VERSION ""

NS_ :

BS_:

BU_: PowertrainControlModule AtmosphericSensor SafetyRestraintSystem2 Aftertreatment_2_GasOutlet Aftertreatment_2_GasIntake DieselPartFilterControl Turbocharger SafetyRestraintSystem1 CabDisplay2 Aftertreatment_1_GasOutlet Aftertreatment_1_GasIntake OnBoardDataLogger OffBoardDiagnosticTool2 OffBoardDiagnosticTool1 FileServer ParkingBrakeController SeatController2 FanDriveController SteeringColumnUnit CommunicationUnitRadio CommunicationUnitSatellite CommunicationUnitCellular PropulsionBatteryCharger ChassisController2 ChassisController1 EngineValveControl AuxiliaryHeater2 AuxiliaryHeater1 ClutchUnit RampControl InformationSystem1 SuspensionSystemController2 OilSensor VehicleDynamicStability ExhaustEmissionController TransmissionDisplay2 TransmissionDisplay1 ClimateControl2 WaterPumpController RearAxleSteeringController LightingOperatorControl SeatController1 IgnitionController2 IgnitionController1 TirePressureController CabController2 CabController1 PneumaticSystemController SuspensionSystemController1 HydraulicPumpController EnduranceBrakingSystem RetarderExhaustEngine2 OnBoardDiagnosticUnit HeadwayController RetarderExhaustEngine1 CabDisplay1 ManagementComputer VirtualTerminal OffVehicleGateway PowerTakeOffFront HitchControl AuxiliaryValveControl BodyController TractorTrailerBridge1 StarterSystem ElectricalSystem VehicleSecurity VehicleNavigation AerodynamicControl ElectricalChargingSystem ClimateControl1 TripRecorder InstrumentCluster SuspensionDriveAxle2 SuspensionDriveAxle1 SuspensionSteerAxle SteeringController FuelSystem CruiseControl RetarderDriveline RetarderEngine BrakesDriveAxle2 BrakesDriveAxle1 BrakesSystemController BrakesSteerAxle AxleDrive2 AxleDrive1 AxleSteering PowerTakeOff ShiftConsoleSecondary ShiftConsolePrimary Transmission2 Transmission1 Engine2 Engine1

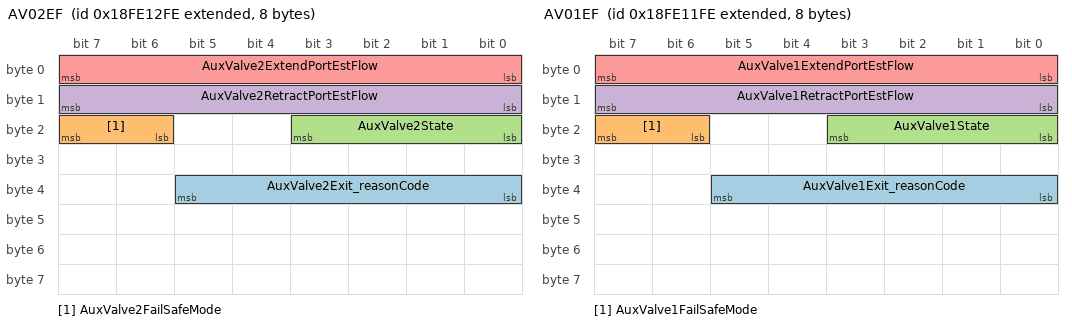
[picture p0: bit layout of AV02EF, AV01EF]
BO_ 2566787838 AV02EF: 8 Vector__XXX
 SG_ AuxValve2Exit_reasonCode : 32|6@1+ (1,0) [0|0] "" Vector__XXX
 SG_ AuxValve2FailSafeMode : 22|2@1+ (1,0) [0|0] "" Vector__XXX
 SG_ AuxValve2State : 16|4@1+ (1,0) [0|0] "" Vector__XXX
 SG_ AuxValve2RetractPortEstFlow : 8|8@1+ (1,0) [0|0] "" Vector__XXX
 SG_ AuxValve2ExtendPortEstFlow : 0|8@1+ (1,0) [0|0] "" Vector__XXX

BO_ 2566787582 AV01EF: 8 Vector__XXX
 SG_ AuxValve1Exit_reasonCode : 32|6@1+ (1,0) [0|0] "" Vector__XXX
 SG_ AuxValve1FailSafeMode : 22|2@1+ (1,0) [0|0] "" Vector__XXX
 SG_ AuxValve1State : 16|4@1+ (1,0) [0|0] "" Vector__XXX
 SG_ AuxValve1RetractPortEstFlow : 8|8@1+ (1,0) [0|0] "" Vector__XXX
 SG_ AuxValve1ExtendPortEstFlow : 0|8@1+ (1,0) [0|0] "" Vector__XXX

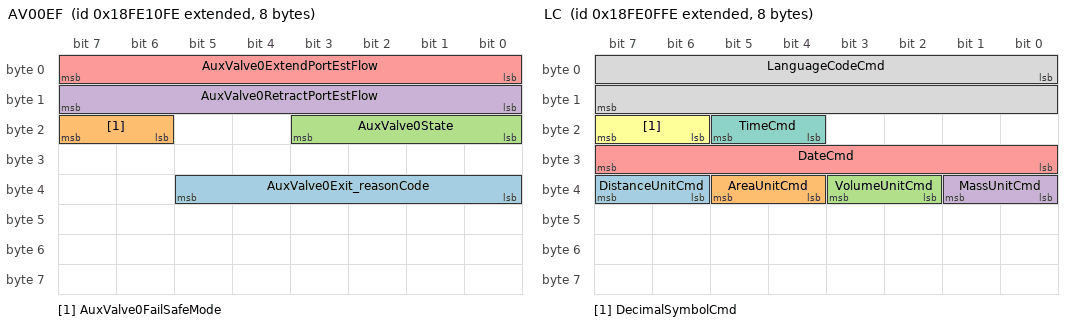
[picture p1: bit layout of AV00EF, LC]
BO_ 2566787326 AV00EF: 8 Vector__XXX
 SG_ AuxValve0Exit_reasonCode : 32|6@1+ (1,0) [0|0] "" Vector__XXX
 SG_ AuxValve0FailSafeMode : 22|2@1+ (1,0) [0|0] "" Vector__XXX
 SG_ AuxValve0State : 16|4@1+ (1,0) [0|0] "" Vector__XXX
 SG_ AuxValve0RetractPortEstFlow : 8|8@1+ (1,0) [0|0] "" Vector__XXX
 SG_ AuxValve0ExtendPortEstFlow : 0|8@1+ (1,0) [0|0] "" Vector__XXX

BO_ 2566787070 LC: 8 Vector__XXX
 SG_ DistanceUnitCmd : 38|2@1+ (1,0) [0|0] "" Vector__XXX
 SG_ AreaUnitCmd : 36|2@1+ (1,0) [0|0] "" Vector__XXX
 SG_ VolumeUnitCmd : 34|2@1+ (1,0) [0|0] "" Vector__XXX
 SG_ MassUnitCmd : 32|2@1+ (1,0) [0|0] "" Vector__XXX
 SG_ DateCmd : 24|8@1+ (1,0) [0|0] "" Vector__XXX
 SG_ DecimalSymbolCmd : 22|2@1+ (1,0) [0|0] "" Vector__XXX
 SG_ TimeCmd : 20|2@1+ (1,0) [0|0] "" Vector__XXX
 SG_ LanguageCodeCmd : 0|16@1+ (1,0) [0|0] "" Vector__XXX

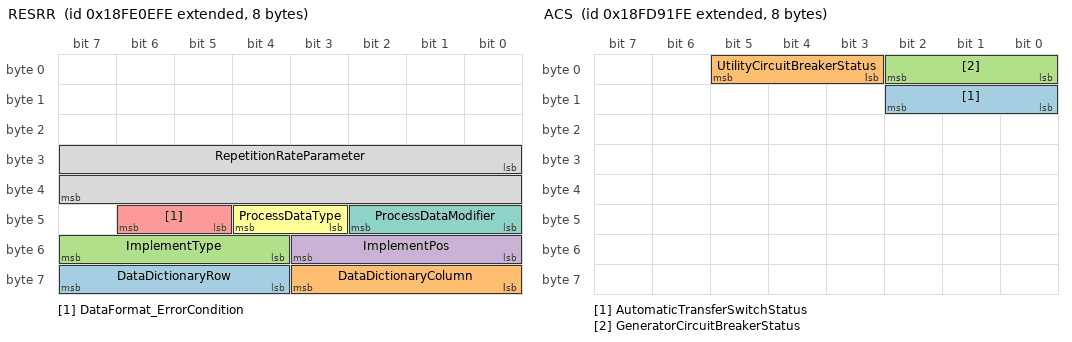
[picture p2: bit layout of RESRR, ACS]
BO_ 2566786814 RESRR: 8 Vector__XXX
 SG_ DataDictionaryRow : 60|4@1+ (1,0) [0|0] "" Vector__XXX
 SG_ DataDictionaryColumn : 56|4@1+ (1,0) [0|0] "" Vector__XXX
 SG_ ImplementType : 52|4@1+ (1,0) [0|0] "" Vector__XXX
 SG_ ImplementPos : 48|4@1+ (1,0) [0|0] "" Vector__XXX
 SG_ DataFormat_ErrorCondition : 45|2@1+ (1,0) [0|0] "" Vector__XXX
 SG_ ProcessDataType : 43|2@1+ (1,0) [0|0] "" Vector__XXX
 SG_ ProcessDataModifier : 40|3@1+ (1,0) [0|0] "" Vector__XXX
 SG_ RepetitionRateParameter : 24|16@1+ (1,0) [0|0] "" Vector__XXX

BO_ 2566786046 IRC: 8 Vector__XXX

BO_ 2566785790 IRCR: 8 Vector__XXX

BO_ 2566785534 TFR: 8 Vector__XXX
 SG_ TrctrFcltyRspLmt_RqstSttsRprting : 27|1@1+ (1,0) [0|0] "" Vector__XXX

BO_ 2566785278 RTF: 8 Vector__XXX
 SG_ TrctrFcltyRqLmt_RqstSttsRporting : 27|1@1+ (1,0) [0|0] "" Vector__XXX

BO_ 2566774526 MAM21: 8 Vector__XXX

BO_ 2566774270 MAM11: 8 Vector__XXX

BO_ 2566770686 WSM: 8 Vector__XXX
 SG_ NumberOfMembers : 0|8@1+ (1,0) [0|0] "" Vector__XXX

BO_ 2566770430 WSMM: 8 Vector__XXX
 SG_ NAMEOfWorkingSetMember : 0|64@1+ (1,0) [0|0] "" Vector__XXX

BO_ 2566761470 RCMS: 8 Vector__XXX
 SG_ PGNOfConfigurableMessageDesired : 8|24@1+ (1,0) [0|16777215] "" Vector__XXX
 SG_ MessageSelectionCtrl : 0|8@1+ (1,0) [0|250] "" Vector__XXX

BO_ 2566754814 ACS: 8 Vector__XXX
 SG_ AutomaticTransferSwitchStatus : 8|3@1+ (1,0) [0|7] "" Vector__XXX
 SG_ UtilityCircuitBreakerStatus : 3|3@1+ (1,0) [0|7] "" Vector__XXX
 SG_ GeneratorCircuitBreakerStatus : 0|3@1+ (1,0) [0|7] "" Vector__XXX

BO_ 2566754302 GTACPP: 8 Vector__XXX
 SG_ GeneratorTotalPercentKVAr : 32|16@1+ (0.0078125,-251) [-251|250.99] "%" Vector__XXX
 SG_ GeneratorTotalPercentKVA : 16|16@1+ (0.0078125,-251) [-251|250.99] "%" Vector__XXX
 SG_ GeneratorTotalPercentKW : 0|16@1+ (0.0078125,-251) [-251|250.99] "%" Vector__XXX

BO_ 2566754046 GTACER: 8 Vector__XXX
 SG_ GeneratorTotalKVArHoursImport : 32|32@1+ (1,0) [0|4211081215] "kVArh" Vector__XXX
 SG_ GeneratorTotalKVArHoursExport : 0|32@1+ (1,0) [0|4211081215] "kVArh" Vector__XXX

BO_ 2566753790 UTACER: 8 Vector__XXX
 SG_ UtilityTotalKVArHoursImport : 32|32@1+ (1,0) [0|4211081215] "kVArh" Vector__XXX
 SG_ UtilityTotalKVArHoursExport : 0|32@1+ (1,0) [0|4211081215] "kVArh" Vector__XXX

BO_ 2566738174 GPM19: 8 Vector__XXX

BO_ 2566737918 GPM26: 8 Vector__XXX

BO_ 2566737662 GPM27: 8 Vector__XXX

BO_ 2566737406 GPM28: 8 Vector__XXX

BO_ 2566737150 GPM29: 8 Vector__XXX

BO_ 2566736894 GPM210: 8 Vector__XXX

BO_ 2566736638 GPM211: 8 Vector__XXX

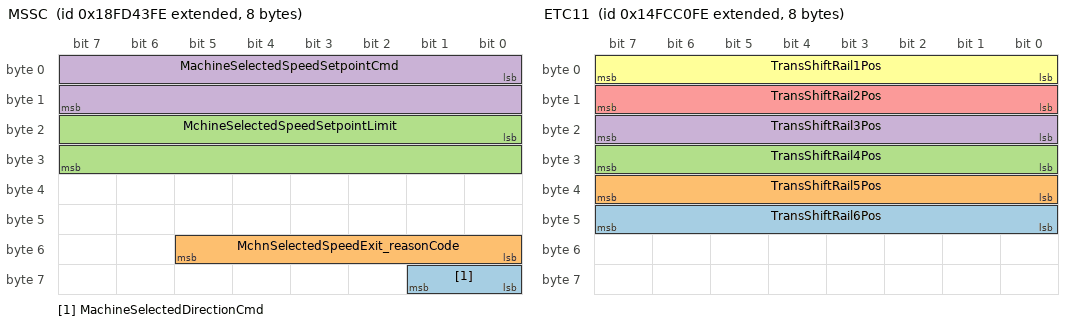
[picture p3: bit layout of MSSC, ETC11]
BO_ 2566734846 MSSC: 8 Vector__XXX
 SG_ MachineSelectedDirectionCmd : 56|2@1+ (1,0) [0|0] "" Vector__XXX
 SG_ MchnSelectedSpeedExit_reasonCode : 48|6@1+ (1,0) [0|0] "" Vector__XXX
 SG_ MchineSelectedSpeedSetpointLimit : 16|16@1+ (1,0) [0|0] "" Vector__XXX
 SG_ MachineSelectedSpeedSetpointCmd : 0|16@1+ (1,0) [0|0] "" Vector__XXX

BO_ 2566734590 ICC: 8 Vector__XXX
 SG_ ISOBUSCmplncCrtfctnMssgeRevision : 47|1@1+ (1,0) [0|0] "" Vector__XXX
 SG_ ISOBUSCmplncCrtfctnRfrenceNumber : 48|16@1+ (1,0) [0|0] "" Vector__XXX
 SG_ ISOBUSCmplncCrtfctonTypeTaskCtrl : 39|1@1+ (1,0) [0|0] "" Vector__XXX
 SG_ ISOBUSCmplncCrtfctnTypTCWrkn4326 : 38|1@1+ (1,0) [0|0] "" Vector__XXX
 SG_ ISOBUSCmplncCrtfctnTypTCWrkngStM : 37|1@1+ (1,0) [0|0] "" Vector__XXX
 SG_ ISOBUSCmplncCrtfctnTypFileServer : 36|1@1+ (1,0) [0|0] "" Vector__XXX
 SG_ ISOBUSCmplncCrtfctnTypGPSRceiver : 35|1@1+ (1,0) [0|0] "" Vector__XXX
 SG_ ISOBUSCmplncCrtfcationTypeMinECU : 31|1@1+ (1,0) [0|0] "" Vector__XXX
 SG_ ISOBUSCmplncCrtfctnTypTECUClass1 : 30|1@1+ (1,0) [0|0] "" Vector__XXX
 SG_ ISOBUSCmplncCrtfctnTypTECUClass2 : 29|1@1+ (1,0) [0|0] "" Vector__XXX
 SG_ ISOBUSCmplncCrtfctnTypTECUClass3 : 28|1@1+ (1,0) [0|0] "" Vector__XXX
 SG_ ISOBUSCmplncCrtfctnTypeClass3ECU : 27|1@1+ (1,0) [0|0] "" Vector__XXX
 SG_ ISOBUSCmplncCrtfctnTypVrtlTrmnal : 26|1@1+ (1,0) [0|0] "" Vector__XXX
 SG_ ISOBUSCmplncCrtfctnTypVTWrkn4323 : 25|1@1+ (1,0) [0|0] "" Vector__XXX
 SG_ ISOBUSCmplncCrtfctnTypVTWrkngStM : 24|1@1+ (1,0) [0|0] "" Vector__XXX
 SG_ ISOBUSCmplncCrtfctonLaboratoryID : 13|11@1+ (1,0) [0|0] "" Vector__XXX
 SG_ ISOBUSCmplncCrtfctLaboratoryType : 9|3@1+ (1,0) [0|0] "" Vector__XXX
 SG_ ISOBUSCmplnceCertificateRevision : 6|3@1+ (1,0) [0|0] "" Vector__XXX
 SG_ ISOBUSCmplianceCertificationYear : 0|6@1+ (1,0) [0|0] "" Vector__XXX

BO_ 2566730494 TBD: 8 Vector__XXX

BO_ 2566718462 IOS: 8 Vector__XXX
 SG_ ImplementOperatingStateCmd : 56|2@1+ (1,0) [0|0] "" Vector__XXX

BO_ 2566718206 AISO: 8 Vector__XXX
 SG_ StpAllImplmntOprtnsTrnstonNumber : 48|8@1+ (1,0) [0|0] "" Vector__XXX
 SG_ AllImplmntStpOprtngOprtnsSwtchSt : 56|2@1+ (1,0) [0|0] "" Vector__XXX

BO_ 2566706430 XCP_ID: 8 Vector__XXX

BO_ 2566704894 DSC: 8 Vector__XXX

BO_ 2566704638 DSS: 8 Vector__XXX

BO_ 2566701566 TRF3: 8 Vector__XXX
 SG_ TransOilTransCoolerOutletTemp : 8|8@1+ (1,-40) [-40|210] "°C" Vector__XXX
 SG_ TransClutch2Press : 0|8@1+ (16,0) [0|4000] "kPa" Vector__XXX

BO_ 2499592446 ETC11: 8 Vector__XXX
 SG_ TransShiftRail6Pos : 40|8@1+ (0.4,0) [0|100] "%" Vector__XXX
 SG_ TransShiftRail5Pos : 32|8@1+ (0.4,0) [0|100] "%" Vector__XXX
 SG_ TransShiftRail4Pos : 24|8@1+ (0.4,0) [0|100] "%" Vector__XXX
 SG_ TransShiftRail3Pos : 16|8@1+ (0.4,0) [0|100] "%" Vector__XXX
 SG_ TransShiftRail2Pos : 8|8@1+ (0.4,0) [0|100] "%" Vector__XXX
 SG_ TransShiftRail1Pos : 0|8@1+ (0.4,0) [0|100] "%" Vector__XXX

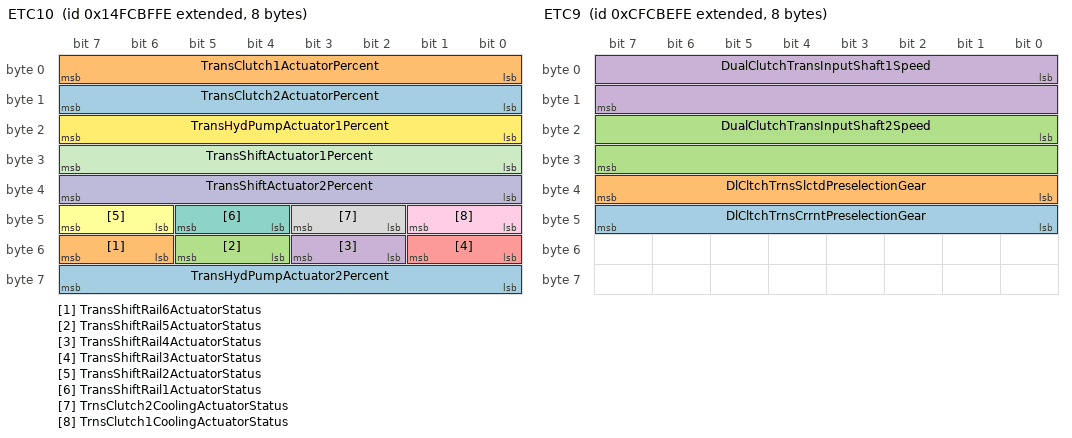
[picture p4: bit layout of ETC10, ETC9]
BO_ 2499592190 ETC10: 8 Vector__XXX
 SG_ TransHydPumpActuator2Percent : 56|8@1+ (0.4,0) [0|100] "%" Vector__XXX
 SG_ TransShiftRail6ActuatorStatus : 54|2@1+ (1,0) [0|3] "" Vector__XXX
 SG_ TransShiftRail5ActuatorStatus : 52|2@1+ (1,0) [0|3] "" Vector__XXX
 SG_ TransShiftRail4ActuatorStatus : 50|2@1+ (1,0) [0|3] "" Vector__XXX
 SG_ TransShiftRail3ActuatorStatus : 48|2@1+ (1,0) [0|3] "" Vector__XXX
 SG_ TransShiftRail2ActuatorStatus : 46|2@1+ (1,0) [0|3] "" Vector__XXX
 SG_ TransShiftRail1ActuatorStatus : 44|2@1+ (1,0) [0|3] "" Vector__XXX
 SG_ TrnsClutch2CoolingActuatorStatus : 42|2@1+ (1,0) [0|3] "" Vector__XXX
 SG_ TrnsClutch1CoolingActuatorStatus : 40|2@1+ (1,0) [0|3] "" Vector__XXX
 SG_ TransShiftActuator2Percent : 32|8@1+ (0.4,0) [0|100] "%" Vector__XXX
 SG_ TransShiftActuator1Percent : 24|8@1+ (0.4,0) [0|100] "%" Vector__XXX
 SG_ TransHydPumpActuator1Percent : 16|8@1+ (0.4,0) [0|100] "%" Vector__XXX
 SG_ TransClutch2ActuatorPercent : 8|8@1+ (0.4,0) [0|100] "%" Vector__XXX
 SG_ TransClutch1ActuatorPercent : 0|8@1+ (0.4,0) [0|100] "%" Vector__XXX

BO_ 2365374206 ETC9: 8 Vector__XXX
 SG_ DlCltchTrnsCrrntPreselectionGear : 40|8@1+ (1,-125) [-125|125] "" Vector__XXX
 SG_ DlCltchTrnsSlctdPreselectionGear : 32|8@1+ (1,-125) [-125|125] "" Vector__XXX
 SG_ DualClutchTransInputShaft2Speed : 16|16@1+ (0.125,0) [0|8031.875] "rpm" Vector__XXX
 SG_ DualClutchTransInputShaft1Speed : 0|16@1+ (0.125,0) [0|8031.875] "rpm" Vector__XXX

BO_ 2566700542 A1SCRSI2: 8 Vector__XXX
 SG_ TripDEF : 32|32@1+ (0.05,0) [0|210554060.75] "L" Vector__XXX
 SG_ TotalDEFUsed : 0|32@1+ (0.5,0) [0|2105540607.5] "L" Vector__XXX

BO_ 2566700286 A2SCRSI2: 8 Vector__XXX
 SG_ TotalDEFUsed : 0|32@1+ (0.5,0) [0|2105540607.5] "L" Vector__XXX

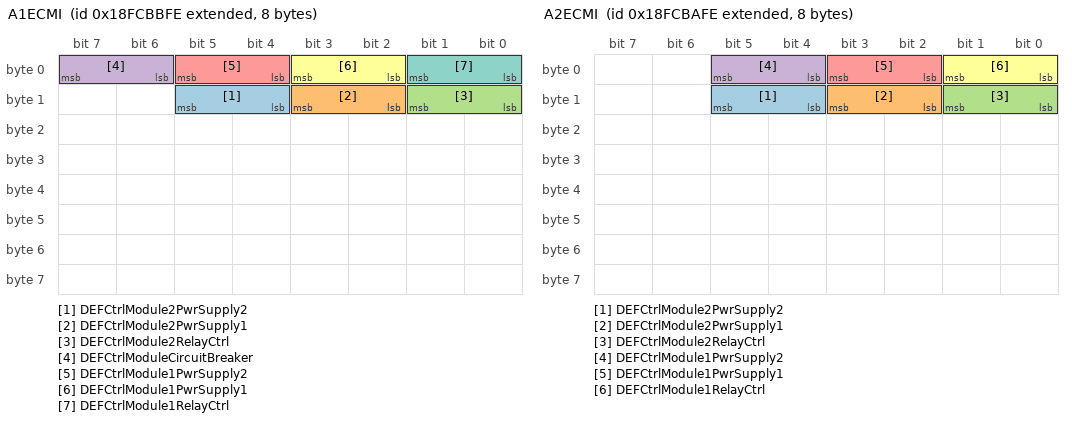
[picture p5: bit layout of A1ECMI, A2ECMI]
BO_ 2566700030 A1ECMI: 8 Vector__XXX
 SG_ DEFCtrlModule2PwrSupply2 : 12|2@1+ (1,0) [0|3] "" Vector__XXX
 SG_ DEFCtrlModule2PwrSupply1 : 10|2@1+ (1,0) [0|3] "" Vector__XXX
 SG_ DEFCtrlModule2RelayCtrl : 8|2@1+ (1,0) [0|3] "" Vector__XXX
 SG_ DEFCtrlModuleCircuitBreaker : 6|2@1+ (1,0) [0|3] "" Vector__XXX
 SG_ DEFCtrlModule1PwrSupply2 : 4|2@1+ (1,0) [0|3] "" Vector__XXX
 SG_ DEFCtrlModule1PwrSupply1 : 2|2@1+ (1,0) [0|3] "" Vector__XXX
 SG_ DEFCtrlModule1RelayCtrl : 0|2@1+ (1,0) [0|3] "" Vector__XXX

BO_ 2566699774 A2ECMI: 8 Vector__XXX
 SG_ DEFCtrlModule2PwrSupply2 : 12|2@1+ (1,0) [0|3] "" Vector__XXX
 SG_ DEFCtrlModule2PwrSupply1 : 10|2@1+ (1,0) [0|3] "" Vector__XXX
 SG_ DEFCtrlModule2RelayCtrl : 8|2@1+ (1,0) [0|3] "" Vector__XXX
 SG_ DEFCtrlModule1PwrSupply2 : 4|2@1+ (1,0) [0|3] "" Vector__XXX
 SG_ DEFCtrlModule1PwrSupply1 : 2|2@1+ (1,0) [0|3] "" Vector__XXX
 SG_ DEFCtrlModule1RelayCtrl : 0|2@1+ (1,0) [0|3] "" Vector__XXX

BO_ 2566699518 AT1S2: 8 Vector__XXX
 SG_ SCRSysTimeSinceLastSysCleanEvent : 32|32@1+ (1,0) [0|4211081215] "s" Vector__XXX
 SG_ DPFTimeToNextActiveRegen : 0|32@1+ (1,0) [0|4211081215] "s" Vector__XXX

BO_ 2566699262 AT2S2: 8 Vector__XXX
 SG_ SCRSysTimeSinceLastSysCleanEvent : 32|32@1+ (1,0) [0|4211081215] "s" Vector__XXX
 SG_ DPFTimeToNextActiveRegen : 0|32@1+ (1,0) [0|4211081215] "s" Vector__XXX

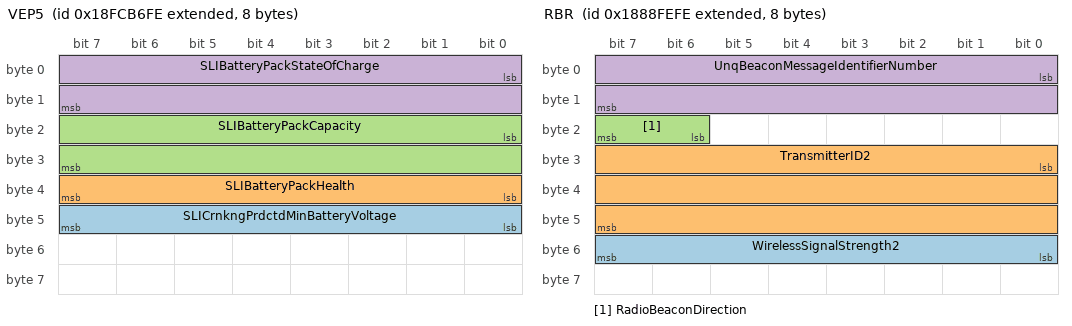
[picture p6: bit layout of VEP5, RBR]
BO_ 2566698750 VEP5: 8 Vector__XXX
 SG_ SLICrnkngPrdctdMinBatteryVoltage : 40|8@1+ (0.2,0) [0|50] "V" Vector__XXX
 SG_ SLIBatteryPackHealth : 32|8@1+ (0.5,0) [0|100] "%" Vector__XXX
 SG_ SLIBatteryPackCapacity : 16|16@1+ (1,0) [0|64255] "Ah" Vector__XXX
 SG_ SLIBatteryPackStateOfCharge : 0|16@1+ (0.0025,0) [0|160.6375] "%" Vector__XXX

BO_ 2566698494 FPOS: 8 Vector__XXX
 SG_ FusedOutput29 : 62|2@1+ (1,0) [0|3] "" Vector__XXX
 SG_ FusedOutput30 : 60|2@1+ (1,0) [0|3] "" Vector__XXX
 SG_ FusedOutput31 : 58|2@1+ (1,0) [0|3] "" Vector__XXX
 SG_ FusedOutput32 : 56|2@1+ (1,0) [0|3] "" Vector__XXX
 SG_ FusedOutput25 : 54|2@1+ (1,0) [0|3] "" Vector__XXX
 SG_ FusedOutput26 : 52|2@1+ (1,0) [0|3] "" Vector__XXX
 SG_ FusedOutput27 : 50|2@1+ (1,0) [0|3] "" Vector__XXX
 SG_ FusedOutput28 : 48|2@1+ (1,0) [0|3] "" Vector__XXX
 SG_ FusedOutput21 : 46|2@1+ (1,0) [0|3] "" Vector__XXX
 SG_ FusedOutput22 : 44|2@1+ (1,0) [0|3] "" Vector__XXX
 SG_ FusedOutput23 : 42|2@1+ (1,0) [0|3] "" Vector__XXX
 SG_ FusedOutput24 : 40|2@1+ (1,0) [0|3] "" Vector__XXX
 SG_ FusedOutput17 : 38|2@1+ (1,0) [0|3] "" Vector__XXX
 SG_ FusedOutput18 : 36|2@1+ (1,0) [0|3] "" Vector__XXX
 SG_ FusedOutput19 : 34|2@1+ (1,0) [0|3] "" Vector__XXX
 SG_ FusedOutput20 : 32|2@1+ (1,0) [0|3] "" Vector__XXX
 SG_ FusedOutput13 : 30|2@1+ (1,0) [0|3] "" Vector__XXX
 SG_ FusedOutput14 : 27|2@1+ (1,0) [0|3] "" Vector__XXX
 SG_ FusedOutput15 : 26|2@1+ (1,0) [0|3] "" Vector__XXX
 SG_ FusedOutput16 : 24|2@1+ (1,0) [0|3] "" Vector__XXX
 SG_ FusedOutput9 : 22|2@1+ (1,0) [0|3] "" Vector__XXX
 SG_ FusedOutput10 : 20|2@1+ (1,0) [0|3] "" Vector__XXX
 SG_ FusedOutput11 : 18|2@1+ (1,0) [0|3] "" Vector__XXX
 SG_ FusedOutput12 : 16|2@1+ (1,0) [0|3] "" Vector__XXX
 SG_ FusedOutput5 : 14|2@1+ (1,0) [0|3] "" Vector__XXX
 SG_ FusedOutput6 : 12|2@1+ (1,0) [0|3] "" Vector__XXX
 SG_ FusedOutput7 : 10|2@1+ (1,0) [0|3] "" Vector__XXX
 SG_ FusedOutput8 : 8|2@1+ (1,0) [0|3] "" Vector__XXX
 SG_ FusedOutput1 : 6|2@1+ (1,0) [0|3] "" Vector__XXX
 SG_ FusedOutput2 : 4|2@1+ (1,0) [0|3] "" Vector__XXX
 SG_ FusedOutput3 : 2|2@1+ (1,0) [0|3] "" Vector__XXX
 SG_ FusedOutput4 : 0|2@1+ (1,0) [0|3] "" Vector__XXX

BO_ 2559115006 RBR: 8 Vector__XXX
 SG_ WirelessSignalStrength2 : 48|8@1+ (0.5,-125) [-125|0] "dBm" Vector__XXX
 SG_ TransmitterID2 : 24|24@1+ (1,0) [0|16449635] "" Vector__XXX
 SG_ RadioBeaconDirection : 22|2@1+ (1,0) [0|3] "" Vector__XXX
 SG_ UnqBeaconMessageIdentifierNumber : 0|16@1+ (1,0) [0|64255] "" Vector__XXX

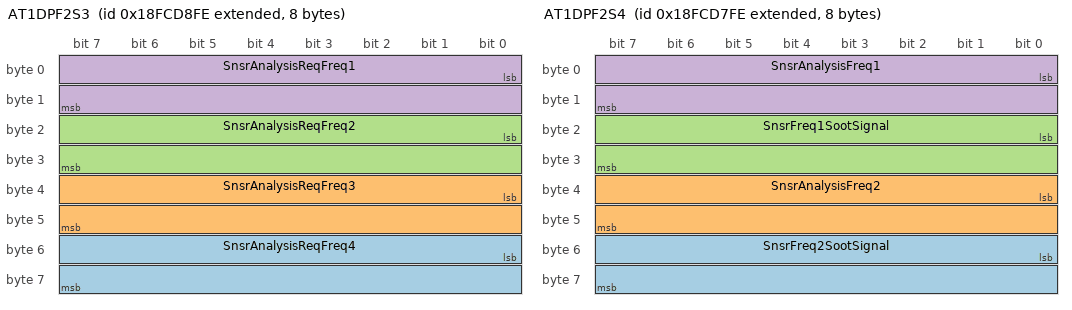
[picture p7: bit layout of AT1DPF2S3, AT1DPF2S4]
BO_ 2566707454 AT1DPF2S3: 8 Vector__XXX
 SG_ SnsrAnalysisReqFreq4 : 48|16@1+ (0.1,0) [0|6425.5] "MHz" Vector__XXX
 SG_ SnsrAnalysisReqFreq3 : 32|16@1+ (0.1,0) [0|6425.5] "MHz" Vector__XXX
 SG_ SnsrAnalysisReqFreq2 : 16|16@1+ (0.1,0) [0|6425.5] "MHz" Vector__XXX
 SG_ SnsrAnalysisReqFreq1 : 0|16@1+ (0.1,0) [0|6425.5] "MHz" Vector__XXX

BO_ 2566707198 AT1DPF2S4: 8 Vector__XXX
 SG_ SnsrFreq2SootSignal : 48|16@1+ (0.0025,0) [0|160.6375] "%" Vector__XXX
 SG_ SnsrAnalysisFreq2 : 32|16@1+ (0.1,0) [0|6425.5] "MHz" Vector__XXX
 SG_ SnsrFreq1SootSignal : 16|16@1+ (0.0025,0) [0|160.6375] "%" Vector__XXX
 SG_ SnsrAnalysisFreq1 : 0|16@1+ (0.1,0) [0|6425.5] "MHz" Vector__XXX

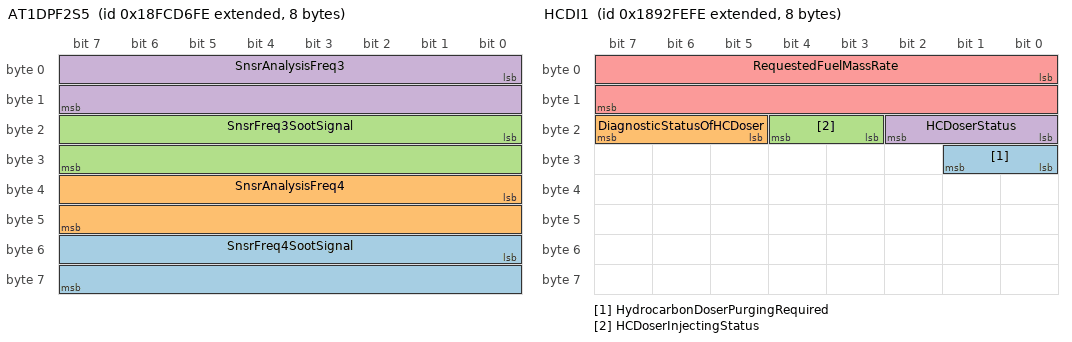
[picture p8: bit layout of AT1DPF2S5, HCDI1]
BO_ 2566706942 AT1DPF2S5: 8 Vector__XXX
 SG_ SnsrFreq4SootSignal : 48|16@1+ (0.0025,0) [0|160.6375] "%" Vector__XXX
 SG_ SnsrAnalysisFreq4 : 32|16@1+ (0.1,0) [0|6425.5] "MHz" Vector__XXX
 SG_ SnsrFreq3SootSignal : 16|16@1+ (0.0025,0) [0|160.6375] "%" Vector__XXX
 SG_ SnsrAnalysisFreq3 : 0|16@1+ (0.1,0) [0|6425.5] "MHz" Vector__XXX

BO_ 2559770366 HCDI1: 8 Vector__XXX
 SG_ HydrocarbonDoserPurgingRequired : 24|2@1+ (1,0) [0|3] "" Vector__XXX
 SG_ DiagnosticStatusOfHCDoser : 21|3@1+ (1,0) [0|7] "" Vector__XXX
 SG_ HCDoserInjectingStatus : 19|2@1+ (1,0) [0|3] "" Vector__XXX
 SG_ HCDoserStatus : 16|3@1+ (1,0) [0|7] "" Vector__XXX
 SG_ RequestedFuelMassRate : 0|16@1+ (0.05,0) [0|3212.75] "g/min" Vector__XXX

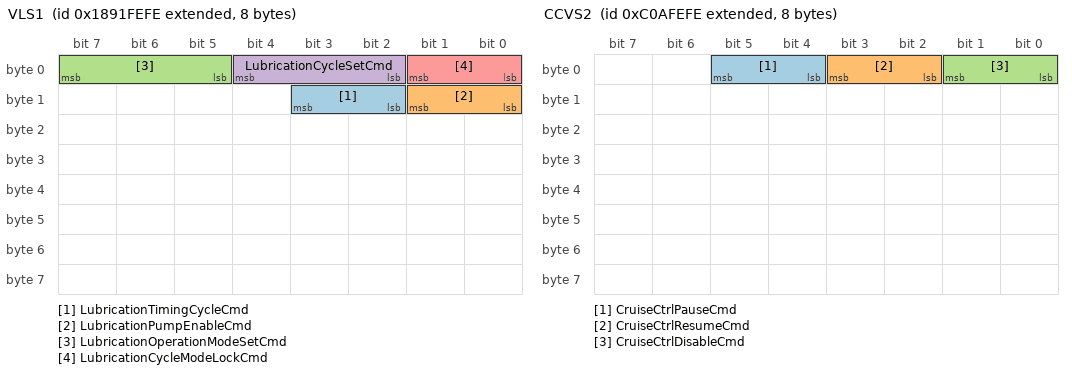
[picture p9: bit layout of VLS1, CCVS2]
BO_ 2559704830 VLS1: 8 Vector__XXX
 SG_ LubricationTimingCycleCmd : 10|2@1+ (1,0) [0|3] "" Vector__XXX
 SG_ LubricationPumpEnableCmd : 8|2@1+ (1,0) [0|3] "" Vector__XXX
 SG_ LubricationOperationModeSetCmd : 5|3@1+ (1,0) [0|7] "" Vector__XXX
 SG_ LubricationCycleSetCmd : 2|3@1+ (1,0) [0|7] "" Vector__XXX
 SG_ LubricationCycleModeLockCmd : 0|2@1+ (1,0) [0|3] "" Vector__XXX

BO_ 2559639294 SFC: 8 Vector__XXX
 SG_ SupplementalFanPowerHold : 24|2@1+ (1,0) [0|3] "" Vector__XXX
 SG_ SupplementalFanSpeedCmd : 8|16@1+ (0.5,0) [0|32127.5] "rpm" Vector__XXX
 SG_ SupplementalFanDirectionCmd : 2|2@1+ (1,0) [0|3] "" Vector__XXX
 SG_ SupplementalFanEnableCmd : 0|2@1+ (1,0) [0|3] "" Vector__XXX

BO_ 2559573758 ECC: 8 Vector__XXX
 SG_ ClntLvlEngPrtctnShtdwnOvrrideCmd : 0|2@1+ (1,0) [0|3] "" Vector__XXX

BO_ 2349530878 CCVS2: 8 Vector__XXX
 SG_ CruiseCtrlPauseCmd : 4|2@1+ (1,0) [0|3] "" Vector__XXX
 SG_ CruiseCtrlResumeCmd : 2|2@1+ (1,0) [0|3] "" Vector__XXX
 SG_ CruiseCtrlDisableCmd : 0|2@1+ (1,0) [0|3] "" Vector__XXX

BO_ 2566698238 SPOS: 8 Vector__XXX
 SG_ SwitchedOutput29 : 62|2@1+ (1,0) [0|3] "" Vector__XXX
 SG_ SwitchedOutput30 : 60|2@1+ (1,0) [0|3] "" Vector__XXX
 SG_ SwitchedOutput31 : 58|2@1+ (1,0) [0|3] "" Vector__XXX
 SG_ SwitchedOutput32 : 56|2@1+ (1,0) [0|3] "" Vector__XXX
 SG_ SwitchedOutput25 : 54|2@1+ (1,0) [0|3] "" Vector__XXX
 SG_ SwitchedOutput26 : 52|2@1+ (1,0) [0|3] "" Vector__XXX
 SG_ SwitchedOutput27 : 50|2@1+ (1,0) [0|3] "" Vector__XXX
 SG_ SwitchedOutput28 : 48|2@1+ (1,0) [0|3] "" Vector__XXX
 SG_ SwitchedOutput21 : 46|2@1+ (1,0) [0|3] "" Vector__XXX
 SG_ SwitchedOutput22 : 44|2@1+ (1,0) [0|3] "" Vector__XXX
 SG_ SwitchedOutput23 : 42|2@1+ (1,0) [0|3] "" Vector__XXX
 SG_ SwitchedOutput24 : 40|2@1+ (1,0) [0|3] "" Vector__XXX
 SG_ SwitchedOutput17 : 38|2@1+ (1,0) [0|3] "" Vector__XXX
 SG_ SwitchedOutput18 : 36|2@1+ (1,0) [0|3] "" Vector__XXX
 SG_ SwitchedOutput19 : 34|2@1+ (1,0) [0|3] "" Vector__XXX
 SG_ SwitchedOutput20 : 32|2@1+ (1,0) [0|3] "" Vector__XXX
 SG_ SwitchedOutput13 : 30|2@1+ (1,0) [0|3] "" Vector__XXX
 SG_ SwitchedOutput14 : 27|2@1+ (1,0) [0|3] "" Vector__XXX
 SG_ SwitchedOutput15 : 26|2@1+ (1,0) [0|3] "" Vector__XXX
 SG_ SwitchedOutput16 : 24|2@1+ (1,0) [0|3] "" Vector__XXX
 SG_ SwitchedOutput9 : 22|2@1+ (1,0) [0|3] "" Vector__XXX
 SG_ SwitchedOutput10 : 20|2@1+ (1,0) [0|3] "" Vector__XXX
 SG_ SwitchedOutput11 : 18|2@1+ (1,0) [0|3] "" Vector__XXX
 SG_ SwitchedOutput12 : 16|2@1+ (1,0) [0|3] "" Vector__XXX
 SG_ SwitchedOutput5 : 14|2@1+ (1,0) [0|3] "" Vector__XXX
 SG_ SwitchedOutput6 : 12|2@1+ (1,0) [0|3] "" Vector__XXX
 SG_ SwitchedOutput7 : 10|2@1+ (1,0) [0|3] "" Vector__XXX
 SG_ SwitchedOutput8 : 8|2@1+ (1,0) [0|3] "" Vector__XXX
 SG_ SwitchedOutput1 : 6|2@1+ (1,0) [0|3] "" Vector__XXX
 SG_ SwitchedOutput2 : 4|2@1+ (1,0) [0|3] "" Vector__XXX
 SG_ SwitchedOutput3 : 2|2@1+ (1,0) [0|3] "" Vector__XXX
 SG_ SwitchedOutput4 : 0|2@1+ (1,0) [0|3] "" Vector__XXX

BO_ 2566697982 FPOC: 64 Vector__XXX
 SG_ FusedOutput32Current : 496|16@1+ (0.005,0) [0|321.275] "A" Vector__XXX
 SG_ FusedOutput31Current : 480|16@1+ (0.005,0) [0|321.275] "A" Vector__XXX
 SG_ FusedOutput30Current : 464|16@1+ (0.005,0) [0|321.275] "A" Vector__XXX
 SG_ FusedOutput29Current : 448|16@1+ (0.005,0) [0|321.275] "A" Vector__XXX
 SG_ FusedOutput28Current : 432|16@1+ (0.005,0) [0|321.275] "A" Vector__XXX
 SG_ FusedOutput27Current : 416|16@1+ (0.005,0) [0|321.275] "A" Vector__XXX
 SG_ FusedOutput26Current : 400|16@1+ (0.005,0) [0|321.275] "A" Vector__XXX
 SG_ FusedOutput25Current : 384|16@1+ (0.005,0) [0|321.275] "A" Vector__XXX
 SG_ FusedOutput24Current : 368|16@1+ (0.005,0) [0|321.275] "A" Vector__XXX
 SG_ FusedOutput23Current : 352|16@1+ (0.005,0) [0|321.275] "A" Vector__XXX
 SG_ FusedOutput22Current : 336|16@1+ (0.005,0) [0|321.275] "A" Vector__XXX
 SG_ FusedOutput21Current : 320|16@1+ (0.005,0) [0|321.275] "A" Vector__XXX
 SG_ FusedOutput20Current : 304|16@1+ (0.005,0) [0|321.275] "A" Vector__XXX
 SG_ FusedOutput19Current : 288|16@1+ (0.005,0) [0|321.275] "A" Vector__XXX
 SG_ FusedOutput18Current : 272|16@1+ (0.005,0) [0|321.275] "A" Vector__XXX
 SG_ FusedOutput17Current : 256|16@1+ (0.005,0) [0|321.275] "A" Vector__XXX
 SG_ FusedOutput16Current : 240|16@1+ (0.005,0) [0|321.275] "A" Vector__XXX
 SG_ FusedOutput15Current : 224|16@1+ (0.005,0) [0|321.275] "A" Vector__XXX
 SG_ FusedOutput14Current : 208|16@1+ (0.005,0) [0|321.275] "A" Vector__XXX
 SG_ FusedOutput13Current : 192|16@1+ (0.005,0) [0|321.275] "A" Vector__XXX
 SG_ FusedOutput12Current : 176|16@1+ (0.005,0) [0|321.275] "A" Vector__XXX
 SG_ FusedOutput11Current : 160|16@1+ (0.005,0) [0|321.275] "A" Vector__XXX
 SG_ FusedOutput10Current : 144|16@1+ (0.005,0) [0|321.275] "A" Vector__XXX
 SG_ FusedOutput9Current : 128|16@1+ (0.005,0) [0|321.275] "A" Vector__XXX
 SG_ FusedOutput8Current : 112|16@1+ (0.005,0) [0|321.275] "A" Vector__XXX
 SG_ FusedOutput7Current : 96|16@1+ (0.005,0) [0|321.275] "A" Vector__XXX
 SG_ FusedOutput6Current : 80|16@1+ (0.005,0) [0|321.275] "A" Vector__XXX
 SG_ FusedOutput5Current : 64|16@1+ (0.005,0) [0|321.275] "A" Vector__XXX
 SG_ FusedOutput4Current : 48|16@1+ (0.005,0) [0|321.275] "A" Vector__XXX
 SG_ FusedOutput3Current : 32|16@1+ (0.005,0) [0|321.275] "A" Vector__XXX
 SG_ FusedOutput2Current : 16|16@1+ (0.005,0) [0|321.275] "A" Vector__XXX
 SG_ FusedOutput1Current : 0|16@1+ (0.005,0) [0|321.275] "A" Vector__XXX

BO_ 2566697726 SPOC1: 64 Vector__XXX
 SG_ SwitchedOutput32Current : 496|16@1+ (0.005,0) [0|321.275] "A" Vector__XXX
 SG_ SwitchedOutput31Current : 480|16@1+ (0.005,0) [0|321.275] "A" Vector__XXX
 SG_ SwitchedOutput30Current : 464|16@1+ (0.005,0) [0|321.275] "A" Vector__XXX
 SG_ SwitchedOutput29Current : 448|16@1+ (0.005,0) [0|321.275] "A" Vector__XXX
 SG_ SwitchedOutput28Current : 432|16@1+ (0.005,0) [0|321.275] "A" Vector__XXX
 SG_ SwitchedOutput27Current : 416|16@1+ (0.005,0) [0|321.275] "A" Vector__XXX
 SG_ SwitchedOutput26Current : 400|16@1+ (0.005,0) [0|321.275] "A" Vector__XXX
 SG_ SwitchedOutput25Current : 384|16@1+ (0.005,0) [0|321.275] "A" Vector__XXX
 SG_ SwitchedOutput24Current : 368|16@1+ (0.005,0) [0|321.275] "A" Vector__XXX
 SG_ SwitchedOutput23Current : 352|16@1+ (0.005,0) [0|321.275] "A" Vector__XXX
 SG_ SwitchedOutput22Current : 336|16@1+ (0.005,0) [0|321.275] "A" Vector__XXX
 SG_ SwitchedOutput21Current : 320|16@1+ (0.005,0) [0|321.275] "A" Vector__XXX
 SG_ SwitchedOutput20Current : 304|16@1+ (0.005,0) [0|321.275] "A" Vector__XXX
 SG_ SwitchedOutput19Current : 288|16@1+ (0.005,0) [0|321.275] "A" Vector__XXX
 SG_ SwitchedOutput18Current : 272|16@1+ (0.005,0) [0|321.275] "A" Vector__XXX
 SG_ SwitchedOutput17Current : 256|16@1+ (0.005,0) [0|321.275] "A" Vector__XXX
 SG_ SwitchedOutput16Current : 240|16@1+ (0.005,0) [0|321.275] "A" Vector__XXX
 SG_ SwitchedOutput15Current : 224|16@1+ (0.005,0) [0|321.275] "A" Vector__XXX
 SG_ SwitchedOutput14Current : 208|16@1+ (0.005,0) [0|321.275] "A" Vector__XXX
 SG_ SwitchedOutput13Current : 192|16@1+ (0.005,0) [0|321.275] "A" Vector__XXX
 SG_ SwitchedOutput12Current : 176|16@1+ (0.005,0) [0|321.275] "A" Vector__XXX
 SG_ SwitchedOutput11Current : 160|16@1+ (0.005,0) [0|321.275] "A" Vector__XXX
 SG_ SwitchedOutput10Current : 144|16@1+ (0.005,0) [0|321.275] "A" Vector__XXX
 SG_ SwitchedOutput9Current : 128|16@1+ (0.005,0) [0|321.275] "A" Vector__XXX
 SG_ SwitchedOutput8Current : 112|16@1+ (0.005,0) [0|321.275] "A" Vector__XXX
 SG_ SwitchedOutput7Current : 96|16@1+ (0.005,0) [0|321.275] "A" Vector__XXX
 SG_ SwitchedOutput6Current : 80|16@1+ (0.005,0) [0|321.275] "A" Vector__XXX
 SG_ SwitchedOutput5Current : 64|16@1+ (0.005,0) [0|321.275] "A" Vector__XXX
 SG_ SwitchedOutput4Current : 48|16@1+ (0.005,0) [0|321.275] "A" Vector__XXX
 SG_ SwitchedOutput3Current : 32|16@1+ (0.005,0) [0|321.275] "A" Vector__XXX
 SG_ SwitchedOutput2Current : 16|16@1+ (0.005,0) [0|321.275] "A" Vector__XXX
 SG_ SwitchedOutput1Current : 0|16@1+ (0.005,0) [0|321.275] "A" Vector__XXX

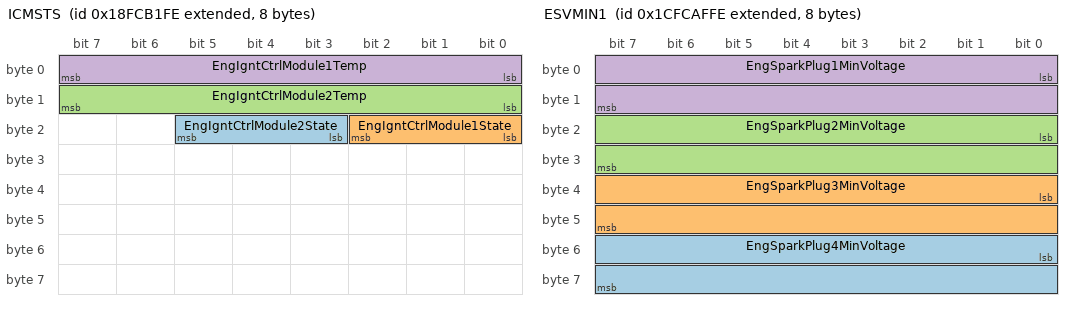
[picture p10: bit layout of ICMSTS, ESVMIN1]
BO_ 2566697470 ICMSTS: 8 Vector__XXX
 SG_ EngIgntCtrlModule2State : 19|3@1+ (1,0) [0|7] "" Vector__XXX
 SG_ EngIgntCtrlModule1State : 16|3@1+ (1,0) [0|7] "" Vector__XXX
 SG_ EngIgntCtrlModule2Temp : 8|8@1+ (1,-40) [-40|210] "°C" Vector__XXX
 SG_ EngIgntCtrlModule1Temp : 0|8@1+ (1,-40) [-40|210] "°C" Vector__XXX

BO_ 2633806078 EICMH: 8 Vector__XXX
 SG_ EngIgntCtrlModule2TimeRemaining : 32|32@1+ (0.05,0) [0|210554060.75] "h" Vector__XXX
 SG_ EngIgntCtrlModule1TimeRemaining : 0|32@1+ (0.05,0) [0|210554060.75] "h" Vector__XXX

BO_ 2633805822 ESVMIN1: 8 Vector__XXX
 SG_ EngSparkPlug4MinVoltage : 48|16@1+ (1,0) [0|64255] "V" Vector__XXX
 SG_ EngSparkPlug3MinVoltage : 32|16@1+ (1,0) [0|64255] "V" Vector__XXX
 SG_ EngSparkPlug2MinVoltage : 16|16@1+ (1,0) [0|64255] "V" Vector__XXX
 SG_ EngSparkPlug1MinVoltage : 0|16@1+ (1,0) [0|64255] "V" Vector__XXX

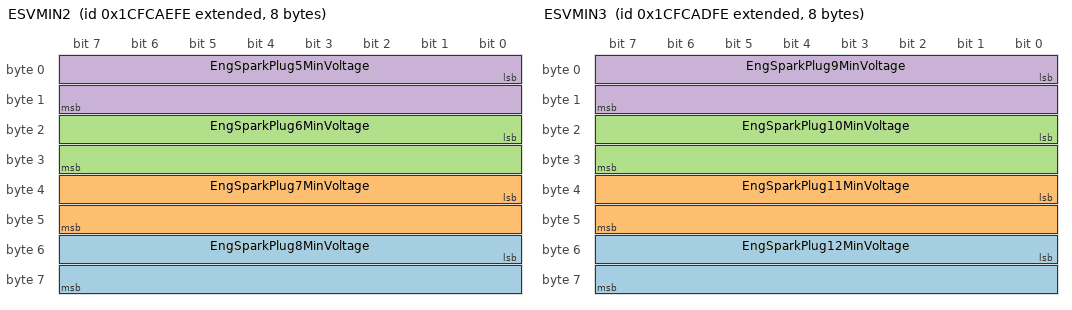
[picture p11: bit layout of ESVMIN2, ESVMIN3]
BO_ 2633805566 ESVMIN2: 8 Vector__XXX
 SG_ EngSparkPlug8MinVoltage : 48|16@1+ (1,0) [0|64255] "V" Vector__XXX
 SG_ EngSparkPlug7MinVoltage : 32|16@1+ (1,0) [0|64255] "V" Vector__XXX
 SG_ EngSparkPlug6MinVoltage : 16|16@1+ (1,0) [0|64255] "V" Vector__XXX
 SG_ EngSparkPlug5MinVoltage : 0|16@1+ (1,0) [0|64255] "V" Vector__XXX

BO_ 2633805310 ESVMIN3: 8 Vector__XXX
 SG_ EngSparkPlug12MinVoltage : 48|16@1+ (1,0) [0|64255] "V" Vector__XXX
 SG_ EngSparkPlug11MinVoltage : 32|16@1+ (1,0) [0|64255] "V" Vector__XXX
 SG_ EngSparkPlug10MinVoltage : 16|16@1+ (1,0) [0|64255] "V" Vector__XXX
 SG_ EngSparkPlug9MinVoltage : 0|16@1+ (1,0) [0|64255] "V" Vector__XXX

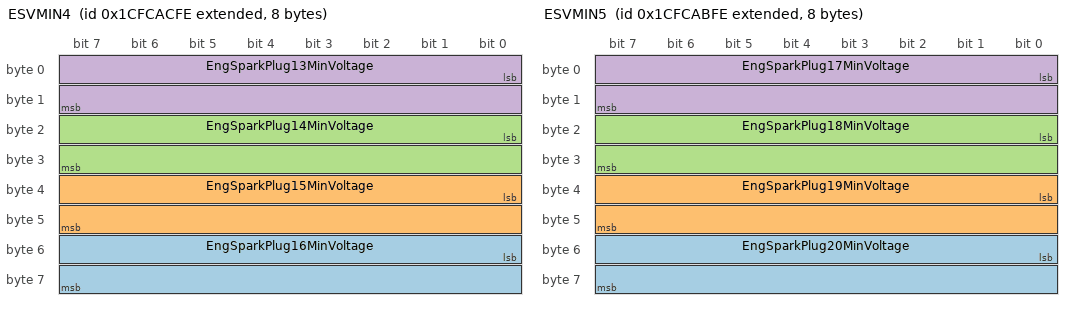
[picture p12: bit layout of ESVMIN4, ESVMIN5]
BO_ 2633805054 ESVMIN4: 8 Vector__XXX
 SG_ EngSparkPlug16MinVoltage : 48|16@1+ (1,0) [0|64255] "V" Vector__XXX
 SG_ EngSparkPlug15MinVoltage : 32|16@1+ (1,0) [0|64255] "V" Vector__XXX
 SG_ EngSparkPlug14MinVoltage : 16|16@1+ (1,0) [0|64255] "V" Vector__XXX
 SG_ EngSparkPlug13MinVoltage : 0|16@1+ (1,0) [0|64255] "V" Vector__XXX

BO_ 2633804798 ESVMIN5: 8 Vector__XXX
 SG_ EngSparkPlug20MinVoltage : 48|16@1+ (1,0) [0|64255] "V" Vector__XXX
 SG_ EngSparkPlug19MinVoltage : 32|16@1+ (1,0) [0|64255] "V" Vector__XXX
 SG_ EngSparkPlug18MinVoltage : 16|16@1+ (1,0) [0|64255] "V" Vector__XXX
 SG_ EngSparkPlug17MinVoltage : 0|16@1+ (1,0) [0|64255] "V" Vector__XXX

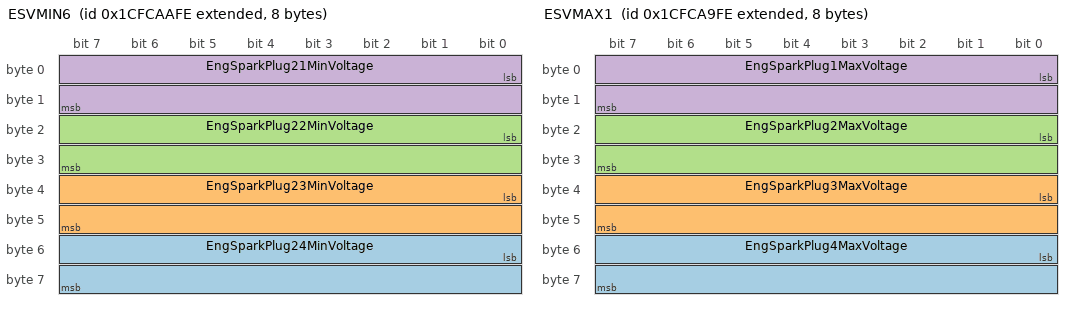
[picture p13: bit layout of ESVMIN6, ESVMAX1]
BO_ 2633804542 ESVMIN6: 8 Vector__XXX
 SG_ EngSparkPlug24MinVoltage : 48|16@1+ (1,0) [0|64255] "V" Vector__XXX
 SG_ EngSparkPlug23MinVoltage : 32|16@1+ (1,0) [0|64255] "V" Vector__XXX
 SG_ EngSparkPlug22MinVoltage : 16|16@1+ (1,0) [0|64255] "V" Vector__XXX
 SG_ EngSparkPlug21MinVoltage : 0|16@1+ (1,0) [0|64255] "V" Vector__XXX

BO_ 2633804286 ESVMAX1: 8 Vector__XXX
 SG_ EngSparkPlug4MaxVoltage : 48|16@1+ (1,0) [0|64255] "V" Vector__XXX
 SG_ EngSparkPlug3MaxVoltage : 32|16@1+ (1,0) [0|64255] "V" Vector__XXX
 SG_ EngSparkPlug2MaxVoltage : 16|16@1+ (1,0) [0|64255] "V" Vector__XXX
 SG_ EngSparkPlug1MaxVoltage : 0|16@1+ (1,0) [0|64255] "V" Vector__XXX

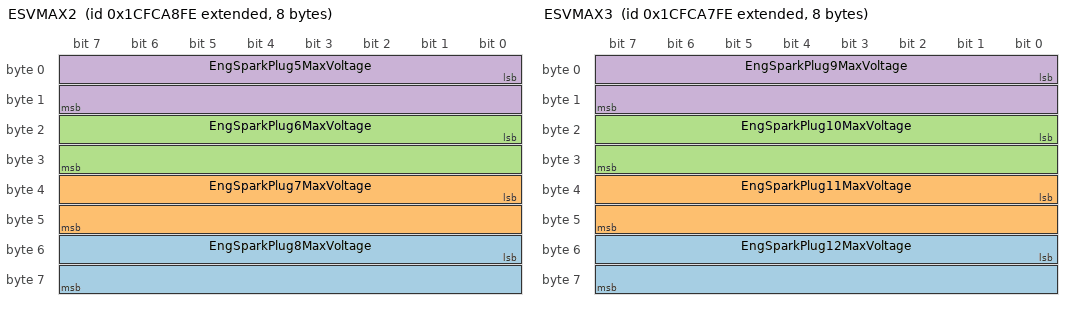
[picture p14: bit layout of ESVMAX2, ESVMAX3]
BO_ 2633804030 ESVMAX2: 8 Vector__XXX
 SG_ EngSparkPlug8MaxVoltage : 48|16@1+ (1,0) [0|64255] "V" Vector__XXX
 SG_ EngSparkPlug7MaxVoltage : 32|16@1+ (1,0) [0|64255] "V" Vector__XXX
 SG_ EngSparkPlug6MaxVoltage : 16|16@1+ (1,0) [0|64255] "V" Vector__XXX
 SG_ EngSparkPlug5MaxVoltage : 0|16@1+ (1,0) [0|64255] "V" Vector__XXX

BO_ 2633803774 ESVMAX3: 8 Vector__XXX
 SG_ EngSparkPlug12MaxVoltage : 48|16@1+ (1,0) [0|64255] "V" Vector__XXX
 SG_ EngSparkPlug11MaxVoltage : 32|16@1+ (1,0) [0|64255] "V" Vector__XXX
 SG_ EngSparkPlug10MaxVoltage : 16|16@1+ (1,0) [0|64255] "V" Vector__XXX
 SG_ EngSparkPlug9MaxVoltage : 0|16@1+ (1,0) [0|64255] "V" Vector__XXX

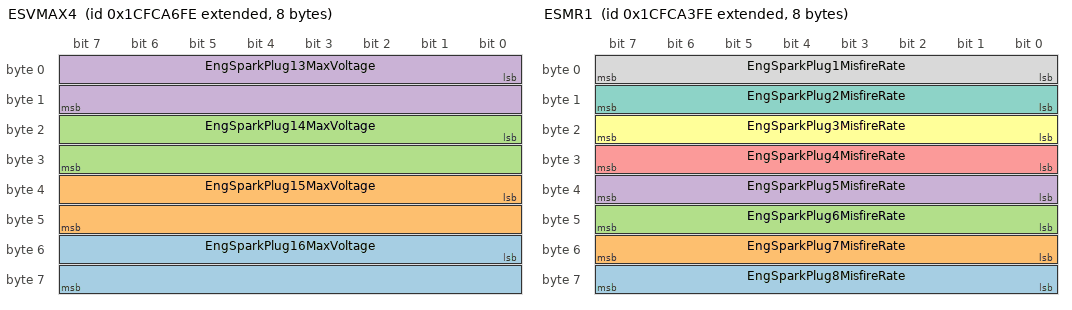
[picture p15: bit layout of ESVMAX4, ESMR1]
BO_ 2633803518 ESVMAX4: 8 Vector__XXX
 SG_ EngSparkPlug16MaxVoltage : 48|16@1+ (1,0) [0|64255] "V" Vector__XXX
 SG_ EngSparkPlug15MaxVoltage : 32|16@1+ (1,0) [0|64255] "V" Vector__XXX
 SG_ EngSparkPlug14MaxVoltage : 16|16@1+ (1,0) [0|64255] "V" Vector__XXX
 SG_ EngSparkPlug13MaxVoltage : 0|16@1+ (1,0) [0|64255] "V" Vector__XXX

BO_ 2633803262 ESVMAX5: 8 Vector__XXX
 SG_ EngSparkPlug20MaxVoltage : 48|16@1+ (1,0) [0|64255] "V" Vector__XXX
 SG_ EngSparkPlug19MaxVoltage : 32|16@1+ (1,0) [0|64255] "V" Vector__XXX
 SG_ EngSparkPlug18MaxVoltage : 16|16@1+ (1,0) [0|64255] "V" Vector__XXX
 SG_ EngSparkPlug17MaxVoltage : 0|16@1+ (1,0) [0|64255] "V" Vector__XXX

BO_ 2633803006 ESVMAX6: 8 Vector__XXX
 SG_ EngSparkPlug24MaxVoltage : 48|16@1+ (1,0) [0|64255] "V" Vector__XXX
 SG_ EngSparkPlug23MaxVoltage : 32|16@1+ (1,0) [0|64255] "V" Vector__XXX
 SG_ EngSparkPlug22MaxVoltage : 16|16@1+ (1,0) [0|64255] "V" Vector__XXX
 SG_ EngSparkPlug21MaxVoltage : 0|16@1+ (1,0) [0|64255] "V" Vector__XXX

BO_ 2633802750 ESMR1: 8 Vector__XXX
 SG_ EngSparkPlug8MisfireRate : 56|8@1+ (0.4,0) [0|100] "%" Vector__XXX
 SG_ EngSparkPlug7MisfireRate : 48|8@1+ (0.4,0) [0|100] "%" Vector__XXX
 SG_ EngSparkPlug6MisfireRate : 40|8@1+ (0.4,0) [0|100] "%" Vector__XXX
 SG_ EngSparkPlug5MisfireRate : 32|8@1+ (0.4,0) [0|100] "%" Vector__XXX
 SG_ EngSparkPlug4MisfireRate : 24|8@1+ (0.4,0) [0|100] "%" Vector__XXX
 SG_ EngSparkPlug3MisfireRate : 16|8@1+ (0.4,0) [0|100] "%" Vector__XXX
 SG_ EngSparkPlug2MisfireRate : 8|8@1+ (0.4,0) [0|100] "%" Vector__XXX
 SG_ EngSparkPlug1MisfireRate : 0|8@1+ (0.4,0) [0|100] "%" Vector__XXX

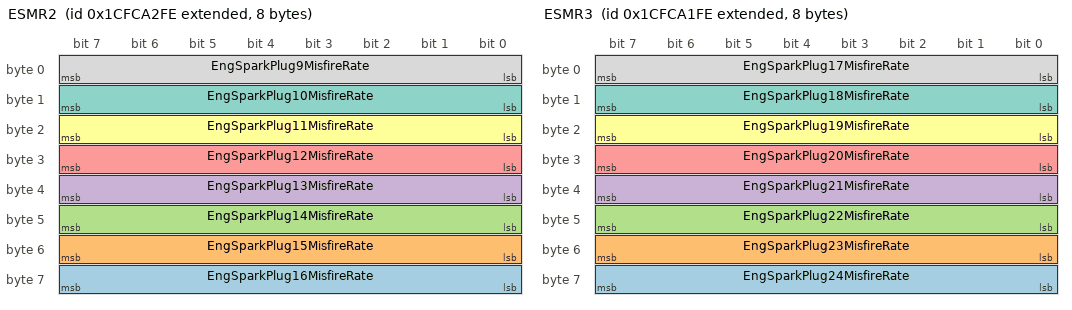
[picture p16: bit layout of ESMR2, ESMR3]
BO_ 2633802494 ESMR2: 8 Vector__XXX
 SG_ EngSparkPlug16MisfireRate : 56|8@1+ (0.4,0) [0|100] "%" Vector__XXX
 SG_ EngSparkPlug15MisfireRate : 48|8@1+ (0.4,0) [0|100] "%" Vector__XXX
 SG_ EngSparkPlug14MisfireRate : 40|8@1+ (0.4,0) [0|100] "%" Vector__XXX
 SG_ EngSparkPlug13MisfireRate : 32|8@1+ (0.4,0) [0|100] "%" Vector__XXX
 SG_ EngSparkPlug12MisfireRate : 24|8@1+ (0.4,0) [0|100] "%" Vector__XXX
 SG_ EngSparkPlug11MisfireRate : 16|8@1+ (0.4,0) [0|100] "%" Vector__XXX
 SG_ EngSparkPlug10MisfireRate : 8|8@1+ (0.4,0) [0|100] "%" Vector__XXX
 SG_ EngSparkPlug9MisfireRate : 0|8@1+ (0.4,0) [0|100] "%" Vector__XXX

BO_ 2633802238 ESMR3: 8 Vector__XXX
 SG_ EngSparkPlug24MisfireRate : 56|8@1+ (0.4,0) [0|100] "%" Vector__XXX
 SG_ EngSparkPlug23MisfireRate : 48|8@1+ (0.4,0) [0|100] "%" Vector__XXX
 SG_ EngSparkPlug22MisfireRate : 40|8@1+ (0.4,0) [0|100] "%" Vector__XXX
 SG_ EngSparkPlug21MisfireRate : 32|8@1+ (0.4,0) [0|100] "%" Vector__XXX
 SG_ EngSparkPlug20MisfireRate : 24|8@1+ (0.4,0) [0|100] "%" Vector__XXX
 SG_ EngSparkPlug19MisfireRate : 16|8@1+ (0.4,0) [0|100] "%" Vector__XXX
 SG_ EngSparkPlug18MisfireRate : 8|8@1+ (0.4,0) [0|100] "%" Vector__XXX
 SG_ EngSparkPlug17MisfireRate : 0|8@1+ (0.4,0) [0|100] "%" Vector__XXX

BO_ 2633801982 MFEH: 8 Vector__XXX
 SG_ EngTtlHoursOfDieselFuelOperation : 32|32@1+ (0.05,0) [0|210554060.75] "h" Vector__XXX
 SG_ EngTotalHoursOfGasFuelOperation : 0|32@1+ (0.05,0) [0|210554060.75] "h" Vector__XXX

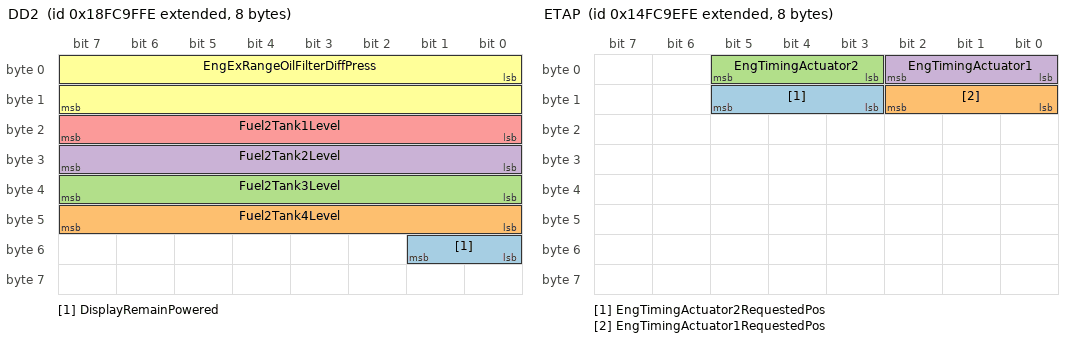
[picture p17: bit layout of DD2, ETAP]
BO_ 2566692862 DD2: 8 Vector__XXX
 SG_ DisplayRemainPowered : 48|2@1+ (1,0) [0|3] "" Vector__XXX
 SG_ Fuel2Tank4Level : 40|8@1+ (0.4,0) [0|100] "%" Vector__XXX
 SG_ Fuel2Tank3Level : 32|8@1+ (0.4,0) [0|100] "%" Vector__XXX
 SG_ Fuel2Tank2Level : 24|8@1+ (0.4,0) [0|100] "%" Vector__XXX
 SG_ Fuel2Tank1Level : 16|8@1+ (0.4,0) [0|100] "%" Vector__XXX
 SG_ EngExRangeOilFilterDiffPress : 0|16@1+ (0.0078125,-250) [-250|251.99] "kPa" Vector__XXX

BO_ 2499583742 ETAP: 8 Vector__XXX
 SG_ EngTimingActuator2RequestedPos : 11|3@1+ (1,0) [0|7] "" Vector__XXX
 SG_ EngTimingActuator1RequestedPos : 8|3@1+ (1,0) [0|7] "" Vector__XXX
 SG_ EngTimingActuator2 : 3|3@1+ (1,0) [0|7] "" Vector__XXX
 SG_ EngTimingActuator1 : 0|3@1+ (1,0) [0|7] "" Vector__XXX

BO_ 2499583486 ETAPC: 8 Vector__XXX
 SG_ EngTimingActuator2PosCmd : 3|3@1+ (1,0) [0|7] "" Vector__XXX
 SG_ EngTimingActuator1PosCmd : 0|3@1+ (1,0) [0|7] "" Vector__XXX

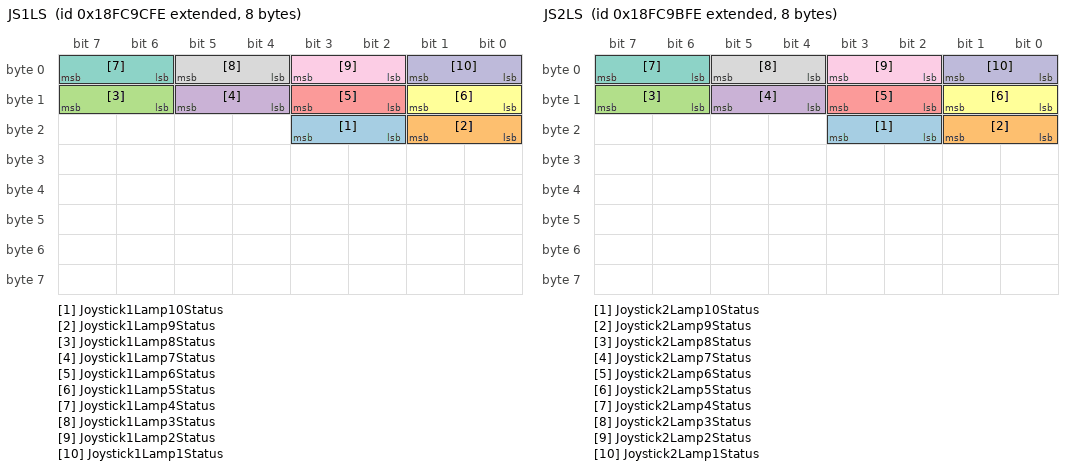
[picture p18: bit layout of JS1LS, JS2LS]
BO_ 2566692094 JS1LS: 8 Vector__XXX
 SG_ Joystick1Lamp10Status : 18|2@1+ (1,0) [0|3] "" Vector__XXX
 SG_ Joystick1Lamp9Status : 16|2@1+ (1,0) [0|3] "" Vector__XXX
 SG_ Joystick1Lamp8Status : 14|2@1+ (1,0) [0|3] "" Vector__XXX
 SG_ Joystick1Lamp7Status : 12|2@1+ (1,0) [0|3] "" Vector__XXX
 SG_ Joystick1Lamp6Status : 10|2@1+ (1,0) [0|3] "" Vector__XXX
 SG_ Joystick1Lamp5Status : 8|2@1+ (1,0) [0|3] "" Vector__XXX
 SG_ Joystick1Lamp4Status : 6|2@1+ (1,0) [0|3] "" Vector__XXX
 SG_ Joystick1Lamp3Status : 4|2@1+ (1,0) [0|3] "" Vector__XXX
 SG_ Joystick1Lamp2Status : 2|2@1+ (1,0) [0|3] "" Vector__XXX
 SG_ Joystick1Lamp1Status : 0|2@1+ (1,0) [0|3] "" Vector__XXX

BO_ 2566691838 JS2LS: 8 Vector__XXX
 SG_ Joystick2Lamp10Status : 18|2@1+ (1,0) [0|3] "" Vector__XXX
 SG_ Joystick2Lamp9Status : 16|2@1+ (1,0) [0|3] "" Vector__XXX
 SG_ Joystick2Lamp8Status : 14|2@1+ (1,0) [0|3] "" Vector__XXX
 SG_ Joystick2Lamp7Status : 12|2@1+ (1,0) [0|3] "" Vector__XXX
 SG_ Joystick2Lamp6Status : 10|2@1+ (1,0) [0|3] "" Vector__XXX
 SG_ Joystick2Lamp5Status : 8|2@1+ (1,0) [0|3] "" Vector__XXX
 SG_ Joystick2Lamp4Status : 6|2@1+ (1,0) [0|3] "" Vector__XXX
 SG_ Joystick2Lamp3Status : 4|2@1+ (1,0) [0|3] "" Vector__XXX
 SG_ Joystick2Lamp2Status : 2|2@1+ (1,0) [0|3] "" Vector__XXX
 SG_ Joystick2Lamp1Status : 0|2@1+ (1,0) [0|3] "" Vector__XXX

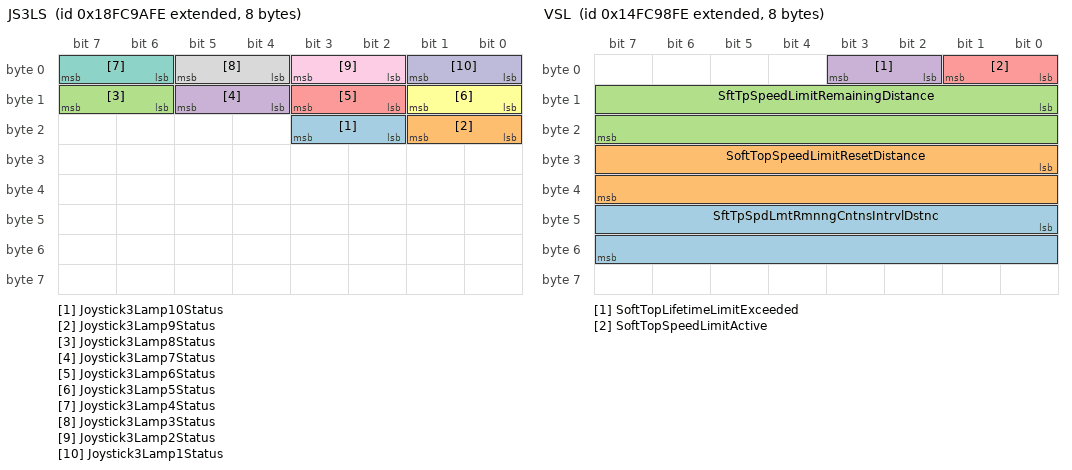
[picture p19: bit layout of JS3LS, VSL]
BO_ 2566691582 JS3LS: 8 Vector__XXX
 SG_ Joystick3Lamp10Status : 18|2@1+ (1,0) [0|3] "" Vector__XXX
 SG_ Joystick3Lamp9Status : 16|2@1+ (1,0) [0|3] "" Vector__XXX
 SG_ Joystick3Lamp8Status : 14|2@1+ (1,0) [0|3] "" Vector__XXX
 SG_ Joystick3Lamp7Status : 12|2@1+ (1,0) [0|3] "" Vector__XXX
 SG_ Joystick3Lamp6Status : 10|2@1+ (1,0) [0|3] "" Vector__XXX
 SG_ Joystick3Lamp5Status : 8|2@1+ (1,0) [0|3] "" Vector__XXX
 SG_ Joystick3Lamp4Status : 6|2@1+ (1,0) [0|3] "" Vector__XXX
 SG_ Joystick3Lamp3Status : 4|2@1+ (1,0) [0|3] "" Vector__XXX
 SG_ Joystick3Lamp2Status : 2|2@1+ (1,0) [0|3] "" Vector__XXX
 SG_ Joystick3Lamp1Status : 0|2@1+ (1,0) [0|3] "" Vector__XXX

BO_ 2566691326 AUI: 8 Vector__XXX
 SG_ AssemblyUnitIdentification : 8|8@1+ (1,0) [0|255] "" Vector__XXX
 SG_ NmbrOfAssmblyUntIdntfctionFields : 0|8@1+ (1,0) [0|250] "" Vector__XXX

BO_ 2499582206 VSL: 8 Vector__XXX
 SG_ SftTpSpdLmtRmnngCntnsIntrvlDstnc : 40|16@1+ (1,0) [0|64255] "km" Vector__XXX
 SG_ SoftTopSpeedLimitResetDistance : 24|16@1+ (1,0) [0|64255] "km" Vector__XXX
 SG_ SftTpSpeedLimitRemainingDistance : 8|16@1+ (1,0) [0|64255] "km" Vector__XXX
 SG_ SoftTopLifetimeLimitExceeded : 2|2@1+ (1,0) [0|3] "" Vector__XXX
 SG_ SoftTopSpeedLimitActive : 0|2@1+ (1,0) [0|3] "" Vector__XXX

CM_ BO_ 2566787838 "Auxiliary Valve Number 2 Estimated Flow
This message provides the estimated flow of specified auxiliary valve.";
CM_ SG_ 2566787838 AuxValve2Exit_reasonCode "This parameter indicates why the Auxiliary Valve 2 cannot accept remote commands or has most recently stopped accepting remote commands.
0-No reason/all clear
1-Operator presence not detected
2-Implement released control of function
3-Operator ...";
CM_ SG_ 2566787838 AuxValve2FailSafeMode "The measured state the fail safe mode of an auxiliary valve.

00 Block
01 Float
10 Error indication
11 Not available";
CM_ SG_ 2566787838 AuxValve2State "The measured state of the auxiliary valve.   With float enabled, hydraulic fluid may flow to or from the tractor as driven by the implement.

0000 Blocked
0001 Extend
0010 Retract
0011 Floating
0100-1110 Reserved
1111 Don't Care";
CM_ SG_ 2566787838 AuxValve2RetractPortEstFlow "The value reported by the controller of flow through the retract port of an auxiliary valve of a tractor which could be based on the commanded position of the valve.  Zero percent indicates no flow, 100%, maximum flow, -100% maximum flow returning ...";
CM_ SG_ 2566787838 AuxValve2ExtendPortEstFlow "The value reported by the controller of flow through the extend port of an auxiliary valve of a tractor which could be based on the commanded position of the valve.  Zero percent indicates no flow, 100%, maximum flow, -100% maximum flow returning to ...";
CM_ BO_ 2566787582 "Auxiliary Valve Number 1 Estimated Flow
This message provides the estimated flow of specified auxiliary valve.";
CM_ SG_ 2566787582 AuxValve1Exit_reasonCode "This parameter indicates why the Auxiliary Valve 1 cannot accept remote commands or has most recently stopped accepting remote commands.
0-No reason/all clear
1-Operator presence not detected
2-Implement released control of function
3-Operator ...";
CM_ SG_ 2566787582 AuxValve1FailSafeMode "The measured state the fail safe mode of an auxiliary valve.

00 Block
01 Float
10 Error indication
11 Not available";
CM_ SG_ 2566787582 AuxValve1State "The measured state of the auxiliary valve.   With float enabled, hydraulic fluid may flow to or from the tractor as driven by the implement.

0000 Blocked
0001 Extend
0010 Retract
0011 Floating
0100-1110 Reserved
1111 Don't Care";
CM_ SG_ 2566787582 AuxValve1RetractPortEstFlow "The value reported by the controller of flow through the retract port of an auxiliary valve of a tractor which could be based on the commanded position of the valve.  Zero percent indicates no flow, 100%, maximum flow, -100% maximum flow returning ...";
CM_ SG_ 2566787582 AuxValve1ExtendPortEstFlow "The value reported by the controller of flow through the extend port of an auxiliary valve of a tractor which could be based on the commanded position of the valve.  Zero percent indicates no flow, 100%, maximum flow, -100% maximum flow returning to ...";
CM_ BO_ 2566787326 "Auxiliary Valve Number 0 Estimated Flow
This message provides the estimated flow of specified auxiliary valve.";
CM_ SG_ 2566787326 AuxValve0Exit_reasonCode "This parameter indicates why the Auxiliary Valve 0 cannot accept remote commands or has most recently stopped accepting remote commands.
0-No reason/all clear
1-Operator presence not detected
2-Implement released control of function
3-Operator ...";
CM_ SG_ 2566787326 AuxValve0FailSafeMode "The measured state the fail safe mode of an auxiliary valve.

00 Block
01 Float
10 Error indication
11 Not available";
CM_ SG_ 2566787326 AuxValve0State "The measured state of the auxiliary valve.   With float enabled, hydraulic fluid may flow to or from the tractor as driven by the implement.

0000 Blocked
0001 Extend
0010 Retract
0011 Floating
0100-1110 Reserved
1111 Don't Care";
CM_ SG_ 2566787326 AuxValve0RetractPortEstFlow "The value reported by the controller of flow through the retract port of an auxiliary valve of a tractor which could be based on the commanded position of the valve.  Zero percent indicates no flow, 100%, maximum flow, -100% maximum flow returning ...";
CM_ SG_ 2566787326 AuxValve0ExtendPortEstFlow "The value reported by the controller of flow through the extend port of an auxiliary valve of a tractor which could be based on the commanded position of the valve.  Zero percent indicates no flow, 100%, maximum flow, -100% maximum flow returning to ...";
CM_ BO_ 2566787070 "Language Command
The language message has been defined as a global message to inform all ECUs on the 11783 bus the language that the operator wants to use, the date and time format and the units of measure with which the connected system should ...";
CM_ SG_ 2566787070 DistanceUnitCmd "Command to specify the distance units

00 Metric (km, m, …)
01 Imperial (miles, feet, ..)
10 Reserved
11 No action";
CM_ SG_ 2566787070 AreaUnitCmd "Command to specify the area units

00 Metric (ha or m2)
01 Imperial (acres or feet2)
10 Reserved
11 No action";
CM_ SG_ 2566787070 VolumeUnitCmd "Command to specify the volume units

00 Metric (litre)
01 Imperial (gallon)
10 US (gallon)
11 No action";
CM_ SG_ 2566787070 MassUnitCmd "Command to specify the mass units

00 Metric (tonne, kg, …)
01 Imperial (long tons-UK, pounds, ….)
10 Tons/pounds (short tons-US, pounds, …)
11 No action";
CM_ SG_ 2566787070 DateCmd "Command sent to all ECUs which specifies the displayed order of the date.

0 ddmmyyyy
1 ddyyyymm
2 mmyyyydd
3 mmddyyyy
4 yyyymmdd
5 yyyyddmm
6-255 Reserved";
CM_ SG_ 2566787070 DecimalSymbolCmd "Command sent to all ECUs which specifies that a decimal point or Comma should be displayed.

00 Comma is used
01 Point is used
10 Reserved
11 No action";
CM_ SG_ 2566787070 TimeCmd "Command sent to all ECUs which specifies the displayed format of the time

00 24 hour
01 12 hour (am/ pm)
10 Reserved
11 No action";
CM_ SG_ 2566787070 LanguageCodeCmd "Command sent to all ECUs which specifies the operator's desired language of information.  ISO 11783 shall use the 2-character string country codes in ISO 639.  Typical examples from ISO 639 are: 

Dutch: nl
French: fr
English: en
German: de";
CM_ BO_ 2566786814 "Response for Repetition Rate
This global message is the response of the request of a specific user to change the repetition rate.";
CM_ SG_ 2566786814 DataDictionaryRow "This 4 bit parameter indicates the Row that is to be used within the specific Data Dictionary Table identified by the Implement Type. This is the Group (GRUP) in LBS documents.";
CM_ SG_ 2566786814 DataDictionaryColumn "This 4 bit parameter indicates the Column that is to be used within the specific Data Dictionary Table identified by the Implement Type. This is the Instance (INST) in LBS documents.";
CM_ SG_ 2566786814 ImplementType "This 4 bit parameter indicates which data dictionary page is to be used to locate the identity of the following data.";
CM_ SG_ 2566786814 ImplementPos "This 4 bit parameter of this message will indicate which Implement is referenced within a set of identical Implements.  The numbering is to start with 1 at the leftmost, foremost, bottom most implement.  The numbering will then increment from left ...";
CM_ SG_ 2566786814 DataFormat_ErrorCondition "This 2 bit parameter that indicates the format or availability of the data in the following Process Data Parameter.
00 Data format is Long Integer
01 Data format is Floating
10 Data format is unsigned Long Integer
11 Not Available or error
Data ...";
CM_ SG_ 2566786814 ProcessDataType "This 2 bit parameter indicates what the data in the following Process Data Parameters is to be used for. See Table A.2.
00 Data is Set Point
01 Data is Actual values
10 Message is Set Point request
11 Message is Actual value request
Data is Set ...";
CM_ SG_ 2566786814 ProcessDataModifier "This 3 bit parameter that indicates how the data in the following Process Data Parameters is to be used when combined with the Process Data Type parameter. See Table A.2.

NOTE: Process Data Type is included since MOD is a function of PD";
CM_ SG_ 2566786814 RepetitionRateParameter "This parameter defines the repetition rate of the specified PGN.";
CM_ BO_ 2566786046 "Implement Remote Control Command
This command is a task controller or an implement ECU to tractor ECU message.";
CM_ BO_ 2566785790 "Implement Remote Control Command Tractor Response
This command is a task controller or an implement ECU to tractor ECU message.";
CM_ BO_ 2566785534 "Tractor Facilities response message
Tractor response to an implement ECU or task controller tractor classification and facilities request";
CM_ SG_ 2566785534 TrctrFcltyRspLmt_RqstSttsRprting "Indicates whether the vehicle supports reporting of the limit status and request status parameters in the tractor's supported status messages.

0   Limit/request status reporting not available
1   Limit/request status reporting available";
CM_ BO_ 2566785278 "Required Tractor Facilities message
Implement response to task controller or Tractor ECU desired tractor classification and facilities";
CM_ SG_ 2566785278 TrctrFcltyRqLmt_RqstSttsRporting "Indicates whether the requester requires reporting of the limit status and request status parameters in the tractor's supported status messages.

0  Limit/request status reporting not required
1  Limit/request status reporting required";
CM_ BO_ 2566774526 "Military Application Message #2/1
Message to transmit data of the towed vehicle to the towing vehicle. See ISO 11992-3.";
CM_ BO_ 2566774270 "Military Application Message #1/1
Message to transmit data of the towing vehicle to the towed vehicle. See ISO 11992-3.";
CM_ BO_ 2566770686 "Working Set Master Message
Message sent by the Master of a Working Set to identify how many members  there are  in said set.";
CM_ BO_ 2566770430 "Working Set Member Message
Message sent by the Master of a Working Set to identify an individual member of a specific Working Set.";
CM_ SG_ 2566770430 NAMEOfWorkingSetMember "NAME of Working Set Member

The identifier of the particular CA that is a member of the Working Set identified by the source address of this message.  This parameter is a NAME with the format described in 4.1.1.";
CM_ BO_ 2566761470 "Request For Complete Configurable Message Set (no longer used)
This message is designed to cause all CAs to respond with the complete sequence of configuration identification messages for a particular one or all of the configurable messages that ...";
CM_ SG_ 2566761470 PGNOfConfigurableMessageDesired "To identify the configurable message whose configuration is being requested. If the request is for all configurable PGNs then this SPN is set to all ones.";
CM_ SG_ 2566761470 MessageSelectionCtrl "Used to identify all configurable messages.";
CM_ BO_ 2566754814 "AC Switching Device Status
This contains parameters indicating the status of various breakers throughout a power generation system.  These include: Generator Circuit Breaker Status, Utility Circuit Breaker Status, and Automatic Transfer Switch ...";
CM_ SG_ 2566754814 AutomaticTransferSwitchStatus "This parameter indicates the measured state of the automatic transfer switch.
Bit state 000 = Normal position
Bit state 001 = Emergency position
Bit states 010-101 = available for SAE assignment
Bit state 110 = error
Bit state 111 = not ...";
CM_ SG_ 2566754814 UtilityCircuitBreakerStatus "This parameter indicates the measured state of the utility circuit breaker.
Bit state 000 = Open
Bit state 001 = Closed
Bit state 010 = Locked Out
Bit states 011-101 = available for SAE assignment
Bit state 110 = error
Bit state 111 = not ...";
CM_ SG_ 2566754814 GeneratorCircuitBreakerStatus "This parameter indicates the measured state of the generator circuit breaker.
Bit state 000 = Open
Bit state 001 = Closed
Bit state 010 = Locked Out
Bit states 011-101 = available for SAE assignment
Bit state 110 = error
Bit state 111 = not ...";
CM_ BO_ 2566754302 "Generator Total AC Percent Power
This PGN contains quantities for the instantaneous AC power from the generator, as percentages of rated power";
CM_ SG_ 2566754302 GeneratorTotalPercentKVAr "This parameter reports the generator total AC reactive power, as a percentage of rated power.";
CM_ SG_ 2566754302 GeneratorTotalPercentKVA "This parameter reports the generator total AC apparent power, as a percentage of rated power.";
CM_ SG_ 2566754302 GeneratorTotalPercentKW "This parameter reports the generator total AC power, as a percentage of rated power.";
CM_ BO_ 2566754046 "Generator Total AC Reactive Energy
This PGN contains quantities for the cumulative AC reactive energy from the generator.";
CM_ SG_ 2566754046 GeneratorTotalKVArHoursImport "This parameter reports the cumulative total AC reactive energy imported to the generator.";
CM_ SG_ 2566754046 GeneratorTotalKVArHoursExport "This parameter reports the cumulative total AC reactive energy exported from the generator.";
CM_ BO_ 2566753790 "Utility Total AC Reactive Energy
This PGN contains quantities for the cumulative AC reactive energy from the utility.";
CM_ SG_ 2566753790 UtilityTotalKVArHoursImport "This parameter reports the cumulative total AC reactive energy imported to the utility.";
CM_ SG_ 2566753790 UtilityTotalKVArHoursExport "This parameter reports the cumulative total AC reactive energy exported from the utility.";
CM_ BO_ 2566738174 "General Purpose Message #1/9
Message to transmit data of the towing vehicle to the towed vehicle. See ISO 11992-3.";
CM_ BO_ 2566737918 "General Purpose Message #2/6
Message to transmit data of the towed vehicle to the towing vehicle. See ISO 11992-3.";
CM_ BO_ 2566737662 "General Purpose Message #2/7
Message to transmit data of the towed vehicle to the towing vehicle. See ISO 11992-3.";
CM_ BO_ 2566737406 "General Purpose Message #2/8
Message to transmit data of the towed vehicle to the towing vehicle. See ISO 11992-3.";
CM_ BO_ 2566737150 "General Purpose Message #2/9
Message to transmit data of the towed vehicle to the towing vehicle. See ISO 11992-3.";
CM_ BO_ 2566736894 "General Purpose Message #2/10
Message to transmit data of the towed vehicle to the towing vehicle. See ISO 11992-3.";
CM_ BO_ 2566736638 "General Purpose Message #2/11
Message to transmit data of the towed vehicle to the towing vehicle. See ISO 11992-3.";
CM_ BO_ 2566734846 "Machine Selected Speed Command
Message that provides the control of the machine speed and direction.";
CM_ SG_ 2566734846 MachineSelectedDirectionCmd "Commanded direction of travel of the machine.

00 - Reverse
01 - Forward
10 - Reserved
11 - Don't care, take no action";
CM_ SG_ 2566734846 MchnSelectedSpeedExit_reasonCode "This parameter indicates why the Vehicle Speed control unit cannot currently accept remote commands or has most recently stopped accepting remote commands.
0-No reason/all clear
1-Operator presence not detected
2-Implement released control of ...";
CM_ SG_ 2566734846 MchineSelectedSpeedSetpointLimit "The machine's maximum allowed speed communicated to the tractor.";
CM_ SG_ 2566734846 MachineSelectedSpeedSetpointCmd "Commanded set point value of the machine speed as measured by the selected source.";
CM_ BO_ 2566734590 "ISOBUS compliance certification
This message reports the compliance certification status of a specific electronic control unit.";
CM_ SG_ 2566734590 ISOBUSCmplncCrtfctnMssgeRevision "This parameter distinguishes the format ISOBUS Compliance Certification message in the 2nd edition from the format in the 3rd edition (and later).

0   Format of message in 2nd edition
1   Post-2nd edition message revision";
CM_ SG_ 2566734590 ISOBUSCmplncCrtfctnRfrenceNumber "Certificate reference number assigned by Certification laboratory.  Uniquely identifies the test file from the Certification laboratory when use with the Certification laboratory ID and the ECU manufacturer ID.";
CM_ SG_ 2566734590 ISOBUSCmplncCrtfctonTypeTaskCtrl "Parameter used to indicate the type of compliance test performed.

0    Not certified 
1    Certified";
CM_ SG_ 2566734590 ISOBUSCmplncCrtfctnTypTCWrkn4326 "Parameter used to indicate the type of compliance test performed.

0    Not certified 
1    Certified";
CM_ SG_ 2566734590 ISOBUSCmplncCrtfctnTypTCWrkngStM "Parameter used to indicate the type of compliance test performed.

0    Not certified 
1    Certified";
CM_ SG_ 2566734590 ISOBUSCmplncCrtfctnTypFileServer "Parameter used to indicate the type of compliance test performed.

0    Not certified 
1    Certified";
CM_ SG_ 2566734590 ISOBUSCmplncCrtfctnTypGPSRceiver "Parameter used to indicate the type of compliance test performed.

0    Not certified 
1    Certified";
CM_ SG_ 2566734590 ISOBUSCmplncCrtfcationTypeMinECU "Parameter used to indicate the type of compliance test performed.

0    Not certified 
1    Certified";
CM_ SG_ 2566734590 ISOBUSCmplncCrtfctnTypTECUClass1 "Parameter used to indicate the type of compliance test performed.

0    Not certified 
1    Certified";
CM_ SG_ 2566734590 ISOBUSCmplncCrtfctnTypTECUClass2 "Parameter used to indicate the type of compliance test performed.

0    Not certified 
1    Certified";
CM_ SG_ 2566734590 ISOBUSCmplncCrtfctnTypTECUClass3 "Parameter used to indicate the type of compliance test performed.

0    Not certified 
1    Certified";
CM_ SG_ 2566734590 ISOBUSCmplncCrtfctnTypeClass3ECU "Parameter used to indicate the type of compliance test performed.

0    Not certified 
1    Certified";
CM_ SG_ 2566734590 ISOBUSCmplncCrtfctnTypVrtlTrmnal "Parameter used to indicate the type of compliance test performed.

0    Not certified 
1    Certified";
CM_ SG_ 2566734590 ISOBUSCmplncCrtfctnTypVTWrkn4323 "Parameter used to indicate the type of compliance test performed.

0    Not certified 
1    Certified";
CM_ SG_ 2566734590 ISOBUSCmplncCrtfctnTypVTWrkngStM "Parameter used to indicate the type of compliance test performed.

0    Not certified 
1    Certified";
CM_ SG_ 2566734590 ISOBUSCmplncCrtfctonLaboratoryID "Manufacturer code of the laboratory that performed the compliance test.  In the case of a self-certified ECU, this matches the manufacturer code contained in the address claim PGN.  See ISO 11783 Part 1 Annex B Table B6.";
CM_ SG_ 2566734590 ISOBUSCmplncCrtfctLaboratoryType "Approving body for the certification laboratory.

000 - Non-certified laboratory/ self certification
001 - EU certified laboratory
010 - NA certified laboratory
011 - 110 - Reserved
111 - Not available (Not certified)";
CM_ SG_ 2566734590 ISOBUSCmplnceCertificateRevision "Revision of the ISOBUS compliance test performed.  In years where there are multiple revisions of the test protocol, an alphabetic suffix is used in addition to the certification year.
000 - First Revision (No Suffix)
001 - Second Revision (Suffix ...";
CM_ SG_ 2566734590 ISOBUSCmplianceCertificationYear "Year of the compliance test protocol to which the certification test was performed.";
CM_ BO_ 2566730494 "Reserved for ISOBUS ECU diagnostic protocol
The ECU level 1 diagnostic protocol message identifies the diagnostic protocol required by a service tool to troubleshoot a fault.";
CM_ BO_ 2566718462 "Implement Operating State Command
Message sent by the tractor ECU on the implement bus on forestry or agriculture implements providing to connected systems the current commanded implement operating state.";
CM_ SG_ 2566718462 ImplementOperatingStateCmd "Command for setting the operating state of a connected implement system.

00  Set implement to field working state
01  Set implement to transport state
10  Set implement to park state
11  Take no action";
CM_ BO_ 2566718206 "All Implements Stop Operations Switch State
This message may be sent by any ECU connected to the implement bus on forestry or agriculture implements providing the current state of the 'all implements stop operations' switch to connected systems.";
CM_ SG_ 2566718206 StpAllImplmntOprtnsTrnstonNumber "Indicates the number of transitions from Permit (01) to Stop (00) since power up of the Stop all implement operations parameter. The parameter resets to zero on the next transition after reporting the maximum value.";
CM_ SG_ 2566718206 AllImplmntStpOprtngOprtnsSwtchSt "State of a switch or other operator input for stopping the operation of a connected system.

00  All implements stop operations switch OFF
01  All implements stop operations switch ON
10  Error indication
11  Not available";
CM_ BO_ 2566706430 "XCP Get Slave ID
Used by the XCP master (tool) to identify all XCP slaves on the network.";
CM_ BO_ 2566704894 "Drive Strategy Command
Message from to the tractor used to alter the powertrain DriveStrategy priority structure, which determines the balance between fuel economy/consumption and the torque reserve of the engine.";
CM_ BO_ 2566704638 "Drive Strategy Status
Message from the tractor to the implement showing the current status of the Drive Strategy priority structure, which indicates the priority of the multiple powertrain functions.";
CM_ BO_ 2566701566 "Transmission Fluids 3";
CM_ SG_ 2566701566 TransOilTransCoolerOutletTemp "Temperature of transmission lubricant after it exits from the transmission cooler.";
CM_ SG_ 2566701566 TransClutch2Press "Gage pressure of hydraulic actuation fluid of transmission second clutch in a dual clutch application.";
CM_ BO_ 2499592446 "Electronic Transmission Controller #11
Electronic Transmission Controller #11";
CM_ SG_ 2499592446 TransShiftRail6Pos "The current position of transmission shift rail identified as rail #6.";
CM_ SG_ 2499592446 TransShiftRail5Pos "The current position of transmission shift rail identified as rail #5.";
CM_ SG_ 2499592446 TransShiftRail4Pos "The current position of transmission shift rail identified as rail #4.";
CM_ SG_ 2499592446 TransShiftRail3Pos "The current position of transmission shift rail identified as rail #3.";
CM_ SG_ 2499592446 TransShiftRail2Pos "The current position of transmission shift rail identified as rail #2.";
CM_ SG_ 2499592446 TransShiftRail1Pos "The current position of transmission shift rail identified as rail #1.";
CM_ BO_ 2499592190 "Electronic Transmission Controller #10
Electronic Transmission Controller #10";
CM_ SG_ 2499592190 TransHydPumpActuator2Percent "The current modulated value for actuator 2 that controls the transmission hydraulic pump, where 0% = no hydraulic pressure and 100% = full hydraulic pressure.";
CM_ SG_ 2499592190 TransShiftRail6ActuatorStatus "Identifies the status of the actuator that moves the transmission shift rail identified as rail #6.

00 = off
01 = on
10 = error
11 = not available";
CM_ SG_ 2499592190 TransShiftRail5ActuatorStatus "Identifies the status of the actuator that moves the transmission shift rail identified as rail #5.

00 = off
01 = on
10 = error
11 = not available";
CM_ SG_ 2499592190 TransShiftRail4ActuatorStatus "Identifies the status of the actuator that moves the transmission shift rail identified as rail #4.

00 = off
01 = on
10 = error
11 = not available";
CM_ SG_ 2499592190 TransShiftRail3ActuatorStatus "Identifies the status of the actuator that moves the transmission shift rail identified as rail #3.

00 = off
01 = on
10 = error
11 = not available";
CM_ SG_ 2499592190 TransShiftRail2ActuatorStatus "Identifies the status of the actuator that moves the transmission shift rail identified as rail #2.

00 = off
01 = on
10 = error
11 = not available";
CM_ SG_ 2499592190 TransShiftRail1ActuatorStatus "Identifies the status of the actuator that moves the transmission shift rail identified as rail #1.

00 = off
01 = on
10 = error
11 = not available";
CM_ SG_ 2499592190 TrnsClutch2CoolingActuatorStatus "Identifies the status of the actuator that cools transmission clutch 2.

00 = off
01 = on
10 = error
11 = not available";
CM_ SG_ 2499592190 TrnsClutch1CoolingActuatorStatus "Identifies the status of the actuator that cools transmission clutch 1.

00 = off
01 = on
10 = error
11 = not available";
CM_ SG_ 2499592190 TransShiftActuator2Percent "The current modulated value for the transmission shift 2 actuator, where 0% = no hydraulic pressure and 100% = full hydraulic pressure.";
CM_ SG_ 2499592190 TransShiftActuator1Percent "The current modulated value for the transmission shift 1 actuator, where 0% = no hydraulic pressure and 100% = full hydraulic pressure.";
CM_ SG_ 2499592190 TransHydPumpActuator1Percent "The current modulated value for the actuator that controls the transmission hydraulic pump, where 0% = no hydraulic pressure and 100% = full hydraulic pressure.";
CM_ SG_ 2499592190 TransClutch2ActuatorPercent "The current modulated value for the transmission clutch 2 actuator, where 0% = no hydraulic pressure and 100% = full hydraulic pressure.";
CM_ SG_ 2499592190 TransClutch1ActuatorPercent "The current modulated value for the transmission clutch 1 actuator, where 0% = no hydraulic pressure and 100% = full hydraulic pressure.";
CM_ BO_ 2365374206 "Electronic Transmission Controller #9
Electronic Transmission Controller #9
Note:
Single input shaft transmissions should use SPN 161 (Transmission Input Shaft Speed).
Multiple input shaft transmissions should use SPN 5960 and 5961 (DCT Input ...";
CM_ SG_ 2365374206 DlCltchTrnsCrrntPreselectionGear "The gear currently engaged on the non-engaged clutch of a dual clutch transmission (DCT) or the last gear engaged on the non-engaged clutch while the transmission is in the process of pre-selecting to the new or selected pre-selection gear on the ...";
CM_ SG_ 2365374206 DlCltchTrnsSlctdPreselectionGear "The gear that the transmission will attempt to achieve during the current pre-selection event (shifting to a new gear on the non-engaged clutch of a dual clutch transmission (DCT)).";
CM_ SG_ 2365374206 DualClutchTransInputShaft2Speed "Rotational velocity of the primary shaft transferring power through clutch 2 into the dual clutch transmission (DCT).";
CM_ SG_ 2365374206 DualClutchTransInputShaft1Speed "Rotational velocity of the primary shaft transferring power through clutch 1 into the dual clutch transmission (DCT).";
CM_ BO_ 2566700542 "Aftertreatment 1 SCR Service Information 2
This message contains SCR service information for aftertreatment system 1 (or bank 1).";
CM_ SG_ 2566700542 TripDEF "DEF consumed during all or part of a journey.";
CM_ SG_ 2566700542 TotalDEFUsed "Total amount of DEF used by aftertreatment device 1 over the lifetime of the device.";
CM_ BO_ 2566700286 "Aftertreatment 2 SCR Service Information 2
This message contains SCR service information for aftertreatment system 2 (or bank 2).";
CM_ SG_ 2566700286 TotalDEFUsed "Total amount of DEF used by aftertreatment device 2 over the lifetime of the device.";
CM_ BO_ 2566700030 "Aftertreatment 1 SCR Electronic Control Module Information
Information relating to SCR electronic control module of aftertreatment 1 (bank 1).";
CM_ SG_ 2566700030 DEFCtrlModule2PwrSupply2 "State signal which indicates when the DEF control module 2 power supply 2 of aftertreatment 1 is being driven. On means the ECU is powering the aftertreatment 1 DEF control module power supply. Note that the control module is external to the ECU.
 ...";
CM_ SG_ 2566700030 DEFCtrlModule2PwrSupply1 "State signal which indicates when the DEF control module 2 power supply of aftertreatment 1 is being driven. On means the ECU is powering the aftertreatment 1 DEF control module power supply. Note that the control module is external to the ECU.
00 ...";
CM_ SG_ 2566700030 DEFCtrlModule2RelayCtrl "State signal which indicates when the DEF control module 2 relay of aftertreatment 1 is being energized. On means the ECU is powering the Aftertreatment 1 DEF dosing unit relay. Note that the ECU is external to the relay.
00 - Off
01 - On: The ECU ...";
CM_ SG_ 2566700030 DEFCtrlModuleCircuitBreaker "The status of the circuit breaker that is used to power the diesel exhaust control module.

00 off
01 on
10 error
11 not available";
CM_ SG_ 2566700030 DEFCtrlModule1PwrSupply2 "State signal which indicates when the DEF control module 1 power supply 2 of aftertreatment 1 is being driven. On means the ECU is powering the aftertreatment 1 DEF control module 1 power supply. Note that the control module is external to the ECU.
 ...";
CM_ SG_ 2566700030 DEFCtrlModule1PwrSupply1 "State signal which indicates when the DEF control module power supply of aftertreatment 1 is being driven. On means the ECU is powering the aftertreatment 1 DEF control module power supply. Note that the control module is external to the ECU.
00 - ...";
CM_ SG_ 2566700030 DEFCtrlModule1RelayCtrl "State signal which indicates when the DEF control module relay of aftertreatment 1 is being energized. On means the ECU is powering the Aftertreatment 1 DEF dosing unit relay. Note that the ECU is external to the relay.
00 - Off
01 - On: The ECU ...";
CM_ BO_ 2566699774 "Aftertreatment 2 SCR Electronic Control Module Information
Information relating to SCR electronic control module of aftertreatment 2 (bank 2).";
CM_ SG_ 2566699774 DEFCtrlModule2PwrSupply2 "State signal which indicates when the DEF control module 2 power supply 2 of aftertreatment 2 is being driven. On means the ECU is powering the aftertreatment 2 DEF control module power supply. Note that the control module is external to the ECU.
 ...";
CM_ SG_ 2566699774 DEFCtrlModule2PwrSupply1 "State signal which indicates when the DEF control module 2 power supply of aftertreatment 2 is being driven. On means the ECU is powering the aftertreatment 2 DEF control module power supply. Note that the control module is external to the ECU.
00 ...";
CM_ SG_ 2566699774 DEFCtrlModule2RelayCtrl "State signal which indicates when the DEF control module 2 relay of aftertreatment 2 is being energized. On means the ECU is powering the Aftertreatment 2 DEF dosing unit relay. Note that the ECU is external to the relay.
00 - Off
01 - On: The ECU ...";
CM_ SG_ 2566699774 DEFCtrlModule1PwrSupply2 "State signal which indicates when the DEF control module 1 power supply 2 of aftertreatment 2 is being driven. On means the ECU is powering the aftertreatment 2 DEF control module 1 power supply. Note that the control module is external to the ECU.
 ...";
CM_ SG_ 2566699774 DEFCtrlModule1PwrSupply1 "State signal which indicates when the DEF control module 1 power supply of aftertreatment 2 is being driven. On means the ECU is powering the aftertreatment 2 DEF control module 1 power supply. Note that the control module is external to the ECU.
 ...";
CM_ SG_ 2566699774 DEFCtrlModule1RelayCtrl "State signal which indicates when the DEF control module 1 relay of aftertreatment 2 is being energized. On means the ECU is powering the Aftertreatment 2 DEF dosing unit relay. Note that the ECU is external to the relay.
00 - Off
01 - On: The ECU ...";
CM_ BO_ 2566699518 "Aftertreatment 1 Service 2
This PGN contains information about the aftertreatment 1.";
CM_ SG_ 2566699518 SCRSysTimeSinceLastSysCleanEvent "Indicates the time since the last cleaning event of the SCR system in bank 1.";
CM_ SG_ 2566699518 DPFTimeToNextActiveRegen "Indicates the time to the next active regeneration event of diesel particulate filter 1.";
CM_ BO_ 2566699262 "Aftertreatment 2 Service 2
This PGN contains information about the aftertreatment 2.";
CM_ SG_ 2566699262 SCRSysTimeSinceLastSysCleanEvent "Indicates the time since the last cleaning event of the SCR system in bank 2.";
CM_ SG_ 2566699262 DPFTimeToNextActiveRegen "Indicates the time to the next active regeneration event of diesel particulate filter 2.";
CM_ BO_ 2566698750 "Vehicle Electrical Power #5
PGN containing vehicle electrical power information for the battery pack used for starting, lighting, and ignition.";
CM_ SG_ 2566698750 SLICrnkngPrdctdMinBatteryVoltage "Prediction of the minimum battery voltage used for starting the engine, for lighting, and for ignition (SLI) during a crank event, under present battery conditions.";
CM_ SG_ 2566698750 SLIBatteryPackHealth "Capacity of the battery pack relative to its original specification for the battery pack used for starting the engine, for lighting, and for ignition (SLI). 0% means battery pack is not capable of holding any charge, 100% means battery pack is ...";
CM_ SG_ 2566698750 SLIBatteryPackCapacity "Original or rated total reserve capacity of the battery pack used for starting the engine, for lighting, and for ignition (SLI).";
CM_ SG_ 2566698750 SLIBatteryPackStateOfCharge "Indicates the remaining charge of the battery pack used for starting the engine, for lighting, and for ignition (SLI). 0% means no charge remaining, 100% means full capacity at the battery pack's current state of health.   See SPN 5464 for hybrid ...";
CM_ BO_ 2566698494 "Fused Power Output Status
Fused power output status is sent by the Power Distribution Module (PDM) to indicate the state of the PDM's fused outputs.
This message is sent once every second (1000ms) and on change of any fused power output status, ...";
CM_ SG_ 2566698494 FusedOutput29 "State of Fused Output #29. Used to indicate the output state.

00 - Output not powered
01 - Output powered
10 - Reserved
11 - Take no action";
CM_ SG_ 2566698494 FusedOutput30 "State of Fused Output #30. Used to indicate the output state.

00 - Output not powered
01 - Output powered
10 - Reserved
11 - Take no action";
CM_ SG_ 2566698494 FusedOutput31 "State of Fused Output #31. Used to indicate the output state.

00 - Output not powered
01 - Output powered
10 - Reserved
11 - Take no action";
CM_ SG_ 2566698494 FusedOutput32 "State of Fused Output #32. Used to indicate the output state.

00 - Output not powered
01 - Output powered
10 - Reserved
11 - Take no action";
CM_ SG_ 2566698494 FusedOutput25 "State of Fused Output #25. Used to indicate the output state.

00 - Output not powered
01 - Output powered
10 - Reserved
11 - Take no action";
CM_ SG_ 2566698494 FusedOutput26 "State of Fused Output #26. Used to indicate the output state.

00 - Output not powered
01 - Output powered
10 - Reserved
11 - Take no action";
CM_ SG_ 2566698494 FusedOutput27 "State of Fused Output #27. Used to indicate the output state.

00 - Output not powered
01 - Output powered
10 - Reserved
11 - Take no action";
CM_ SG_ 2566698494 FusedOutput28 "State of Fused Output #28. Used to indicate the output state.

00 - Output not powered
01 - Output powered
10 - Reserved
11 - Take no action";
CM_ SG_ 2566698494 FusedOutput21 "State of Fused Output #21. Used to indicate the output state.

00 - Output not powered
01 - Output powered
10 - Reserved
11 - Take no action";
CM_ SG_ 2566698494 FusedOutput22 "State of Fused Output #22. Used to indicate the output state.

00 - Output not powered
01 - Output powered
10 - Reserved
11 - Take no action";
CM_ SG_ 2566698494 FusedOutput23 "State of Fused Output #23. Used to indicate the output state.

00 - Output not powered
01 - Output powered
10 - Reserved
11 - Take no action";
CM_ SG_ 2566698494 FusedOutput24 "State of Fused Output #24. Used to indicate the output state.

00 - Output not powered
01 - Output powered
10 - Reserved
11 - Take no action";
CM_ SG_ 2566698494 FusedOutput17 "State of Fused Output #17. Used to indicate the output state.

00 - Output not powered
01 - Output powered
10 - Reserved
11 - Take no action";
CM_ SG_ 2566698494 FusedOutput18 "State of Fused Output #18. Used to indicate the output state.

00 - Output not powered
01 - Output powered
10 - Reserved
11 - Take no action";
CM_ SG_ 2566698494 FusedOutput19 "State of Fused Output #19. Used to indicate the output state.

00 - Output not powered
01 - Output powered
10 - Reserved
11 - Take no action";
CM_ SG_ 2566698494 FusedOutput20 "State of Fused Output #20. Used to indicate the output state.

00 - Output not powered
01 - Output powered
10 - Reserved
11 - Take no action";
CM_ SG_ 2566698494 FusedOutput13 "State of Fused Output #13. Used to indicate the output state.

00 - Output not powered
01 - Output powered
10 - Reserved
11 - Take no action";
CM_ SG_ 2566698494 FusedOutput14 "State of Fused Output #14. Used to indicate the output state.

00 - Output not powered
01 - Output powered
10 - Reserved
11 - Take no action";
CM_ SG_ 2566698494 FusedOutput15 "State of Fused Output #15. Used to indicate the output state.

00 - Output not powered
01 - Output powered
10 - Reserved
11 - Take no action";
CM_ SG_ 2566698494 FusedOutput16 "State of Fused Output #16. Used to indicate the output state.

00 - Output not powered
01 - Output powered
10 - Reserved
11 - Take no action";
CM_ SG_ 2566698494 FusedOutput9 "State of Fused Output #9. Used to indicate the output state.

00 - Output not powered
01 - Output powered
10 - Reserved
11 - Take no action";
CM_ SG_ 2566698494 FusedOutput10 "State of Fused Output #10. Used to indicate the output state.

00 - Output not powered
01 - Output powered
10 - Reserved
11 - Take no action";
CM_ SG_ 2566698494 FusedOutput11 "State of Fused Output #11. Used to indicate the output state.

00 - Output not powered
01 - Output powered
10 - Reserved
11 - Take no action";
CM_ SG_ 2566698494 FusedOutput12 "State of Fused Output #12. Used to indicate the output state.

00 - Output not powered
01 - Output powered
10 - Reserved
11 - Take no action";
CM_ SG_ 2566698494 FusedOutput5 "State of Fused Output #5. Used to indicate the output state.

00 - Output not powered
01 - Output powered
10 - Reserved
11 - Take no action";
CM_ SG_ 2566698494 FusedOutput6 "State of Fused Output #6. Used to indicate the output state.

00 - Output not powered
01 - Output powered
10 - Reserved
11 - Take no action";
CM_ SG_ 2566698494 FusedOutput7 "State of Fused Output #7. Used to indicate the output state.

00 - Output not powered
01 - Output powered
10 - Reserved
11 - Take no action";
CM_ SG_ 2566698494 FusedOutput8 "State of Fused Output #8. Used to indicate the output state.

00 - Output not powered
01 - Output powered
10 - Reserved
11 - Take no action";
CM_ SG_ 2566698494 FusedOutput1 "State of Fused Output #1. Used to indicate the output state.

00 - Output not powered
01 - Output powered
10 - Reserved
11 - Take no action";
CM_ SG_ 2566698494 FusedOutput2 "State of Fused Output #2. Used to indicate the output state.

00 - Output not powered
01 - Output powered
10 - Reserved
11 - Take no action";
CM_ SG_ 2566698494 FusedOutput3 "State of Fused Output #3. Used to indicate the output state.

00 - Output not powered
01 - Output powered
10 - Reserved
11 - Take no action";
CM_ SG_ 2566698494 FusedOutput4 "State of Fused Output #4. Used to indicate the output state.

00 - Output not powered
01 - Output powered
10 - Reserved
11 - Take no action";
CM_ BO_ 2559115006 "Radio Beacon Request
Message used to request the wireless transceiver to transmit a special beacon signal and to report
the reception of a special beacon signal by a wireless transceiver. A unique number is included in
each beacon signal to ...";
CM_ SG_ 2559115006 WirelessSignalStrength2 "The absolute received signal strength of the special beacon signal received from the off-board transmitter. The signal strength is reported as a Received Signal Strength Indicator (RSSI) value in dBm. This measurement method is identical to SPN 5753 ...";
CM_ SG_ 2559115006 TransmitterID2 "The ID of the off-board transmitter that sent the incoming special beacon message received by the wireless transceiver.";
CM_ SG_ 2559115006 RadioBeaconDirection "Indicates the function of a particular instance of the Radio Beacon Request message. The 'Beacon Request' state indicates the message is sent to a wireless transceiver to request a transmit of the special beacon message. The 'Beacon Received ...";
CM_ SG_ 2559115006 UnqBeaconMessageIdentifierNumber "The number is used to identify a wireless message originating from a device on a particular machine. Within a beacon request message (see SPN 5755 [Radio Beacon Direction]), this number is included in the transmitted beacon signal. Within a beacon ...";
CM_ BO_ 2566707454 "Aftertreatment 1 Diesel Particulate Filter 2 Soot 3
This message is used to specify up to 4 soot sensor analysis frequencies to request the soot sensor signal data associated with those analysis frequencies for aftertreatment 1 diesel particulate ...";
CM_ SG_ 2566707454 SnsrAnalysisReqFreq4 "Fourth requested analysis frequency for the diesel particulate filter 2 soot sensor.";
CM_ SG_ 2566707454 SnsrAnalysisReqFreq3 "Third requested analysis frequency for the diesel particulate filter 2 soot sensor.";
CM_ SG_ 2566707454 SnsrAnalysisReqFreq2 "Second requested analysis frequency for the diesel particulate filter 2 soot sensor.";
CM_ SG_ 2566707454 SnsrAnalysisReqFreq1 "First requested analysis frequency for the diesel particulate filter 2 soot sensor.";
CM_ BO_ 2566707198 "Aftertreatment 1 Diesel Particulate Filter 2 Soot 4
This message is used report the analysis frequency and associated soot sensor signal data for two of the requested analysis frequencies for aftertreatment 1 diesel particulate filter 2.";
CM_ SG_ 2566707198 SnsrFreq2SootSignal "The soot signal attenuation measurement for analysis frequency 2 for the diesel particulate filter 2 soot sensor.  See SPN 5645.";
CM_ SG_ 2566707198 SnsrAnalysisFreq2 "The analysis frequency associated with the frequency 2 soot signal for the diesel particulate filter 2 soot sensor.  See SPN 5645.";
CM_ SG_ 2566707198 SnsrFreq1SootSignal "The soot signal attenuation measurement for analysis frequency 1 for the diesel particulate filter 2 soot sensor.  See SPN 5644.";
CM_ SG_ 2566707198 SnsrAnalysisFreq1 "The analysis frequency associated with the frequency 1 soot signal for the diesel particulate filter 2 soot sensor.  See SPN 5644.";
CM_ BO_ 2566706942 "Aftertreatment 1 Diesel Particulate Filter 2 Soot 5
Diesel particulate filter soot parameters for the aftertreatment 1 diesel particulate filter 2.";
CM_ SG_ 2566706942 SnsrFreq4SootSignal "The soot signal attenuation measurement for analysis frequency 4 for the diesel particulate filter 2 soot sensor.  See SPN 5647.";
CM_ SG_ 2566706942 SnsrAnalysisFreq4 "The analysis frequency associated with the frequency 4 soot signal for the diesel particulate filter 2 soot sensor.  See SPN 5647.";
CM_ SG_ 2566706942 SnsrFreq3SootSignal "The soot signal attenuation measurement for analysis frequency 3 for the diesel particulate filter 2 soot sensor.  See SPN 5646.";
CM_ SG_ 2566706942 SnsrAnalysisFreq3 "The analysis frequency associated with the frequency 3 soot signal for the diesel particulate filter 2 soot sensor.  See SPN 5646.";
CM_ BO_ 2559770366 "Aftertreatment 1 Hydrocarbon Doser Information 1
This PGN contains information about the HC Doser and the Diesel Particulate Filter";
CM_ SG_ 2559770366 HydrocarbonDoserPurgingRequired "Purging of the Hydrocarbon Doser (HCD) is required.  Request could come from the HCD system.

00   Purging not required
01   Purging required - less urgent
10   Purging required - urgent
11   Not available";
CM_ SG_ 2559770366 DiagnosticStatusOfHCDoser "Indicates whether an error is active in the Hydrocarbon Doser (HCD) or whether the internal cyclic system test of the HCD is presently active.
This is not intended to replace the DM8/DM30 - Test results requirement for OBD.
000 System test has ...";
CM_ SG_ 2559770366 HCDoserInjectingStatus "Indicates whether the Hydrocarbon Doser (HCD) is presently injecting diesel fuel into the exhaust pipe.

00 Injecting not active
01 Injecting active
10 Error
11 Not available";
CM_ SG_ 2559770366 HCDoserStatus "Indicates whether the HC Doser/ HC Dosing system is enabled or is waiting for regeneration.
000 HC doser disabled
001 HC doser active
010 SAE reserved
011 HC doser enabled, waiting for regeneration
100 SAE reserved
101 SAE reserved
110 Error
 ...";
CM_ SG_ 2559770366 RequestedFuelMassRate "Requested fuel dosing quantity from hydrocarbon doser.";
CM_ BO_ 2559704830 "Vehicle/Chassis Lubrication System 1
Used to command a vehicle/chassis lubrication system";
CM_ SG_ 2559704830 LubricationTimingCycleCmd "Command signal to enable or pause the lubrication activation clock
00 - Pause
01 - Enable
10 - Reserved
11 - Take no action
Note:  In some vehicles or machines the lubrication is only required when the vehicle or machine is in certain state ...";
CM_ SG_ 2559704830 LubricationPumpEnableCmd "Command signal to reset the lubrication pump.  It allows the operator and/or technician to reset the paused lubrication pump and clear lubrication system faults. This shall enable the lubrication system to resume its normal operation.
00 - No ...";
CM_ SG_ 2559704830 LubricationOperationModeSetCmd "Command signal to change lubrication system operational mode. The mode set command gives the operator and/or technician the ability to change the operational mode when diagnosing and servicing of the system is required.
Automatic is the normal ...";
CM_ SG_ 2559704830 LubricationCycleSetCmd "Command signal to change the lubrication cycle. It gives the operator or technician the ability to the change the frequency of lubrication.
000 - Cycle mode # 1 (Lowest Lubrication Frequency)
001 - Cycle mode # 2
010 - Cycle mode # 3 (Highest ...";
CM_ SG_ 2559704830 LubricationCycleModeLockCmd "Command signal to lock or unlock the ability to change the lubrication cycle mode.  Locking the lubrication mode would prevent the changing of the lubrication cycle mode, perhaps by an operator.
00 - Not Locked
01 - Locked
10 - Reserved
11 - No ...";
CM_ BO_ 2559639294 "Supplemental Fan Command
Command message to control the speed and direction of Supplemental Fan for additional cooling beyond that of the primary cooling fan. For Example, this fan could be used to provide additional cooling to an aftertreatment ...";
CM_ SG_ 2559639294 SupplementalFanPowerHold "Command to allow the supplemental fan controller to remain alive independently of the electrical enable input to the fan. This allows the fan controller to remain alive after the key switch has disabled the electrical enable pin on the fan ...";
CM_ SG_ 2559639294 SupplementalFanSpeedCmd "Speed command to Supplemental Fan.";
CM_ SG_ 2559639294 SupplementalFanDirectionCmd "Direction command to the Supplemental Fan. Fan can be commanded to run forward or reverse.

00   Forward
01   Reverse
10   Reserved
11   Don't care/take no action (leave function as is)";
CM_ SG_ 2559639294 SupplementalFanEnableCmd "Enable/Disable command to Supplemental Fan.

00  Disable 
01  Enable
10  Reserved 
11  Don't Care/Take no action";
CM_ BO_ 2559573758 "Engine Configuration Commands
This PGN contains parameters that are used to configure engine operation.";
CM_ SG_ 2559573758 ClntLvlEngPrtctnShtdwnOvrrideCmd "Overrides the engine protection shutdown functionality due to low coolant level.
00 - Disable engine protection shutdown override due to low coolant level
01 - Enable engine protection shutdown override due to low coolant level
10 - Reserved
11 ...";
CM_ BO_ 2349530878 "Cruise Control / Vehicle Speed 2
Cruise Control / Vehicle Speed 2";
CM_ SG_ 2349530878 CruiseCtrlPauseCmd "This parameter is used to temporarily disable cruise control from a source other than the driver controlled switch if cruise control is active.  If this parameter is used to disable cruise control, then cruise control will not need to be ...";
CM_ SG_ 2349530878 CruiseCtrlResumeCmd "This parameter is used to request the cruise control to resume operation from a source other than the driver controlled switch.  Implementers may wish to restrict the conditions in which cruise control will be resumed due to this parameter ...";
CM_ SG_ 2349530878 CruiseCtrlDisableCmd "This parameter is used to disable cruise control from a source other than the driver controlled switch if cruise control is active.  It is also used to inhibit cruise control from becoming active if it is not currently active.  If this parameter is ...";
CM_ BO_ 2566698238 "Switched Power Output Status
Switched power output status is sent by the Power Distribution Module (PDM) to indicate the status of the PDM's switched power outputs.
This message is sent once every second (1000ms) and on change of any switched ...";
CM_ SG_ 2566698238 SwitchedOutput29 "State of Switched Output #29. Used to indicate the output state.

00 - Output off
01 - Output on
10 - Reserved
11 - Take no action";
CM_ SG_ 2566698238 SwitchedOutput30 "State of Switched Output #30. Used to indicate the output state.

00 - Output off
01 - Output on
10 - Reserved
11 - Take no action";
CM_ SG_ 2566698238 SwitchedOutput31 "State of Switched Output #31. Used to indicate the output state.

00 - Output off
01 - Output on
10 - Reserved
11 - Take no action";
CM_ SG_ 2566698238 SwitchedOutput32 "State of Switched Output #32. Used to indicate the output state.

00 - Output off
01 - Output on
10 - Reserved
11 - Take no action";
CM_ SG_ 2566698238 SwitchedOutput25 "State of Switched Output #25. Used to indicate the output state.

00 - Output off
01 - Output on
10 - Reserved
11 - Take no action";
CM_ SG_ 2566698238 SwitchedOutput26 "State of Switched Output #26. Used to indicate the output state.

00 - Output off
01 - Output on
10 - Reserved
11 - Take no action";
CM_ SG_ 2566698238 SwitchedOutput27 "State of Switched Output #27. Used to indicate the output state.

00 - Output off
01 - Output on
10 - Reserved
11 - Take no action";
CM_ SG_ 2566698238 SwitchedOutput28 "State of Switched Output #28. Used to indicate the output state.

00 - Output off
01 - Output on
10 - Reserved
11 - Take no action";
CM_ SG_ 2566698238 SwitchedOutput21 "State of Switched Output #21. Used to indicate the output state.

00 - Output off
01 - Output on
10 - Reserved
11 - Take no action";
CM_ SG_ 2566698238 SwitchedOutput22 "State of Switched Output #22. Used to indicate the output state.

00 - Output off
01 - Output on
10 - Reserved
11 - Take no action";
CM_ SG_ 2566698238 SwitchedOutput23 "State of Switched Output #23. Used to indicate the output state.

00 - Output off
01 - Output on
10 - Reserved
11 - Take no action";
CM_ SG_ 2566698238 SwitchedOutput24 "State of Switched Output #24. Used to indicate the output state.

00 - Output off
01 - Output on
10 - Reserved
11 - Take no action";
CM_ SG_ 2566698238 SwitchedOutput17 "State of Switched Output #17. Used to indicate the output state.

00 - Output off
01 - Output on
10 - Reserved
11 - Take no action";
CM_ SG_ 2566698238 SwitchedOutput18 "State of Switched Output #18. Used to indicate the output state.

00 - Output off
01 - Output on
10 - Reserved
11 - Take no action";
CM_ SG_ 2566698238 SwitchedOutput19 "State of Switched Output #19. Used to indicate the output state.

00 - Output off
01 - Output on
10 - Reserved
11 - Take no action";
CM_ SG_ 2566698238 SwitchedOutput20 "State of Switched Output #20. Used to indicate the output state.

00 - Output off
01 - Output on
10 - Reserved
11 - Take no action";
CM_ SG_ 2566698238 SwitchedOutput13 "State of Switched Output #13. Used to indicate the output state.

00 - Output off
01 - Output on
10 - Reserved
11 - Take no action";
CM_ SG_ 2566698238 SwitchedOutput14 "State of Switched Output #14. Used to indicate the output state.

00 - Output off
01 - Output on
10 - Reserved
11 - Take no action";
CM_ SG_ 2566698238 SwitchedOutput15 "State of Switched Output #15. Used to indicate the output state.

00 - Output off
01 - Output on
10 - Reserved
11 - Take no action";
CM_ SG_ 2566698238 SwitchedOutput16 "State of Switched Output #16. Used to indicate the output state.

00 - Output off
01 - Output on
10 - Reserved
11 - Take no action";
CM_ SG_ 2566698238 SwitchedOutput9 "State of Switched Output #9. Used to indicate the output state.

00 - Output off
01 - Output on
10 - Reserved
11 - Take no action";
CM_ SG_ 2566698238 SwitchedOutput10 "State of Switched Output #10. Used to indicate the output state.

00 - Output off
01 - Output on
10 - Reserved
11 - Take no action";
CM_ SG_ 2566698238 SwitchedOutput11 "State of Switched Output #11. Used to indicate the output state.

00 - Output off
01 - Output on
10 - Reserved
11 - Take no action";
CM_ SG_ 2566698238 SwitchedOutput12 "State of Switched Output #12. Used to indicate the output state.

00 - Output off
01 - Output on
10 - Reserved
11 - Take no action";
CM_ SG_ 2566698238 SwitchedOutput5 "State of Switched Output #5. Used to indicate the output state.

00 - Output off
01 - Output on
10 - Reserved
11 - Take no action";
CM_ SG_ 2566698238 SwitchedOutput6 "State of Switched Output #6. Used to indicate the output state.

00 - Output off
01 - Output on
10 - Reserved
11 - Take no action";
CM_ SG_ 2566698238 SwitchedOutput7 "State of Switched Output #7. Used to indicate the output state.

00 - Output off
01 - Output on
10 - Reserved
11 - Take no action";
CM_ SG_ 2566698238 SwitchedOutput8 "State of Switched Output #8. Used to indicate the output state.

00 - Output off
01 - Output on
10 - Reserved
11 - Take no action";
CM_ SG_ 2566698238 SwitchedOutput1 "State of Switched Output #1. Used to indicate the output state.

00 - Output off
01 - Output on
10 - Reserved
11 - Take no action";
CM_ SG_ 2566698238 SwitchedOutput2 "State of Switched Output #2. Used to indicate the output state.

00 - Output off
01 - Output on
10 - Reserved
11 - Take no action";
CM_ SG_ 2566698238 SwitchedOutput3 "State of Switched Output #3. Used to indicate the output state.

00 - Output off
01 - Output on
10 - Reserved
11 - Take no action";
CM_ SG_ 2566698238 SwitchedOutput4 "State of Switched Output #4. Used to indicate the output state.

00 - Output off
01 - Output on
10 - Reserved
11 - Take no action";
CM_ BO_ 2566697982 "Fused Power Output Current
Fused power output current reports the measured electrical current flowing out of all fused outputs on the Power Distribution Module (PDM).";
CM_ SG_ 2566697982 FusedOutput32Current "Measured electrical current flowing out of Power Distribution Module (PDM) Fused Output #32.";
CM_ SG_ 2566697982 FusedOutput31Current "Measured electrical current flowing out of Power Distribution Module (PDM) Fused Output #31.";
CM_ SG_ 2566697982 FusedOutput30Current "Measured electrical current flowing out of Power Distribution Module (PDM) Fused Output #30.";
CM_ SG_ 2566697982 FusedOutput29Current "Measured electrical current flowing out of Power Distribution Module (PDM) Fused Output #29.";
CM_ SG_ 2566697982 FusedOutput28Current "Measured electrical current flowing out of Power Distribution Module (PDM) Fused Output #28.";
CM_ SG_ 2566697982 FusedOutput27Current "Measured electrical current flowing out of Power Distribution Module (PDM) Fused Output #27.";
CM_ SG_ 2566697982 FusedOutput26Current "Measured electrical current flowing out of Power Distribution Module (PDM) Fused Output #26.";
CM_ SG_ 2566697982 FusedOutput25Current "Measured electrical current flowing out of Power Distribution Module (PDM) Fused Output #25.";
CM_ SG_ 2566697982 FusedOutput24Current "Measured electrical current flowing out of Power Distribution Module (PDM) Fused Output #24.";
CM_ SG_ 2566697982 FusedOutput23Current "Measured electrical current flowing out of Power Distribution Module (PDM) Fused Output #23.";
CM_ SG_ 2566697982 FusedOutput22Current "Measured electrical current flowing out of Power Distribution Module (PDM) Fused Output #22.";
CM_ SG_ 2566697982 FusedOutput21Current "Measured electrical current flowing out of Power Distribution Module (PDM) Fused Output #21.";
CM_ SG_ 2566697982 FusedOutput20Current "Measured electrical current flowing out of Power Distribution Module (PDM) Fused Output #20.";
CM_ SG_ 2566697982 FusedOutput19Current "Measured electrical current flowing out of Power Distribution Module (PDM) Fused Output #19.";
CM_ SG_ 2566697982 FusedOutput18Current "Measured electrical current flowing out of Power Distribution Module (PDM) Fused Output #18.";
CM_ SG_ 2566697982 FusedOutput17Current "Measured electrical current flowing out of Power Distribution Module (PDM) Fused Output #17.";
CM_ SG_ 2566697982 FusedOutput16Current "Measured electrical current flowing out of Power Distribution Module (PDM) Fused Output #16.";
CM_ SG_ 2566697982 FusedOutput15Current "Measured electrical current flowing out of Power Distribution Module (PDM) Fused Output #15.";
CM_ SG_ 2566697982 FusedOutput14Current "Measured electrical current flowing out of Power Distribution Module (PDM) Fused Output #14.";
CM_ SG_ 2566697982 FusedOutput13Current "Measured electrical current flowing out of Power Distribution Module (PDM) Fused Output #13.";
CM_ SG_ 2566697982 FusedOutput12Current "Measured electrical current flowing out of Power Distribution Module (PDM) Fused Output #12.";
CM_ SG_ 2566697982 FusedOutput11Current "Measured electrical current flowing out of Power Distribution Module (PDM) Fused Output #11.";
CM_ SG_ 2566697982 FusedOutput10Current "Measured electrical current flowing out of Power Distribution Module (PDM) Fused Output #10.";
CM_ SG_ 2566697982 FusedOutput9Current "Measured electrical current flowing out of Power Distribution Module (PDM) Fused Output #9.";
CM_ SG_ 2566697982 FusedOutput8Current "Measured electrical current flowing out of Power Distribution Module (PDM) Fused Output #8.";
CM_ SG_ 2566697982 FusedOutput7Current "Measured electrical current flowing out of Power Distribution Module (PDM) Fused Output #7.";
CM_ SG_ 2566697982 FusedOutput6Current "Measured electrical current flowing out of Power Distribution Module (PDM) Fused Output #6.";
CM_ SG_ 2566697982 FusedOutput5Current "Measured electrical current flowing out of Power Distribution Module (PDM) Fused Output #5.";
CM_ SG_ 2566697982 FusedOutput4Current "Measured electrical current flowing out of Power Distribution Module (PDM) Fused Output #4.";
CM_ SG_ 2566697982 FusedOutput3Current "Measured electrical current flowing out of Power Distribution Module (PDM) Fused Output #3.";
CM_ SG_ 2566697982 FusedOutput2Current "Measured electrical current flowing out of Power Distribution Module (PDM) Fused Output #2.";
CM_ SG_ 2566697982 FusedOutput1Current "Measured electrical current flowing out of Power Distribution Module (PDM) Fused Output #1.";
CM_ BO_ 2566697726 "Switched Power Output Current
Switched power output current reports the measured electrical current flowing out of all switched
outputs on the Power Distribution Module (PDM).";
CM_ SG_ 2566697726 SwitchedOutput32Current "Measured electrical current flowing out of Power Distribution Module (PDM) Switched Output #32.";
CM_ SG_ 2566697726 SwitchedOutput31Current "Measured electrical current flowing out of Power Distribution Module (PDM) Switched Output #31.";
CM_ SG_ 2566697726 SwitchedOutput30Current "Measured electrical current flowing out of Power Distribution Module (PDM) Switched Output #30.";
CM_ SG_ 2566697726 SwitchedOutput29Current "Measured electrical current flowing out of Power Distribution Module (PDM) Switched Output #29.";
CM_ SG_ 2566697726 SwitchedOutput28Current "Measured electrical current flowing out of Power Distribution Module (PDM) Switched Output #28.";
CM_ SG_ 2566697726 SwitchedOutput27Current "Measured electrical current flowing out of Power Distribution Module (PDM) Switched Output #27.";
CM_ SG_ 2566697726 SwitchedOutput26Current "Measured electrical current flowing out of Power Distribution Module (PDM) Switched Output #26.";
CM_ SG_ 2566697726 SwitchedOutput25Current "Measured electrical current flowing out of Power Distribution Module (PDM) Switched Output #25.";
CM_ SG_ 2566697726 SwitchedOutput24Current "Measured electrical current flowing out of Power Distribution Module (PDM) Switched Output #24.";
CM_ SG_ 2566697726 SwitchedOutput23Current "Measured electrical current flowing out of Power Distribution Module (PDM) Switched Output #23.";
CM_ SG_ 2566697726 SwitchedOutput22Current "Measured electrical current flowing out of Power Distribution Module (PDM) Switched Output #22.";
CM_ SG_ 2566697726 SwitchedOutput21Current "Measured electrical current flowing out of Power Distribution Module (PDM) Switched Output #21.";
CM_ SG_ 2566697726 SwitchedOutput20Current "Measured electrical current flowing out of Power Distribution Module (PDM) Switched Output #20.";
CM_ SG_ 2566697726 SwitchedOutput19Current "Measured electrical current flowing out of Power Distribution Module (PDM) Switched Output #19.";
CM_ SG_ 2566697726 SwitchedOutput18Current "Measured electrical current flowing out of Power Distribution Module (PDM) Switched Output #18.";
CM_ SG_ 2566697726 SwitchedOutput17Current "Measured electrical current flowing out of Power Distribution Module (PDM) Switched Output #17.";
CM_ SG_ 2566697726 SwitchedOutput16Current "Measured electrical current flowing out of Power Distribution Module (PDM) Switched Output #16.";
CM_ SG_ 2566697726 SwitchedOutput15Current "Measured electrical current flowing out of Power Distribution Module (PDM) Switched Output #15.";
CM_ SG_ 2566697726 SwitchedOutput14Current "Measured electrical current flowing out of Power Distribution Module (PDM) Switched Output #14.";
CM_ SG_ 2566697726 SwitchedOutput13Current "Measured electrical current flowing out of Power Distribution Module (PDM) Switched Output #13.";
CM_ SG_ 2566697726 SwitchedOutput12Current "Measured electrical current flowing out of Power Distribution Module (PDM) Switched Output #12.";
CM_ SG_ 2566697726 SwitchedOutput11Current "Measured electrical current flowing out of Power Distribution Module (PDM) Switched Output #11.";
CM_ SG_ 2566697726 SwitchedOutput10Current "Measured electrical current flowing out of Power Distribution Module (PDM) Switched Output #10.";
CM_ SG_ 2566697726 SwitchedOutput9Current "Measured electrical current flowing out of Power Distribution Module (PDM) Switched Output #9.";
CM_ SG_ 2566697726 SwitchedOutput8Current "Measured electrical current flowing out of Power Distribution Module (PDM) Switched Output #8.";
CM_ SG_ 2566697726 SwitchedOutput7Current "Measured electrical current flowing out of Power Distribution Module (PDM) Switched Output #7.";
CM_ SG_ 2566697726 SwitchedOutput6Current "Measured electrical current flowing out of Power Distribution Module (PDM) Switched Output #6.";
CM_ SG_ 2566697726 SwitchedOutput5Current "Measured electrical current flowing out of Power Distribution Module (PDM) Switched Output #5.";
CM_ SG_ 2566697726 SwitchedOutput4Current "Measured electrical current flowing out of Power Distribution Module (PDM) Switched Output #4.";
CM_ SG_ 2566697726 SwitchedOutput3Current "Measured electrical current flowing out of Power Distribution Module (PDM) Switched Output #3.";
CM_ SG_ 2566697726 SwitchedOutput2Current "Measured electrical current flowing out of Power Distribution Module (PDM) Switched Output #2.";
CM_ SG_ 2566697726 SwitchedOutput1Current "Measured electrical current flowing out of Power Distribution Module (PDM) Switched Output #1.";
CM_ BO_ 2566697470 "Engine Ignition Control Module Status
Contains Operating Status, Control State, and Physical Status of the Engine Ignition Control Module";
CM_ SG_ 2566697470 EngIgntCtrlModule2State "This parameter is used to indicate the current state of Engine Ignition Control Module 2.
000 - Disabled (by user)
001 - Shutdown (due to alarm)
010 - Stalled (waiting for timing signals)
011 - Firing Ignition in Test Mode
100 - Firing Ignition ...";
CM_ SG_ 2566697470 EngIgntCtrlModule1State "This parameter is used to indicate the current state of Engine Ignition Control Module 1.
000 - Disabled (by user)
001 - Shutdown (due to alarm)
010 - Stalled (waiting for timing signals)
011 - Firing Ignition in Test Mode
100 - Firing Ignition ...";
CM_ SG_ 2566697470 EngIgntCtrlModule2Temp "Measured internal temperature of the Engine Ignition Control Module 2 circuitry.";
CM_ SG_ 2566697470 EngIgntCtrlModule1Temp "Measured internal temperature of the Engine Ignition Control Module 1 circuitry.";
CM_ BO_ 2633806078 "Engine Ignition Controller Maintenance Hours
Contains Maintenance Hours of the Engine Ignition Control Module";
CM_ SG_ 2633806078 EngIgntCtrlModule2TimeRemaining "This parameter reports the time remaining before maintenance should be performed on engine ignition control module instance 2.  Upon maintenance, the time is reset to its starting value using Reset PGN 56832, Ignition Control Maintenance Hours ...";
CM_ SG_ 2633806078 EngIgntCtrlModule1TimeRemaining "This parameter reports the time remaining before maintenance should be performed on engine ignition control module instance 1.  Upon maintenance, the time is reset to its starting value using Reset PGN 56832, Ignition Control Maintenance Hours ...";
CM_ BO_ 2633805822 "Engine Spark Minimum Voltage 1
The PGN contains information about minimum spark voltage values for cylinders 1 through 4. This is the secondary voltage of the combustion event.
This PGN may be used together with PGN 64887 which conveys the average ...";
CM_ SG_ 2633805822 EngSparkPlug4MinVoltage "The smallest measured spark voltage of all measured spark events on Cylinder #4 since the last time this tracking data was reset.  It is reset using Reset PGN 56832, Engine Spark Plug Secondary Voltage Tracking Reset SPN 6218.";
CM_ SG_ 2633805822 EngSparkPlug3MinVoltage "The smallest measured spark voltage of all measured spark events on Cylinder #3 since the last time this tracking data was reset.  It is reset using Reset PGN 56832, Engine Spark Plug Secondary Voltage Tracking Reset SPN 6218.";
CM_ SG_ 2633805822 EngSparkPlug2MinVoltage "The smallest measured spark voltage of all measured spark events on Cylinder #2 since the last time this tracking data was reset.  It is reset using Reset PGN 56832, Engine Spark Plug Secondary Voltage Tracking Reset SPN 6218.";
CM_ SG_ 2633805822 EngSparkPlug1MinVoltage "The smallest measured spark voltage of all measured spark events on Cylinder #1 since the last time this tracking data was reset.  It is reset using Reset PGN 56832, Engine Spark Plug Secondary Voltage Tracking Reset SPN 6218.";
CM_ BO_ 2633805566 "Engine Spark Minimum Voltage 2
The PGN contains information about minimum spark voltage values for cylinders 5 through 8. This is the secondary voltage of the combustion event.
This PGN may be used together with PGN 64886 which conveys the average ...";
CM_ SG_ 2633805566 EngSparkPlug8MinVoltage "The smallest measured spark voltage of all measured spark events on Cylinder #8 since the last time this tracking data was reset.  It is reset using Reset PGN 56832, Engine Spark Plug Secondary Voltage Tracking Reset SPN 6218.";
CM_ SG_ 2633805566 EngSparkPlug7MinVoltage "The smallest measured spark voltage of all measured spark events on Cylinder #7 since the last time this tracking data was reset.  It is reset using Reset PGN 56832, Engine Spark Plug Secondary Voltage Tracking Reset SPN 6218.";
CM_ SG_ 2633805566 EngSparkPlug6MinVoltage "The smallest measured spark voltage of all measured spark events on Cylinder #6 since the last time this tracking data was reset.  It is reset using Reset PGN 56832, Engine Spark Plug Secondary Voltage Tracking Reset SPN 6218.";
CM_ SG_ 2633805566 EngSparkPlug5MinVoltage "The smallest measured spark voltage of all measured spark events on Cylinder #5 since the last time this tracking data was reset.  It is reset using Reset PGN 56832, Engine Spark Plug Secondary Voltage Tracking Reset SPN 6218.";
CM_ BO_ 2633805310 "Engine Spark Minimum Voltage 3
The PGN contains information about minimum spark voltage values for cylinders 9 through 12. This is the secondary voltage of the combustion event.
This PGN may be used together with PGN 64885 which conveys the ...";
CM_ SG_ 2633805310 EngSparkPlug12MinVoltage "The smallest measured spark voltage of all measured spark events on Cylinder #12 since the last time this tracking data was reset.  It is reset using Reset PGN 56832, Engine Spark Plug Secondary Voltage Tracking Reset SPN 6218.";
CM_ SG_ 2633805310 EngSparkPlug11MinVoltage "The smallest measured spark voltage of all measured spark events on Cylinder #11 since the last time this tracking data was reset.  It is reset using Reset PGN 56832, Engine Spark Plug Secondary Voltage Tracking Reset SPN 6218.";
CM_ SG_ 2633805310 EngSparkPlug10MinVoltage "The smallest measured spark voltage of all measured spark events on Cylinder #10 since the last time this tracking data was reset.  It is reset using Reset PGN 56832, Engine Spark Plug Secondary Voltage Tracking Reset SPN 6218.";
CM_ SG_ 2633805310 EngSparkPlug9MinVoltage "The smallest measured spark voltage of all measured spark events on Cylinder #9 since the last time this tracking data was reset.  It is reset using Reset PGN 56832, Engine Spark Plug Secondary Voltage Tracking Reset SPN 6218.";
CM_ BO_ 2633805054 "Engine Spark Minimum Voltage 4
The PGN contains information about minimum spark voltage values for cylinders 13 through 16. This is the secondary voltage of the combustion event.
This PGN may be used together with PGN 64884 which conveys the ...";
CM_ SG_ 2633805054 EngSparkPlug16MinVoltage "The smallest measured spark voltage of all measured spark events on Cylinder #16 since the last time this tracking data was reset.  It is reset using Reset PGN 56832, Engine Spark Plug Secondary Voltage Tracking Reset SPN 6218.";
CM_ SG_ 2633805054 EngSparkPlug15MinVoltage "The smallest measured spark voltage of all measured spark events on Cylinder #15 since the last time this tracking data was reset.  It is reset using Reset PGN 56832, Engine Spark Plug Secondary Voltage Tracking Reset SPN 6218.";
CM_ SG_ 2633805054 EngSparkPlug14MinVoltage "The smallest measured spark voltage of all measured spark events on Cylinder #14 since the last time this tracking data was reset.  It is reset using Reset PGN 56832, Engine Spark Plug Secondary Voltage Tracking Reset SPN 6218.";
CM_ SG_ 2633805054 EngSparkPlug13MinVoltage "The smallest measured spark voltage of all measured spark events on Cylinder #13 since the last time this tracking data was reset.  It is reset using Reset PGN 56832, Engine Spark Plug Secondary Voltage Tracking Reset SPN 6218.";
CM_ BO_ 2633804798 "Engine Spark Minimum Voltage 5
The PGN contains information about minimum spark voltage values for cylinders 17 through 20. This is the secondary voltage of the combustion event.
This PGN may be used together with PGN 64883 which conveys the ...";
CM_ SG_ 2633804798 EngSparkPlug20MinVoltage "The smallest measured spark voltage of all measured spark events on Cylinder #20 since the last time this tracking data was reset.  It is reset using Reset PGN 56832, Engine Spark Plug Secondary Voltage Tracking Reset SPN 6218.";
CM_ SG_ 2633804798 EngSparkPlug19MinVoltage "The smallest measured spark voltage of all measured spark events on Cylinder #19 since the last time this tracking data was reset.  It is reset using Reset PGN 56832, Engine Spark Plug Secondary Voltage Tracking Reset SPN 6218.";
CM_ SG_ 2633804798 EngSparkPlug18MinVoltage "The smallest measured spark voltage of all measured spark events on Cylinder #18 since the last time this tracking data was reset.  It is reset using Reset PGN 56832, Engine Spark Plug Secondary Voltage Tracking Reset SPN 6218.";
CM_ SG_ 2633804798 EngSparkPlug17MinVoltage "The smallest measured spark voltage of all measured spark events on Cylinder #17 since the last time this tracking data was reset.  It is reset using Reset PGN 56832, Engine Spark Plug Secondary Voltage Tracking Reset SPN 6218.";
CM_ BO_ 2633804542 "Engine Spark Minimum Voltage 6
The PGN contains information about minimum spark voltage values for cylinders 21 through 24. This is the secondary voltage of the combustion event.
This PGN may be used together with PGN 64882 which conveys the ...";
CM_ SG_ 2633804542 EngSparkPlug24MinVoltage "The smallest measured spark voltage of all measured spark events on Cylinder #24 since the last time this tracking data was reset.  It is reset using Reset PGN 56832, Engine Spark Plug Secondary Voltage Tracking Reset SPN 6218.";
CM_ SG_ 2633804542 EngSparkPlug23MinVoltage "The smallest measured spark voltage of all measured spark events on Cylinder #23 since the last time this tracking data was reset.  It is reset using Reset PGN 56832, Engine Spark Plug Secondary Voltage Tracking Reset SPN 6218.";
CM_ SG_ 2633804542 EngSparkPlug22MinVoltage "The smallest measured spark voltage of all measured spark events on Cylinder #22 since the last time this tracking data was reset.  It is reset using Reset PGN 56832, Engine Spark Plug Secondary Voltage Tracking Reset SPN 6218.";
CM_ SG_ 2633804542 EngSparkPlug21MinVoltage "The smallest measured spark voltage of all measured spark events on Cylinder #21 since the last time this tracking data was reset.  It is reset using Reset PGN 56832, Engine Spark Plug Secondary Voltage Tracking Reset SPN 6218.";
CM_ BO_ 2633804286 "Engine Spark Maximum Voltage 1
The PGN contains information about maximum spark voltage values for cylinders 1 through 4. This is the secondary voltage of the combustion event.
This PGN may be used together with PGN 64887 which conveys the average ...";
CM_ SG_ 2633804286 EngSparkPlug4MaxVoltage "The largest measured spark voltage of all measured spark events on Cylinder #4 since the last time this tracking data was reset.  It is reset using Reset PGN 56832, Engine Spark Plug Secondary Voltage Tracking Reset SPN 6218.";
CM_ SG_ 2633804286 EngSparkPlug3MaxVoltage "The largest measured spark voltage of all measured spark events on Cylinder #3 since the last time this tracking data was reset.  It is reset using Reset PGN 56832, Engine Spark Plug Secondary Voltage Tracking Reset SPN 6218.";
CM_ SG_ 2633804286 EngSparkPlug2MaxVoltage "The largest measured spark voltage of all measured spark events on Cylinder #2 since the last time this tracking data was reset.  It is reset using Reset PGN 56832, Engine Spark Plug Secondary Voltage Tracking Reset SPN 6218.";
CM_ SG_ 2633804286 EngSparkPlug1MaxVoltage "The largest measured spark voltage of all measured spark events on Cylinder #1 since the last time this tracking data was reset.  It is reset using Reset PGN 56832, Engine Spark Plug Secondary Voltage Tracking Reset SPN 6218.";
CM_ BO_ 2633804030 "Engine Spark Maximum Voltage 2
The PGN contains information about maximum spark voltage values for cylinders 5 through 8. This is the secondary voltage of the combustion event.
This PGN may be used together with PGN 64886 which conveys the average ...";
CM_ SG_ 2633804030 EngSparkPlug8MaxVoltage "The largest measured spark voltage of all measured spark events on Cylinder #8 since the last time this tracking data was reset.  It is reset using Reset PGN 56832, Engine Spark Plug Secondary Voltage Tracking Reset SPN 6218.";
CM_ SG_ 2633804030 EngSparkPlug7MaxVoltage "The largest measured spark voltage of all measured spark events on Cylinder #7 since the last time this tracking data was reset.  It is reset using Reset PGN 56832, Engine Spark Plug Secondary Voltage Tracking Reset SPN 6218.";
CM_ SG_ 2633804030 EngSparkPlug6MaxVoltage "The largest measured spark voltage of all measured spark events on Cylinder #6 since the last time this tracking data was reset.  It is reset using Reset PGN 56832, Engine Spark Plug Secondary Voltage Tracking Reset SPN 6218.";
CM_ SG_ 2633804030 EngSparkPlug5MaxVoltage "The largest measured spark voltage of all measured spark events on Cylinder #5 since the last time this tracking data was reset.  It is reset using Reset PGN 56832, Engine Spark Plug Secondary Voltage Tracking Reset SPN 6218.";
CM_ BO_ 2633803774 "Engine Spark Maximum Voltage 3
The PGN contains information about maximum spark voltage values for cylinders 9 through 12. This is the secondary voltage of the combustion event.
This PGN may be used together with PGN 64885 which conveys the ...";
CM_ SG_ 2633803774 EngSparkPlug12MaxVoltage "The largest measured spark voltage of all measured spark events on Cylinder #12 since the last time this tracking data was reset.  It is reset using Reset PGN 56832, Engine Spark Plug Secondary Voltage Tracking Reset SPN 6218.";
CM_ SG_ 2633803774 EngSparkPlug11MaxVoltage "The largest measured spark voltage of all measured spark events on Cylinder #11 since the last time this tracking data was reset.  It is reset using Reset PGN 56832, Engine Spark Plug Secondary Voltage Tracking Reset SPN 6218.";
CM_ SG_ 2633803774 EngSparkPlug10MaxVoltage "The largest measured spark voltage of all measured spark events on Cylinder #10 since the last time this tracking data was reset.  It is reset using Reset PGN 56832, Engine Spark Plug Secondary Voltage Tracking Reset SPN 6218.";
CM_ SG_ 2633803774 EngSparkPlug9MaxVoltage "The largest measured spark voltage of all measured spark events on Cylinder #9 since the last time this tracking data was reset.  It is reset using Reset PGN 56832, Engine Spark Plug Secondary Voltage Tracking Reset SPN 6218.";
CM_ BO_ 2633803518 "Engine Spark Maximum Voltage 4
The PGN contains information about maximum spark voltage values for cylinders 13 through 16.
This is the secondary voltage of the combustion event.
This PGN may be used together with PGN 64884 which conveys the ...";
CM_ SG_ 2633803518 EngSparkPlug16MaxVoltage "The largest measured spark voltage of all measured spark events on Cylinder #16 since the last time this tracking data was reset.  It is reset using Reset PGN 56832, Engine Spark Plug Secondary Voltage Tracking Reset SPN 6218.";
CM_ SG_ 2633803518 EngSparkPlug15MaxVoltage "The largest measured spark voltage of all measured spark events on Cylinder #15 since the last time this tracking data was reset.  It is reset using Reset PGN 56832, Engine Spark Plug Secondary Voltage Tracking Reset SPN 6218.";
CM_ SG_ 2633803518 EngSparkPlug14MaxVoltage "The largest measured spark voltage of all measured spark events on Cylinder #14 since the last time this tracking data was reset.  It is reset using Reset PGN 56832, Engine Spark Plug Secondary Voltage Tracking Reset SPN 6218.";
CM_ SG_ 2633803518 EngSparkPlug13MaxVoltage "The largest measured spark voltage of all measured spark events on Cylinder #13 since the last time this tracking data was reset.  It is reset using Reset PGN 56832, Engine Spark Plug Secondary Voltage Tracking Reset SPN 6218.";
CM_ BO_ 2633803262 "Engine Spark Maximum Voltage 5
The PGN contains information about maximum spark voltage values for cylinders 17 through 20.
This is the secondary voltage of the combustion event.
This PGN may be used together with PGN 64883 which conveys the ...";
CM_ SG_ 2633803262 EngSparkPlug20MaxVoltage "The largest measured spark voltage of all measured spark events on Cylinder #20 since the last time this tracking data was reset.  It is reset using Reset PGN 56832, Engine Spark Plug Secondary Voltage Tracking Reset SPN 6218.";
CM_ SG_ 2633803262 EngSparkPlug19MaxVoltage "The largest measured spark voltage of all measured spark events on Cylinder #19 since the last time this tracking data was reset.  It is reset using Reset PGN 56832, Engine Spark Plug Secondary Voltage Tracking Reset SPN 6218.";
CM_ SG_ 2633803262 EngSparkPlug18MaxVoltage "The largest measured spark voltage of all measured spark events on Cylinder #18 since the last time this tracking data was reset.  It is reset using Reset PGN 56832, Engine Spark Plug Secondary Voltage Tracking Reset SPN 6218.";
CM_ SG_ 2633803262 EngSparkPlug17MaxVoltage "The largest measured spark voltage of all measured spark events on Cylinder #17 since the last time this tracking data was reset.  It is reset using Reset PGN 56832, Engine Spark Plug Secondary Voltage Tracking Reset SPN 6218.";
CM_ BO_ 2633803006 "Engine Spark Maximum Voltage 6
The PGN contains information about maximum spark voltage values for cylinders 21 through 24.
This is the secondary voltage of the combustion event.
This PGN may be used together with PGN 64882 which conveys the ...";
CM_ SG_ 2633803006 EngSparkPlug24MaxVoltage "The largest measured spark voltage of all measured spark events on Cylinder #24 since the last time this tracking data was reset.  It is reset using Reset PGN 56832, Engine Spark Plug Secondary Voltage Tracking Reset SPN 6218.";
CM_ SG_ 2633803006 EngSparkPlug23MaxVoltage "The largest measured spark voltage of all measured spark events on Cylinder #23 since the last time this tracking data was reset.  It is reset using Reset PGN 56832, Engine Spark Plug Secondary Voltage Tracking Reset SPN 6218.";
CM_ SG_ 2633803006 EngSparkPlug22MaxVoltage "The largest measured spark voltage of all measured spark events on Cylinder #22 since the last time this tracking data was reset.  It is reset using Reset PGN 56832, Engine Spark Plug Secondary Voltage Tracking Reset SPN 6218.";
CM_ SG_ 2633803006 EngSparkPlug21MaxVoltage "The largest measured spark voltage of all measured spark events on Cylinder #21 since the last time this tracking data was reset.  It is reset using Reset PGN 56832, Engine Spark Plug Secondary Voltage Tracking Reset SPN 6218.";
CM_ BO_ 2633802750 "Engine Spark Misfire Rate 1
The PGN contains information about spark misfire rate for cylinders 1 through 8. The misfire rate is conveyed as the number of cylinder spark misfires divided by the number of in spark ignition events on the same ...";
CM_ SG_ 2633802750 EngSparkPlug8MisfireRate "The spark misfire rate for Cylinder #8. The misfire rate is conveyed as the percentage of total cylinder spark misfires compared to the total number of ignition events on Cylinder #8 since the last time this tracking data was reset.  Any averaging ...";
CM_ SG_ 2633802750 EngSparkPlug7MisfireRate "The spark misfire rate for Cylinder #7. The misfire rate is conveyed as the percentage of total cylinder spark misfires compared to the total number of ignition events on Cylinder #7 since the last time this tracking data was reset.  Any averaging ...";
CM_ SG_ 2633802750 EngSparkPlug6MisfireRate "The spark misfire rate for Cylinder #6. The misfire rate is conveyed as the percentage of total cylinder spark misfires compared to the total number of ignition events on Cylinder #6 since the last time this tracking data was reset.  Any averaging ...";
CM_ SG_ 2633802750 EngSparkPlug5MisfireRate "The spark misfire rate for Cylinder #5. The misfire rate is conveyed as the percentage of total cylinder spark misfires compared to the total number of ignition events on Cylinder #5 since the last time this tracking data was reset.  Any averaging ...";
CM_ SG_ 2633802750 EngSparkPlug4MisfireRate "The spark misfire rate for Cylinder #4. The misfire rate is conveyed as the percentage of total cylinder spark misfires compared to the total number of ignition events on Cylinder #4 since the last time this tracking data was reset.  Any averaging ...";
CM_ SG_ 2633802750 EngSparkPlug3MisfireRate "The spark misfire rate for Cylinder #3. The misfire rate is conveyed as the percentage of total cylinder spark misfires compared to the total number of ignition events on Cylinder #3 since the last time this tracking data was reset.  Any averaging ...";
CM_ SG_ 2633802750 EngSparkPlug2MisfireRate "The spark misfire rate for Cylinder #2. The misfire rate is conveyed as the percentage of total cylinder spark misfires compared to the total number of ignition events on Cylinder #2 since the last time this tracking data was reset.  Any averaging ...";
CM_ SG_ 2633802750 EngSparkPlug1MisfireRate "The spark misfire rate for Cylinder #1. The misfire rate is conveyed as the percentage of total cylinder spark misfires compared to the total number of ignition events on Cylinder #1 since the last time this tracking data was reset.  Any averaging ...";
CM_ BO_ 2633802494 "Engine Spark Misfire Rate 2
The PGN contains information about spark misfire rate for cylinders 9 through 16. The misfire rate is conveyed as the number of cylinder spark misfires divided by the number of in spark ignition events on the same ...";
CM_ SG_ 2633802494 EngSparkPlug16MisfireRate "The spark misfire rate for Cylinder #16. The misfire rate is conveyed as the percentage of total cylinder spark misfires compared to the total number of ignition events on Cylinder #16 since the last time this tracking data was reset.  Any averaging ...";
CM_ SG_ 2633802494 EngSparkPlug15MisfireRate "The spark misfire rate for Cylinder #15. The misfire rate is conveyed as the percentage of total cylinder spark misfires compared to the total number of ignition events on Cylinder #15 since the last time this tracking data was reset.  Any averaging ...";
CM_ SG_ 2633802494 EngSparkPlug14MisfireRate "The spark misfire rate for Cylinder #14. The misfire rate is conveyed as the percentage of total cylinder spark misfires compared to the total number of ignition events on Cylinder #14 since the last time this tracking data was reset.  Any averaging ...";
CM_ SG_ 2633802494 EngSparkPlug13MisfireRate "The spark misfire rate for Cylinder #13. The misfire rate is conveyed as the percentage of total cylinder spark misfires compared to the total number of ignition events on Cylinder #13 since the last time this tracking data was reset.  Any averaging ...";
CM_ SG_ 2633802494 EngSparkPlug12MisfireRate "The spark misfire rate for Cylinder #12. The misfire rate is conveyed as the percentage of total cylinder spark misfires compared to the total number of ignition events on Cylinder #12 since the last time this tracking data was reset.  Any averaging ...";
CM_ SG_ 2633802494 EngSparkPlug11MisfireRate "The spark misfire rate for Cylinder #11. The misfire rate is conveyed as the percentage of total cylinder spark misfires compared to the total number of ignition events on Cylinder #11 since the last time this tracking data was reset.  Any averaging ...";
CM_ SG_ 2633802494 EngSparkPlug10MisfireRate "The spark misfire rate for Cylinder #10. The misfire rate is conveyed as the percentage of total cylinder spark misfires compared to the total number of ignition events on Cylinder #10 since the last time this tracking data was reset.  Any averaging ...";
CM_ SG_ 2633802494 EngSparkPlug9MisfireRate "The spark misfire rate for Cylinder #9. The misfire rate is conveyed as the percentage of total cylinder spark misfires compared to the total number of ignition events on Cylinder #9 since the last time this tracking data was reset.  Any averaging ...";
CM_ BO_ 2633802238 "Engine Spark Misfire Rate 3
The PGN contains information about spark misfire rate for cylinders 17 through 24. The misfire rate is conveyed as the number of cylinder spark misfires divided by the number of in spark ignition events on the same ...";
CM_ SG_ 2633802238 EngSparkPlug24MisfireRate "The spark misfire rate for Cylinder #24. The misfire rate is conveyed as the percentage of total cylinder spark misfires compared to the total number of ignition events on Cylinder #24 since the last time this tracking data was reset.  Any averaging ...";
CM_ SG_ 2633802238 EngSparkPlug23MisfireRate "The spark misfire rate for Cylinder #23. The misfire rate is conveyed as the percentage of total cylinder spark misfires compared to the total number of ignition events on Cylinder #23 since the last time this tracking data was reset.  Any averaging ...";
CM_ SG_ 2633802238 EngSparkPlug22MisfireRate "The spark misfire rate for Cylinder #22. The misfire rate is conveyed as the percentage of total cylinder spark misfires compared to the total number of ignition events on Cylinder #22 since the last time this tracking data was reset.  Any averaging ...";
CM_ SG_ 2633802238 EngSparkPlug21MisfireRate "The spark misfire rate for Cylinder #21. The misfire rate is conveyed as the percentage of total cylinder spark misfires compared to the total number of ignition events on Cylinder #21 since the last time this tracking data was reset.  Any averaging ...";
CM_ SG_ 2633802238 EngSparkPlug20MisfireRate "The spark misfire rate for Cylinder #20. The misfire rate is conveyed as the percentage of total cylinder spark misfires compared to the total number of ignition events on Cylinder #20 since the last time this tracking data was reset.  Any averaging ...";
CM_ SG_ 2633802238 EngSparkPlug19MisfireRate "The spark misfire rate for Cylinder #19. The misfire rate is conveyed as the percentage of total cylinder spark misfires compared to the total number of ignition events on Cylinder #19 since the last time this tracking data was reset.  Any averaging ...";
CM_ SG_ 2633802238 EngSparkPlug18MisfireRate "The spark misfire rate for Cylinder #18. The misfire rate is conveyed as the percentage of total cylinder spark misfires compared to the total number of ignition events on Cylinder #18 since the last time this tracking data was reset.  Any averaging ...";
CM_ SG_ 2633802238 EngSparkPlug17MisfireRate "The spark misfire rate for Cylinder #17. The misfire rate is conveyed as the percentage of total cylinder spark misfires compared to the total number of ignition events on Cylinder #17 since the last time this tracking data was reset.  Any averaging ...";
CM_ BO_ 2633801982 "Multi-fuel Engine Hours
Engine hours parameters for multi-fuel engines";
CM_ SG_ 2633801982 EngTtlHoursOfDieselFuelOperation "Accumulated time of operation of engine when diesel fuel is used.  This parameter should be used only in multi-fuel engines.  See SPN 247 for single fuel engines and for total hours for multi-fuel engines.";
CM_ SG_ 2633801982 EngTotalHoursOfGasFuelOperation "Accumulated time of operation of engine when gaseous fuel is used.  This parameter should be used only in multi-fuel engines.  See SPN 247 for single fuel engines and for total hours for multi-fuel engines.";
CM_ BO_ 2566692862 "Dash Display 2
Dash Display for Status Information";
CM_ SG_ 2566692862 DisplayRemainPowered "Indicates the ECU needs the display (i.e. monitor device) to continue to remain powered after ignition key off. An ECU would use this when the ECU needs the display to remain powered after key off so the ECU can communicate to the operator while the ...";
CM_ SG_ 2566692862 Fuel2Tank4Level "Fuel level in tank 4 containing the second fuel type.";
CM_ SG_ 2566692862 Fuel2Tank3Level "Fuel level in tank 3 containing the second fuel type.";
CM_ SG_ 2566692862 Fuel2Tank2Level "Fuel level in tank 2 containing the second fuel type.";
CM_ SG_ 2566692862 Fuel2Tank1Level "Fuel level in tank 1 containing the second fuel type.
.";
CM_ SG_ 2566692862 EngExRangeOilFilterDiffPress "Change in engine oil differential pressure measured across the oil filter element. The differential pressure is the measured as the pressure at the filter intake with respect to the pressure at the filter outlet. This differential pressure ...";
CM_ BO_ 2499583742 "Engine Timing Actuator Position
Used to transmit position information of Engine Timing actuator 1 and 2";
CM_ SG_ 2499583742 EngTimingActuator2RequestedPos "The requested position of actuator 2 on the Engine Timing System, as determined by external system such as operator, monitoring or protection system. Requested position is sent to the Control Module sending the command the Engine Timing System ...";
CM_ SG_ 2499583742 EngTimingActuator1RequestedPos "The requested position of actuator 1 on the Engine Timing System, as determined by external system such as operator, monitoring, or protection system. Requested position is sent to the Control Module sending the command the Engine Timing System ...";
CM_ SG_ 2499583742 EngTimingActuator2 "The detected position of actuator 2 on the Engine Timing System, where the system has different timing positions depending on current operating status of the engine. Timing positions may be used to determine intake and outlet valve timings.
000 - ...";
CM_ SG_ 2499583742 EngTimingActuator1 "The detected position of actuator 1 on the Engine Timing System, where the system has different timing positions depending on current operating status of the engine. Timing positions may be used to determine intake and outlet valve timings.
000 - ...";
CM_ BO_ 2499583486 "Engine Timing Actuator Position Command
Used to trasmit the commanded position of Engine Timing actuator 1 and 2.";
CM_ SG_ 2499583486 EngTimingActuator2PosCmd "The commanded position of actuator 2 on the engine timing system by Engine Control Module.  The engine timing system has different timing positions and the timing positions may be used to determine intake and outlet valve timings.
000 - Reserved
 ...";
CM_ SG_ 2499583486 EngTimingActuator1PosCmd "The commanded position of actuator 1 on the engine timing system by Engine Control Module.  The engine timing system has different timing positions and the timing positions may be used to determine intake and outlet valve timings.
000 - Reserved
 ...";
CM_ BO_ 2566692094 "Joystick 1 Lamp Status
Feedback message to report the actual status of lamps on Joystick 1";
CM_ SG_ 2566692094 Joystick1Lamp10Status "Report the actual value of Joystick 1 Lamp 10

00 - Off
01 - On
10 - Flashing
11 - Not available";
CM_ SG_ 2566692094 Joystick1Lamp9Status "Report the actual value of Joystick 1 Lamp 9

00 - Off
01 - On
10 - Flashing
11 - Not available";
CM_ SG_ 2566692094 Joystick1Lamp8Status "Report the actual value of Joystick 1 Lamp 8

00 - Off
01 - On
10 - Flashing
11 - Not available";
CM_ SG_ 2566692094 Joystick1Lamp7Status "Report the actual value of Joystick 1 Lamp 7

00 - Off
01 - On
10 - Flashing
11 - Not available";
CM_ SG_ 2566692094 Joystick1Lamp6Status "Report the actual value of Joystick 1 Lamp 6

00 - Off
01 - On
10 - Flashing
11 - Not available";
CM_ SG_ 2566692094 Joystick1Lamp5Status "Report the actual value of Joystick 1 Lamp 5

00 - Off
01 - On
10 - Flashing
11 - Not available";
CM_ SG_ 2566692094 Joystick1Lamp4Status "Report the actual value of Joystick 1 Lamp 4

00 - Off
01 - On
10 - Flashing
11 - Not available";
CM_ SG_ 2566692094 Joystick1Lamp3Status "Report the actual value of Joystick 1 Lamp 3

00 - Off
01 - On
10 - Flashing
11 - Not available";
CM_ SG_ 2566692094 Joystick1Lamp2Status "Report the actual value of Joystick 1 Lamp 2

00 - Off
01 - On
10 - Flashing
11 - Not available";
CM_ SG_ 2566692094 Joystick1Lamp1Status "Report the actual value of Joystick 1 Lamp 1

00 - Off
01 - On
10 - Flashing
11 - Not available";
CM_ BO_ 2566691838 "Joystick 2 Lamp Status
Feedback message to report the actual status of lamps on Joystick 2";
CM_ SG_ 2566691838 Joystick2Lamp10Status "Report the actual value of Joystick 2 Lamp 10

00 - Off
01 - On
10 - Flashing
11 - Not available";
CM_ SG_ 2566691838 Joystick2Lamp9Status "Report the actual value of Joystick 2 Lamp 9

00 - Off
01 - On
10 - Flashing
11 - Not available";
CM_ SG_ 2566691838 Joystick2Lamp8Status "Report the actual value of Joystick 2 Lamp 8

00 - Off
01 - On
10 - Flashing
11 - Not available";
CM_ SG_ 2566691838 Joystick2Lamp7Status "Report the actual value of Joystick 2 Lamp 7

00 - Off
01 - On
10 - Flashing
11 - Not available";
CM_ SG_ 2566691838 Joystick2Lamp6Status "Report the actual value of Joystick 2 Lamp 6

00 - Off
01 - On
10 - Flashing
11 - Not available";
CM_ SG_ 2566691838 Joystick2Lamp5Status "Report the actual value of Joystick 2 Lamp 5

00 - Off
01 - On
10 - Flashing
11 - Not available";
CM_ SG_ 2566691838 Joystick2Lamp4Status "Report the actual value of Joystick 2 Lamp 4

00 - Off
01 - On
10 - Flashing
11 - Not available";
CM_ SG_ 2566691838 Joystick2Lamp3Status "Report the actual value of Joystick 2 Lamp 3

00 - Off
01 - On
10 - Flashing
11 - Not available";
CM_ SG_ 2566691838 Joystick2Lamp2Status "Report the actual value of Joystick 2 Lamp 2

00 - Off
01 - On
10 - Flashing
11 - Not available";
CM_ SG_ 2566691838 Joystick2Lamp1Status "Report the actual value of Joystick 2 Lamp 1

00 - Off
01 - On
10 - Flashing
11 - Not available";
CM_ BO_ 2566691582 "Joystick 3 Lamp Status
Feedback message to report the actual status of lamps on Joystick 3";
CM_ SG_ 2566691582 Joystick3Lamp10Status "Report the actual value of Joystick 3 Lamp 10

00 - Off
01 - On
10 - Flashing
11 - Not available";
CM_ SG_ 2566691582 Joystick3Lamp9Status "Report the actual value of Joystick 3 Lamp 9

00 - Off
01 - On
10 - Flashing
11 - Not available";
CM_ SG_ 2566691582 Joystick3Lamp8Status "Report the actual value of Joystick 3 Lamp 8

00 - Off
01 - On
10 - Flashing
11 - Not available";
CM_ SG_ 2566691582 Joystick3Lamp7Status "Report the actual value of Joystick 3 Lamp 7

00 - Off
01 - On
10 - Flashing
11 - Not available";
CM_ SG_ 2566691582 Joystick3Lamp6Status "Report the actual value of Joystick 3 Lamp 6

00 - Off
01 - On
10 - Flashing
11 - Not available";
CM_ SG_ 2566691582 Joystick3Lamp5Status "Report the actual value of Joystick 3 Lamp 5

00 - Off
01 - On
10 - Flashing
11 - Not available";
CM_ SG_ 2566691582 Joystick3Lamp4Status "Report the actual value of Joystick 3 Lamp 4

00 - Off
01 - On
10 - Flashing
11 - Not available";
CM_ SG_ 2566691582 Joystick3Lamp3Status "Report the actual value of Joystick 3 Lamp 3

00 - Off
01 - On
10 - Flashing
11 - Not available";
CM_ SG_ 2566691582 Joystick3Lamp2Status "Report the actual value of Joystick 3 Lamp 2

00 - Off
01 - On
10 - Flashing
11 - Not available";
CM_ SG_ 2566691582 Joystick3Lamp1Status "Report the actual value of Joystick 3 Lamp 1

00 - Off
01 - On
10 - Flashing
11 - Not available";
CM_ BO_ 2566691326 "Assembly Unit Identification
Used to transmit the identification of the assemblies fitted onto a component.
NOTE - The assembly unit identification field is variable in length. An ASCII '*' is used as a delimiter to separate multiple ...";
CM_ SG_ 2566691326 AssemblyUnitIdentification "A combination of alphanumeric characters representing the Identification number of an assembly unit installed on a component.  Multiple assembly unit IDs can be transmitted by appropriately setting Number of Assembly Unit Identification Fields (SPN ...";
CM_ SG_ 2566691326 NmbrOfAssmblyUntIdntfctionFields "Number of Assembly Unit Identification designators represented in the Assembly Unit Identification parameter group.";
CM_ BO_ 2499582206 "Vehicle Speed Limiter
Vehicle speed limiter information, including Soft Top Speed Limit information";
CM_ SG_ 2499582206 SftTpSpdLmtRmnngCntnsIntrvlDstnc "Indicates the remaining distance that the vehicle can continuously travel at the Soft Top Speed Limit.  This parameter will decrement while the Soft Top Speed Limit Active (SPN 6370) is 1 and will reset to its maximum allowed value when the Soft Top ...";
CM_ SG_ 2499582206 SoftTopSpeedLimitResetDistance "This parameter will decrement as long as the vehicle is moving. When this parameter reaches 0, it will be reset to its maximum value and continue to decrement.";
CM_ SG_ 2499582206 SftTpSpeedLimitRemainingDistance "Indicates the remaining distance that the vehicle can travel at the Soft Top Speed Limit within the larger reset window. The reset window may be distance (possibly indicated by SPN 6373), time, or something else as determined by the manufacturer.
 ...";
CM_ SG_ 2499582206 SoftTopLifetimeLimitExceeded "Greenhouse Gas Regulations limit the overall distance that Soft Top Speed can be used in relation to the total distance traveled. This parameter indicates the allowable ratio has been exceeded and Soft Top Speed is unavailable. It will become ...";
CM_ SG_ 2499582206 SoftTopSpeedLimitActive "Indicates that the current Maximum Vehicle Speed Limit (SPN 74) has been temporarily increased to the Soft Top Speed Limit. Under certain conditions, the legal speed limit allowed by the Greenhouse Gas Regulations can be increased to a speed ...";
BA_DEF_ SG_  "SigType" ENUM  "Default","Range","RangeSigned","ASCII","Discrete","Control","ReferencePGN","DTC","StringDelimiter","StringLength","StringLengthControl","MessageCounter","MessageChecksum";
BA_DEF_ SG_  "GenSigStartValue" INT 0 2147483647;
BA_DEF_ SG_  "GenSigSendType" ENUM  "Cyclic","OnWrite","OnWriteWithRepetition","OnChange","OnChangeWithRepetition","IfActive","IfActiveWithRepetition","NoSigSendType";
BA_DEF_ SG_  "GenSigILSupport" ENUM  "No","Yes";
BA_DEF_ SG_  "GenSigEVName" STRING ;
BA_DEF_ SG_  "SPN" INT 0 524287;
BA_DEF_ BO_  "TpJ1939VarDlc" ENUM  "No","Yes";
BA_DEF_ BO_  "GenMsgStartDelayTime" INT 0 100000;
BA_DEF_ BO_  "GenMsgILSupport" ENUM  "No","Yes";
BA_DEF_ BO_  "GenMsgDelayTime" INT 0 1000;
BA_DEF_ BO_  "GenMsgRequestable" INT 0 1;
BA_DEF_ BO_  "GenMsgSendType" ENUM  "cyclic","NotUsed","NotUsed","NotUsed","NotUsed","NotUsed","NotUsed","IfActive","noMsgSendType";
BA_DEF_ BO_  "VFrameFormat" ENUM  "StandardCAN","ExtendedCAN","reserved","J1939PG";
BA_DEF_ BO_  "GenMsgCycleTime" INT 0 3600000;
BA_DEF_ BO_  "SendOnChange" ENUM  "No","Yes";
BA_DEF_ SG_  "SystemSignalLongSymbol" STRING ;
BA_DEF_DEF_  "SigType" "Default";
BA_DEF_DEF_  "GenSigStartValue" 0;
BA_DEF_DEF_  "GenSigSendType" "NoSigSendType";
BA_DEF_DEF_  "GenSigILSupport" "Yes";
BA_DEF_DEF_  "GenSigEVName" "Env@Nodename_@Signame";
BA_DEF_DEF_  "SPN" 0;
BA_DEF_DEF_  "TpJ1939VarDlc" "No";
BA_DEF_DEF_  "GenMsgStartDelayTime" 0;
BA_DEF_DEF_  "GenMsgILSupport" "Yes";
BA_DEF_DEF_  "GenMsgDelayTime" 0;
BA_DEF_DEF_  "GenMsgRequestable" 1;
BA_DEF_DEF_  "GenMsgSendType" "noMsgSendType";
BA_DEF_DEF_  "VFrameFormat" "J1939PG";
BA_DEF_DEF_  "GenMsgCycleTime" 0;
BA_DEF_DEF_  "SendOnChange" "No";
BA_DEF_DEF_  "SystemSignalLongSymbol" "";
BA_ "GenMsgSendType" BO_ 2566754814 0;
BA_ "GenMsgCycleTime" BO_ 2566754814 250;
BA_ "GenMsgSendType" BO_ 2566754302 0;
BA_ "GenMsgCycleTime" BO_ 2566754302 250;
BA_ "GenMsgSendType" BO_ 2566754046 0;
BA_ "GenMsgCycleTime" BO_ 2566754046 250;
BA_ "GenMsgSendType" BO_ 2566753790 0;
BA_ "GenMsgCycleTime" BO_ 2566753790 250;
BA_ "GenMsgSendType" BO_ 2566701566 0;
BA_ "GenMsgCycleTime" BO_ 2566701566 1000;
BA_ "GenMsgSendType" BO_ 2499592446 0;
BA_ "GenMsgCycleTime" BO_ 2499592446 100;
BA_ "GenMsgSendType" BO_ 2499592190 0;
BA_ "GenMsgCycleTime" BO_ 2499592190 100;
BA_ "GenMsgSendType" BO_ 2365374206 0;
BA_ "GenMsgCycleTime" BO_ 2365374206 20;
BA_ "GenMsgSendType" BO_ 2566700030 0;
BA_ "GenMsgCycleTime" BO_ 2566700030 1000;
BA_ "GenMsgSendType" BO_ 2566699774 0;
BA_ "GenMsgCycleTime" BO_ 2566699774 1000;
BA_ "GenMsgSendType" BO_ 2566698750 0;
BA_ "GenMsgCycleTime" BO_ 2566698750 1000;
BA_ "GenMsgDelayTime" BO_ 2566698494 25;
BA_ "GenMsgSendType" BO_ 2566698494 0;
BA_ "GenMsgCycleTime" BO_ 2566698494 1000;
BA_ "GenMsgSendType" BO_ 2566707454 0;
BA_ "GenMsgCycleTime" BO_ 2566707454 1000;
BA_ "GenMsgSendType" BO_ 2566707198 0;
BA_ "GenMsgCycleTime" BO_ 2566707198 1000;
BA_ "GenMsgSendType" BO_ 2566706942 0;
BA_ "GenMsgCycleTime" BO_ 2566706942 1000;
BA_ "GenMsgSendType" BO_ 2559770366 0;
BA_ "GenMsgCycleTime" BO_ 2559770366 100;
BA_ "GenMsgSendType" BO_ 2559639294 0;
BA_ "GenMsgCycleTime" BO_ 2559639294 1000;
BA_ "GenMsgDelayTime" BO_ 2559573758 1000;
BA_ "GenMsgSendType" BO_ 2559573758 0;
BA_ "GenMsgCycleTime" BO_ 2559573758 10000;
BA_ "GenMsgDelayTime" BO_ 2349530878 20;
BA_ "GenMsgSendType" BO_ 2349530878 0;
BA_ "GenMsgCycleTime" BO_ 2349530878 100;
BA_ "GenMsgDelayTime" BO_ 2566698238 25;
BA_ "GenMsgSendType" BO_ 2566698238 0;
BA_ "GenMsgCycleTime" BO_ 2566698238 1000;
BA_ "GenMsgSendType" BO_ 2566697470 0;
BA_ "GenMsgCycleTime" BO_ 2566697470 100;
BA_ "GenMsgSendType" BO_ 2566692862 0;
BA_ "GenMsgCycleTime" BO_ 2566692862 1000;
BA_ "GenMsgDelayTime" BO_ 2499583742 100;
BA_ "GenMsgSendType" BO_ 2499583742 0;
BA_ "GenMsgCycleTime" BO_ 2499583742 1000;
BA_ "GenMsgDelayTime" BO_ 2499583486 100;
BA_ "GenMsgSendType" BO_ 2499583486 0;
BA_ "GenMsgCycleTime" BO_ 2499583486 1000;
BA_ "TpJ1939VarDlc" BO_ 2566691326 1;
BA_ "GenMsgSendType" BO_ 2499582206 0;
BA_ "GenMsgCycleTime" BO_ 2499582206 500;
BA_ "SPN" SG_ 2566787838 AuxValve2Exit_reasonCode 5802;
BA_ "SigType" SG_ 2566787838 AuxValve2FailSafeMode 4;
BA_ "SPN" SG_ 2566787838 AuxValve2FailSafeMode 1934;
BA_ "SPN" SG_ 2566787838 AuxValve2State 1927;
BA_ "SPN" SG_ 2566787838 AuxValve2RetractPortEstFlow 1926;
BA_ "SPN" SG_ 2566787838 AuxValve2ExtendPortEstFlow 1925;
BA_ "SPN" SG_ 2566787582 AuxValve1Exit_reasonCode 5801;
BA_ "SigType" SG_ 2566787582 AuxValve1FailSafeMode 4;
BA_ "SPN" SG_ 2566787582 AuxValve1FailSafeMode 1922;
BA_ "SPN" SG_ 2566787582 AuxValve1State 1915;
BA_ "SPN" SG_ 2566787582 AuxValve1RetractPortEstFlow 1914;
BA_ "SPN" SG_ 2566787582 AuxValve1ExtendPortEstFlow 1913;
BA_ "SPN" SG_ 2566787326 AuxValve0Exit_reasonCode 5800;
BA_ "SigType" SG_ 2566787326 AuxValve0FailSafeMode 4;
BA_ "SPN" SG_ 2566787326 AuxValve0FailSafeMode 1910;
BA_ "SPN" SG_ 2566787326 AuxValve0State 1903;
BA_ "SPN" SG_ 2566787326 AuxValve0RetractPortEstFlow 1902;
BA_ "SPN" SG_ 2566787326 AuxValve0ExtendPortEstFlow 1901;
BA_ "SigType" SG_ 2566787070 DistanceUnitCmd 4;
BA_ "SPN" SG_ 2566787070 DistanceUnitCmd 2414;
BA_ "SigType" SG_ 2566787070 AreaUnitCmd 4;
BA_ "SPN" SG_ 2566787070 AreaUnitCmd 2415;
BA_ "SigType" SG_ 2566787070 VolumeUnitCmd 4;
BA_ "SPN" SG_ 2566787070 VolumeUnitCmd 2416;
BA_ "SigType" SG_ 2566787070 MassUnitCmd 4;
BA_ "SPN" SG_ 2566787070 MassUnitCmd 2417;
BA_ "SPN" SG_ 2566787070 DateCmd 2412;
BA_ "SigType" SG_ 2566787070 DecimalSymbolCmd 4;
BA_ "SPN" SG_ 2566787070 DecimalSymbolCmd 2411;
BA_ "SigType" SG_ 2566787070 TimeCmd 4;
BA_ "SPN" SG_ 2566787070 TimeCmd 2413;
BA_ "SPN" SG_ 2566787070 LanguageCodeCmd 2410;
BA_ "SPN" SG_ 2566786814 DataDictionaryRow 2427;
BA_ "SPN" SG_ 2566786814 DataDictionaryColumn 2428;
BA_ "SPN" SG_ 2566786814 ImplementType 2425;
BA_ "SPN" SG_ 2566786814 ImplementPos 2426;
BA_ "SigType" SG_ 2566786814 DataFormat_ErrorCondition 4;
BA_ "SPN" SG_ 2566786814 DataFormat_ErrorCondition 2419;
BA_ "SigType" SG_ 2566786814 ProcessDataType 4;
BA_ "SPN" SG_ 2566786814 ProcessDataType 2420;
BA_ "SPN" SG_ 2566786814 ProcessDataModifier 2421;
BA_ "SPN" SG_ 2566786814 RepetitionRateParameter 2418;
BA_ "SPN" SG_ 2566785534 TrctrFcltyRspLmt_RqstSttsRprting 7444;
BA_ "SPN" SG_ 2566785278 TrctrFcltyRqLmt_RqstSttsRporting 7445;
BA_ "SigType" SG_ 2566770686 NumberOfMembers 3;
BA_ "SPN" SG_ 2566770430 NAMEOfWorkingSetMember 2845;
BA_ "SPN" SG_ 2566761470 PGNOfConfigurableMessageDesired 3330;
BA_ "SigType" SG_ 2566761470 MessageSelectionCtrl 1;
BA_ "SPN" SG_ 2566761470 MessageSelectionCtrl 3329;
BA_ "SPN" SG_ 2566754814 AutomaticTransferSwitchStatus 3547;
BA_ "SPN" SG_ 2566754814 UtilityCircuitBreakerStatus 3546;
BA_ "SPN" SG_ 2566754814 GeneratorCircuitBreakerStatus 3545;
BA_ "SigType" SG_ 2566754302 GeneratorTotalPercentKVAr 1;
BA_ "SPN" SG_ 2566754302 GeneratorTotalPercentKVAr 3592;
BA_ "SigType" SG_ 2566754302 GeneratorTotalPercentKVA 1;
BA_ "SPN" SG_ 2566754302 GeneratorTotalPercentKVA 3591;
BA_ "SigType" SG_ 2566754302 GeneratorTotalPercentKW 1;
BA_ "SPN" SG_ 2566754302 GeneratorTotalPercentKW 3590;
BA_ "SigType" SG_ 2566754046 GeneratorTotalKVArHoursImport 1;
BA_ "SPN" SG_ 2566754046 GeneratorTotalKVArHoursImport 3594;
BA_ "SigType" SG_ 2566754046 GeneratorTotalKVArHoursExport 1;
BA_ "SPN" SG_ 2566754046 GeneratorTotalKVArHoursExport 3593;
BA_ "SigType" SG_ 2566753790 UtilityTotalKVArHoursImport 1;
BA_ "SPN" SG_ 2566753790 UtilityTotalKVArHoursImport 3596;
BA_ "SigType" SG_ 2566753790 UtilityTotalKVArHoursExport 1;
BA_ "SPN" SG_ 2566753790 UtilityTotalKVArHoursExport 3595;
BA_ "SigType" SG_ 2566734846 MachineSelectedDirectionCmd 4;
BA_ "SPN" SG_ 2566734846 MachineSelectedDirectionCmd 4312;
BA_ "SPN" SG_ 2566734846 MchnSelectedSpeedExit_reasonCode 5818;
BA_ "SPN" SG_ 2566734846 MchineSelectedSpeedSetpointLimit 4311;
BA_ "SPN" SG_ 2566734846 MachineSelectedSpeedSetpointCmd 4310;
BA_ "SPN" SG_ 2566734590 ISOBUSCmplncCrtfctnMssgeRevision 7446;
BA_ "SPN" SG_ 2566734590 ISOBUSCmplncCrtfctnRfrenceNumber 4330;
BA_ "SPN" SG_ 2566734590 ISOBUSCmplncCrtfctonTypeTaskCtrl 4325;
BA_ "SPN" SG_ 2566734590 ISOBUSCmplncCrtfctnTypTCWrkn4326 4326;
BA_ "SPN" SG_ 2566734590 ISOBUSCmplncCrtfctnTypTCWrkngStM 4327;
BA_ "SPN" SG_ 2566734590 ISOBUSCmplncCrtfctnTypFileServer 4328;
BA_ "SPN" SG_ 2566734590 ISOBUSCmplncCrtfctnTypGPSRceiver 4329;
BA_ "SPN" SG_ 2566734590 ISOBUSCmplncCrtfcationTypeMinECU 4317;
BA_ "SPN" SG_ 2566734590 ISOBUSCmplncCrtfctnTypTECUClass1 4318;
BA_ "SPN" SG_ 2566734590 ISOBUSCmplncCrtfctnTypTECUClass2 4319;
BA_ "SPN" SG_ 2566734590 ISOBUSCmplncCrtfctnTypTECUClass3 4320;
BA_ "SPN" SG_ 2566734590 ISOBUSCmplncCrtfctnTypeClass3ECU 4321;
BA_ "SPN" SG_ 2566734590 ISOBUSCmplncCrtfctnTypVrtlTrmnal 4322;
BA_ "SPN" SG_ 2566734590 ISOBUSCmplncCrtfctnTypVTWrkn4323 4323;
BA_ "SPN" SG_ 2566734590 ISOBUSCmplncCrtfctnTypVTWrkngStM 4324;
BA_ "SPN" SG_ 2566734590 ISOBUSCmplncCrtfctonLaboratoryID 4316;
BA_ "SPN" SG_ 2566734590 ISOBUSCmplncCrtfctLaboratoryType 4315;
BA_ "SPN" SG_ 2566734590 ISOBUSCmplnceCertificateRevision 4314;
BA_ "SPN" SG_ 2566734590 ISOBUSCmplianceCertificationYear 4313;
BA_ "SigType" SG_ 2566718462 ImplementOperatingStateCmd 4;
BA_ "SPN" SG_ 2566718462 ImplementOperatingStateCmd 5139;
BA_ "SPN" SG_ 2566718206 StpAllImplmntOprtnsTrnstonNumber 7443;
BA_ "SigType" SG_ 2566718206 AllImplmntStpOprtngOprtnsSwtchSt 4;
BA_ "SPN" SG_ 2566718206 AllImplmntStpOprtngOprtnsSwtchSt 5140;
BA_ "SigType" SG_ 2566701566 TransOilTransCoolerOutletTemp 1;
BA_ "SPN" SG_ 2566701566 TransOilTransCoolerOutletTemp 5938;
BA_ "SigType" SG_ 2566701566 TransClutch2Press 1;
BA_ "SPN" SG_ 2566701566 TransClutch2Press 5937;
BA_ "SigType" SG_ 2499592446 TransShiftRail6Pos 1;
BA_ "SPN" SG_ 2499592446 TransShiftRail6Pos 5943;
BA_ "SigType" SG_ 2499592446 TransShiftRail5Pos 1;
BA_ "SPN" SG_ 2499592446 TransShiftRail5Pos 5942;
BA_ "SigType" SG_ 2499592446 TransShiftRail4Pos 1;
BA_ "SPN" SG_ 2499592446 TransShiftRail4Pos 5941;
BA_ "SigType" SG_ 2499592446 TransShiftRail3Pos 1;
BA_ "SPN" SG_ 2499592446 TransShiftRail3Pos 4220;
BA_ "SigType" SG_ 2499592446 TransShiftRail2Pos 1;
BA_ "SPN" SG_ 2499592446 TransShiftRail2Pos 4219;
BA_ "SigType" SG_ 2499592446 TransShiftRail1Pos 1;
BA_ "SPN" SG_ 2499592446 TransShiftRail1Pos 4218;
BA_ "SigType" SG_ 2499592190 TransHydPumpActuator2Percent 1;
BA_ "SPN" SG_ 2499592190 TransHydPumpActuator2Percent 6582;
BA_ "SigType" SG_ 2499592190 TransShiftRail6ActuatorStatus 5;
BA_ "SPN" SG_ 2499592190 TransShiftRail6ActuatorStatus 5956;
BA_ "SigType" SG_ 2499592190 TransShiftRail5ActuatorStatus 5;
BA_ "SPN" SG_ 2499592190 TransShiftRail5ActuatorStatus 5955;
BA_ "SigType" SG_ 2499592190 TransShiftRail4ActuatorStatus 5;
BA_ "SPN" SG_ 2499592190 TransShiftRail4ActuatorStatus 5954;
BA_ "SigType" SG_ 2499592190 TransShiftRail3ActuatorStatus 5;
BA_ "SPN" SG_ 2499592190 TransShiftRail3ActuatorStatus 5953;
BA_ "SigType" SG_ 2499592190 TransShiftRail2ActuatorStatus 5;
BA_ "SPN" SG_ 2499592190 TransShiftRail2ActuatorStatus 5952;
BA_ "SigType" SG_ 2499592190 TransShiftRail1ActuatorStatus 5;
BA_ "SPN" SG_ 2499592190 TransShiftRail1ActuatorStatus 5951;
BA_ "SigType" SG_ 2499592190 TrnsClutch2CoolingActuatorStatus 5;
BA_ "SPN" SG_ 2499592190 TrnsClutch2CoolingActuatorStatus 5950;
BA_ "SigType" SG_ 2499592190 TrnsClutch1CoolingActuatorStatus 5;
BA_ "SPN" SG_ 2499592190 TrnsClutch1CoolingActuatorStatus 5949;
BA_ "SigType" SG_ 2499592190 TransShiftActuator2Percent 1;
BA_ "SPN" SG_ 2499592190 TransShiftActuator2Percent 5948;
BA_ "SigType" SG_ 2499592190 TransShiftActuator1Percent 1;
BA_ "SPN" SG_ 2499592190 TransShiftActuator1Percent 5947;
BA_ "SigType" SG_ 2499592190 TransHydPumpActuator1Percent 1;
BA_ "SPN" SG_ 2499592190 TransHydPumpActuator1Percent 5946;
BA_ "SigType" SG_ 2499592190 TransClutch2ActuatorPercent 1;
BA_ "SPN" SG_ 2499592190 TransClutch2ActuatorPercent 5945;
BA_ "SigType" SG_ 2499592190 TransClutch1ActuatorPercent 1;
BA_ "SPN" SG_ 2499592190 TransClutch1ActuatorPercent 5944;
BA_ "SigType" SG_ 2365374206 DlCltchTrnsCrrntPreselectionGear 1;
BA_ "SPN" SG_ 2365374206 DlCltchTrnsCrrntPreselectionGear 5958;
BA_ "SigType" SG_ 2365374206 DlCltchTrnsSlctdPreselectionGear 1;
BA_ "SPN" SG_ 2365374206 DlCltchTrnsSlctdPreselectionGear 5957;
BA_ "SigType" SG_ 2365374206 DualClutchTransInputShaft2Speed 1;
BA_ "SPN" SG_ 2365374206 DualClutchTransInputShaft2Speed 5961;
BA_ "SigType" SG_ 2365374206 DualClutchTransInputShaft1Speed 1;
BA_ "SPN" SG_ 2365374206 DualClutchTransInputShaft1Speed 5960;
BA_ "SigType" SG_ 2566700542 TripDEF 1;
BA_ "SPN" SG_ 2566700542 TripDEF 6563;
BA_ "SigType" SG_ 2566700542 TotalDEFUsed 1;
BA_ "SPN" SG_ 2566700542 TotalDEFUsed 5963;
BA_ "SigType" SG_ 2566700286 TotalDEFUsed 1;
BA_ "SPN" SG_ 2566700286 TotalDEFUsed 5964;
BA_ "SigType" SG_ 2566700030 DEFCtrlModule2PwrSupply2 5;
BA_ "SPN" SG_ 2566700030 DEFCtrlModule2PwrSupply2 7523;
BA_ "SigType" SG_ 2566700030 DEFCtrlModule2PwrSupply1 5;
BA_ "SPN" SG_ 2566700030 DEFCtrlModule2PwrSupply1 7522;
BA_ "SigType" SG_ 2566700030 DEFCtrlModule2RelayCtrl 5;
BA_ "SPN" SG_ 2566700030 DEFCtrlModule2RelayCtrl 7521;
BA_ "SigType" SG_ 2566700030 DEFCtrlModuleCircuitBreaker 4;
BA_ "SPN" SG_ 2566700030 DEFCtrlModuleCircuitBreaker 7417;
BA_ "SigType" SG_ 2566700030 DEFCtrlModule1PwrSupply2 5;
BA_ "SPN" SG_ 2566700030 DEFCtrlModule1PwrSupply2 6309;
BA_ "SigType" SG_ 2566700030 DEFCtrlModule1PwrSupply1 5;
BA_ "SPN" SG_ 2566700030 DEFCtrlModule1PwrSupply1 5966;
BA_ "SigType" SG_ 2566700030 DEFCtrlModule1RelayCtrl 5;
BA_ "SPN" SG_ 2566700030 DEFCtrlModule1RelayCtrl 5965;
BA_ "SigType" SG_ 2566699774 DEFCtrlModule2PwrSupply2 5;
BA_ "SPN" SG_ 2566699774 DEFCtrlModule2PwrSupply2 7534;
BA_ "SigType" SG_ 2566699774 DEFCtrlModule2PwrSupply1 5;
BA_ "SPN" SG_ 2566699774 DEFCtrlModule2PwrSupply1 7533;
BA_ "SigType" SG_ 2566699774 DEFCtrlModule2RelayCtrl 5;
BA_ "SPN" SG_ 2566699774 DEFCtrlModule2RelayCtrl 7532;
BA_ "SigType" SG_ 2566699774 DEFCtrlModule1PwrSupply2 5;
BA_ "SPN" SG_ 2566699774 DEFCtrlModule1PwrSupply2 6310;
BA_ "SigType" SG_ 2566699774 DEFCtrlModule1PwrSupply1 5;
BA_ "SPN" SG_ 2566699774 DEFCtrlModule1PwrSupply1 5968;
BA_ "SigType" SG_ 2566699774 DEFCtrlModule1RelayCtrl 5;
BA_ "SPN" SG_ 2566699774 DEFCtrlModule1RelayCtrl 5967;
BA_ "SigType" SG_ 2566699518 SCRSysTimeSinceLastSysCleanEvent 1;
BA_ "SPN" SG_ 2566699518 SCRSysTimeSinceLastSysCleanEvent 6941;
BA_ "SigType" SG_ 2566699518 DPFTimeToNextActiveRegen 1;
BA_ "SPN" SG_ 2566699518 DPFTimeToNextActiveRegen 5978;
BA_ "SigType" SG_ 2566699262 SCRSysTimeSinceLastSysCleanEvent 1;
BA_ "SPN" SG_ 2566699262 SCRSysTimeSinceLastSysCleanEvent 6948;
BA_ "SigType" SG_ 2566699262 DPFTimeToNextActiveRegen 1;
BA_ "SPN" SG_ 2566699262 DPFTimeToNextActiveRegen 5979;
BA_ "SigType" SG_ 2566698750 SLICrnkngPrdctdMinBatteryVoltage 1;
BA_ "SPN" SG_ 2566698750 SLICrnkngPrdctdMinBatteryVoltage 7497;
BA_ "SigType" SG_ 2566698750 SLIBatteryPackHealth 1;
BA_ "SPN" SG_ 2566698750 SLIBatteryPackHealth 5983;
BA_ "SigType" SG_ 2566698750 SLIBatteryPackCapacity 1;
BA_ "SPN" SG_ 2566698750 SLIBatteryPackCapacity 5982;
BA_ "SigType" SG_ 2566698750 SLIBatteryPackStateOfCharge 1;
BA_ "SPN" SG_ 2566698750 SLIBatteryPackStateOfCharge 5981;
BA_ "SigType" SG_ 2566698494 FusedOutput29 4;
BA_ "SPN" SG_ 2566698494 FusedOutput29 6047;
BA_ "SigType" SG_ 2566698494 FusedOutput30 4;
BA_ "SPN" SG_ 2566698494 FusedOutput30 6046;
BA_ "SigType" SG_ 2566698494 FusedOutput31 4;
BA_ "SPN" SG_ 2566698494 FusedOutput31 6045;
BA_ "SigType" SG_ 2566698494 FusedOutput32 4;
BA_ "SPN" SG_ 2566698494 FusedOutput32 6044;
BA_ "SigType" SG_ 2566698494 FusedOutput25 4;
BA_ "SPN" SG_ 2566698494 FusedOutput25 6043;
BA_ "SigType" SG_ 2566698494 FusedOutput26 4;
BA_ "SPN" SG_ 2566698494 FusedOutput26 6042;
BA_ "SigType" SG_ 2566698494 FusedOutput27 4;
BA_ "SPN" SG_ 2566698494 FusedOutput27 6041;
BA_ "SigType" SG_ 2566698494 FusedOutput28 4;
BA_ "SPN" SG_ 2566698494 FusedOutput28 6040;
BA_ "SigType" SG_ 2566698494 FusedOutput21 4;
BA_ "SPN" SG_ 2566698494 FusedOutput21 6039;
BA_ "SigType" SG_ 2566698494 FusedOutput22 4;
BA_ "SPN" SG_ 2566698494 FusedOutput22 6038;
BA_ "SigType" SG_ 2566698494 FusedOutput23 4;
BA_ "SPN" SG_ 2566698494 FusedOutput23 6037;
BA_ "SigType" SG_ 2566698494 FusedOutput24 4;
BA_ "SPN" SG_ 2566698494 FusedOutput24 6036;
BA_ "SigType" SG_ 2566698494 FusedOutput17 4;
BA_ "SPN" SG_ 2566698494 FusedOutput17 6035;
BA_ "SigType" SG_ 2566698494 FusedOutput18 4;
BA_ "SPN" SG_ 2566698494 FusedOutput18 6034;
BA_ "SigType" SG_ 2566698494 FusedOutput19 4;
BA_ "SPN" SG_ 2566698494 FusedOutput19 6033;
BA_ "SigType" SG_ 2566698494 FusedOutput20 4;
BA_ "SPN" SG_ 2566698494 FusedOutput20 6032;
BA_ "SigType" SG_ 2566698494 FusedOutput13 4;
BA_ "SPN" SG_ 2566698494 FusedOutput13 6031;
BA_ "SigType" SG_ 2566698494 FusedOutput14 4;
BA_ "SPN" SG_ 2566698494 FusedOutput14 6030;
BA_ "SigType" SG_ 2566698494 FusedOutput15 4;
BA_ "SPN" SG_ 2566698494 FusedOutput15 6029;
BA_ "SigType" SG_ 2566698494 FusedOutput16 4;
BA_ "SPN" SG_ 2566698494 FusedOutput16 6028;
BA_ "SigType" SG_ 2566698494 FusedOutput9 4;
BA_ "SPN" SG_ 2566698494 FusedOutput9 6027;
BA_ "SigType" SG_ 2566698494 FusedOutput10 4;
BA_ "SPN" SG_ 2566698494 FusedOutput10 6026;
BA_ "SigType" SG_ 2566698494 FusedOutput11 4;
BA_ "SPN" SG_ 2566698494 FusedOutput11 6025;
BA_ "SigType" SG_ 2566698494 FusedOutput12 4;
BA_ "SPN" SG_ 2566698494 FusedOutput12 6024;
BA_ "SigType" SG_ 2566698494 FusedOutput5 4;
BA_ "SPN" SG_ 2566698494 FusedOutput5 6023;
BA_ "SigType" SG_ 2566698494 FusedOutput6 4;
BA_ "SPN" SG_ 2566698494 FusedOutput6 6022;
BA_ "SigType" SG_ 2566698494 FusedOutput7 4;
BA_ "SPN" SG_ 2566698494 FusedOutput7 6021;
BA_ "SigType" SG_ 2566698494 FusedOutput8 4;
BA_ "SPN" SG_ 2566698494 FusedOutput8 6020;
BA_ "SigType" SG_ 2566698494 FusedOutput1 4;
BA_ "SPN" SG_ 2566698494 FusedOutput1 6019;
BA_ "SigType" SG_ 2566698494 FusedOutput2 4;
BA_ "SPN" SG_ 2566698494 FusedOutput2 6018;
BA_ "SigType" SG_ 2566698494 FusedOutput3 4;
BA_ "SPN" SG_ 2566698494 FusedOutput3 6017;
BA_ "SigType" SG_ 2566698494 FusedOutput4 4;
BA_ "SPN" SG_ 2566698494 FusedOutput4 6016;
BA_ "SigType" SG_ 2559115006 WirelessSignalStrength2 1;
BA_ "SPN" SG_ 2559115006 WirelessSignalStrength2 5757;
BA_ "SPN" SG_ 2559115006 TransmitterID2 5756;
BA_ "SigType" SG_ 2559115006 RadioBeaconDirection 5;
BA_ "SPN" SG_ 2559115006 RadioBeaconDirection 5755;
BA_ "SigType" SG_ 2559115006 UnqBeaconMessageIdentifierNumber 1;
BA_ "SPN" SG_ 2559115006 UnqBeaconMessageIdentifierNumber 5754;
BA_ "SigType" SG_ 2566707454 SnsrAnalysisReqFreq4 1;
BA_ "SPN" SG_ 2566707454 SnsrAnalysisReqFreq4 5647;
BA_ "SigType" SG_ 2566707454 SnsrAnalysisReqFreq3 1;
BA_ "SPN" SG_ 2566707454 SnsrAnalysisReqFreq3 5646;
BA_ "SigType" SG_ 2566707454 SnsrAnalysisReqFreq2 1;
BA_ "SPN" SG_ 2566707454 SnsrAnalysisReqFreq2 5645;
BA_ "SigType" SG_ 2566707454 SnsrAnalysisReqFreq1 1;
BA_ "SPN" SG_ 2566707454 SnsrAnalysisReqFreq1 5644;
BA_ "SigType" SG_ 2566707198 SnsrFreq2SootSignal 1;
BA_ "SPN" SG_ 2566707198 SnsrFreq2SootSignal 5651;
BA_ "SigType" SG_ 2566707198 SnsrAnalysisFreq2 1;
BA_ "SPN" SG_ 2566707198 SnsrAnalysisFreq2 5650;
BA_ "SigType" SG_ 2566707198 SnsrFreq1SootSignal 1;
BA_ "SPN" SG_ 2566707198 SnsrFreq1SootSignal 5649;
BA_ "SigType" SG_ 2566707198 SnsrAnalysisFreq1 1;
BA_ "SPN" SG_ 2566707198 SnsrAnalysisFreq1 5648;
BA_ "SigType" SG_ 2566706942 SnsrFreq4SootSignal 1;
BA_ "SPN" SG_ 2566706942 SnsrFreq4SootSignal 5655;
BA_ "SigType" SG_ 2566706942 SnsrAnalysisFreq4 1;
BA_ "SPN" SG_ 2566706942 SnsrAnalysisFreq4 5654;
BA_ "SigType" SG_ 2566706942 SnsrFreq3SootSignal 1;
BA_ "SPN" SG_ 2566706942 SnsrFreq3SootSignal 5653;
BA_ "SigType" SG_ 2566706942 SnsrAnalysisFreq3 1;
BA_ "SPN" SG_ 2566706942 SnsrAnalysisFreq3 5652;
BA_ "SigType" SG_ 2559770366 HydrocarbonDoserPurgingRequired 5;
BA_ "SPN" SG_ 2559770366 HydrocarbonDoserPurgingRequired 5509;
BA_ "SPN" SG_ 2559770366 DiagnosticStatusOfHCDoser 5508;
BA_ "SigType" SG_ 2559770366 HCDoserInjectingStatus 5;
BA_ "SPN" SG_ 2559770366 HCDoserInjectingStatus 5507;
BA_ "SPN" SG_ 2559770366 HCDoserStatus 5506;
BA_ "SigType" SG_ 2559770366 RequestedFuelMassRate 1;
BA_ "SPN" SG_ 2559770366 RequestedFuelMassRate 5505;
BA_ "SigType" SG_ 2559704830 LubricationTimingCycleCmd 5;
BA_ "SPN" SG_ 2559704830 LubricationTimingCycleCmd 5514;
BA_ "SigType" SG_ 2559704830 LubricationPumpEnableCmd 5;
BA_ "SPN" SG_ 2559704830 LubricationPumpEnableCmd 5513;
BA_ "SPN" SG_ 2559704830 LubricationOperationModeSetCmd 5512;
BA_ "SPN" SG_ 2559704830 LubricationCycleSetCmd 5511;
BA_ "SigType" SG_ 2559704830 LubricationCycleModeLockCmd 5;
BA_ "SPN" SG_ 2559704830 LubricationCycleModeLockCmd 5510;
BA_ "SigType" SG_ 2559639294 SupplementalFanPowerHold 5;
BA_ "SPN" SG_ 2559639294 SupplementalFanPowerHold 5555;
BA_ "SigType" SG_ 2559639294 SupplementalFanSpeedCmd 1;
BA_ "SPN" SG_ 2559639294 SupplementalFanSpeedCmd 5554;
BA_ "SigType" SG_ 2559639294 SupplementalFanDirectionCmd 5;
BA_ "SPN" SG_ 2559639294 SupplementalFanDirectionCmd 5553;
BA_ "SigType" SG_ 2559639294 SupplementalFanEnableCmd 5;
BA_ "SPN" SG_ 2559639294 SupplementalFanEnableCmd 5552;
BA_ "SigType" SG_ 2559573758 ClntLvlEngPrtctnShtdwnOvrrideCmd 5;
BA_ "SPN" SG_ 2559573758 ClntLvlEngPrtctnShtdwnOvrrideCmd 5565;
BA_ "SigType" SG_ 2349530878 CruiseCtrlPauseCmd 5;
BA_ "SPN" SG_ 2349530878 CruiseCtrlPauseCmd 5605;
BA_ "SigType" SG_ 2349530878 CruiseCtrlResumeCmd 5;
BA_ "SPN" SG_ 2349530878 CruiseCtrlResumeCmd 5604;
BA_ "SigType" SG_ 2349530878 CruiseCtrlDisableCmd 5;
BA_ "SPN" SG_ 2349530878 CruiseCtrlDisableCmd 5603;
BA_ "SigType" SG_ 2566698238 SwitchedOutput29 5;
BA_ "SPN" SG_ 2566698238 SwitchedOutput29 6079;
BA_ "SigType" SG_ 2566698238 SwitchedOutput30 5;
BA_ "SPN" SG_ 2566698238 SwitchedOutput30 6078;
BA_ "SigType" SG_ 2566698238 SwitchedOutput31 5;
BA_ "SPN" SG_ 2566698238 SwitchedOutput31 6077;
BA_ "SigType" SG_ 2566698238 SwitchedOutput32 5;
BA_ "SPN" SG_ 2566698238 SwitchedOutput32 6076;
BA_ "SigType" SG_ 2566698238 SwitchedOutput25 5;
BA_ "SPN" SG_ 2566698238 SwitchedOutput25 6075;
BA_ "SigType" SG_ 2566698238 SwitchedOutput26 5;
BA_ "SPN" SG_ 2566698238 SwitchedOutput26 6074;
BA_ "SigType" SG_ 2566698238 SwitchedOutput27 5;
BA_ "SPN" SG_ 2566698238 SwitchedOutput27 6073;
BA_ "SigType" SG_ 2566698238 SwitchedOutput28 5;
BA_ "SPN" SG_ 2566698238 SwitchedOutput28 6072;
BA_ "SigType" SG_ 2566698238 SwitchedOutput21 5;
BA_ "SPN" SG_ 2566698238 SwitchedOutput21 6071;
BA_ "SigType" SG_ 2566698238 SwitchedOutput22 5;
BA_ "SPN" SG_ 2566698238 SwitchedOutput22 6070;
BA_ "SigType" SG_ 2566698238 SwitchedOutput23 5;
BA_ "SPN" SG_ 2566698238 SwitchedOutput23 6069;
BA_ "SigType" SG_ 2566698238 SwitchedOutput24 5;
BA_ "SPN" SG_ 2566698238 SwitchedOutput24 6068;
BA_ "SigType" SG_ 2566698238 SwitchedOutput17 5;
BA_ "SPN" SG_ 2566698238 SwitchedOutput17 6067;
BA_ "SigType" SG_ 2566698238 SwitchedOutput18 5;
BA_ "SPN" SG_ 2566698238 SwitchedOutput18 6066;
BA_ "SigType" SG_ 2566698238 SwitchedOutput19 5;
BA_ "SPN" SG_ 2566698238 SwitchedOutput19 6065;
BA_ "SigType" SG_ 2566698238 SwitchedOutput20 5;
BA_ "SPN" SG_ 2566698238 SwitchedOutput20 6064;
BA_ "SigType" SG_ 2566698238 SwitchedOutput13 5;
BA_ "SPN" SG_ 2566698238 SwitchedOutput13 6063;
BA_ "SigType" SG_ 2566698238 SwitchedOutput14 5;
BA_ "SPN" SG_ 2566698238 SwitchedOutput14 6062;
BA_ "SigType" SG_ 2566698238 SwitchedOutput15 5;
BA_ "SPN" SG_ 2566698238 SwitchedOutput15 6061;
BA_ "SigType" SG_ 2566698238 SwitchedOutput16 5;
BA_ "SPN" SG_ 2566698238 SwitchedOutput16 6060;
BA_ "SigType" SG_ 2566698238 SwitchedOutput9 5;
BA_ "SPN" SG_ 2566698238 SwitchedOutput9 6059;
BA_ "SigType" SG_ 2566698238 SwitchedOutput10 5;
BA_ "SPN" SG_ 2566698238 SwitchedOutput10 6058;
BA_ "SigType" SG_ 2566698238 SwitchedOutput11 5;
BA_ "SPN" SG_ 2566698238 SwitchedOutput11 6057;
BA_ "SigType" SG_ 2566698238 SwitchedOutput12 5;
BA_ "SPN" SG_ 2566698238 SwitchedOutput12 6056;
BA_ "SigType" SG_ 2566698238 SwitchedOutput5 5;
BA_ "SPN" SG_ 2566698238 SwitchedOutput5 6055;
BA_ "SigType" SG_ 2566698238 SwitchedOutput6 5;
BA_ "SPN" SG_ 2566698238 SwitchedOutput6 6054;
BA_ "SigType" SG_ 2566698238 SwitchedOutput7 5;
BA_ "SPN" SG_ 2566698238 SwitchedOutput7 6053;
BA_ "SigType" SG_ 2566698238 SwitchedOutput8 5;
BA_ "SPN" SG_ 2566698238 SwitchedOutput8 6052;
BA_ "SigType" SG_ 2566698238 SwitchedOutput1 5;
BA_ "SPN" SG_ 2566698238 SwitchedOutput1 6051;
BA_ "SigType" SG_ 2566698238 SwitchedOutput2 5;
BA_ "SPN" SG_ 2566698238 SwitchedOutput2 6050;
BA_ "SigType" SG_ 2566698238 SwitchedOutput3 5;
BA_ "SPN" SG_ 2566698238 SwitchedOutput3 6049;
BA_ "SigType" SG_ 2566698238 SwitchedOutput4 5;
BA_ "SPN" SG_ 2566698238 SwitchedOutput4 6048;
BA_ "SigType" SG_ 2566697982 FusedOutput32Current 1;
BA_ "SPN" SG_ 2566697982 FusedOutput32Current 6111;
BA_ "SigType" SG_ 2566697982 FusedOutput31Current 1;
BA_ "SPN" SG_ 2566697982 FusedOutput31Current 6110;
BA_ "SigType" SG_ 2566697982 FusedOutput30Current 1;
BA_ "SPN" SG_ 2566697982 FusedOutput30Current 6109;
BA_ "SigType" SG_ 2566697982 FusedOutput29Current 1;
BA_ "SPN" SG_ 2566697982 FusedOutput29Current 6108;
BA_ "SigType" SG_ 2566697982 FusedOutput28Current 1;
BA_ "SPN" SG_ 2566697982 FusedOutput28Current 6107;
BA_ "SigType" SG_ 2566697982 FusedOutput27Current 1;
BA_ "SPN" SG_ 2566697982 FusedOutput27Current 6106;
BA_ "SigType" SG_ 2566697982 FusedOutput26Current 1;
BA_ "SPN" SG_ 2566697982 FusedOutput26Current 6105;
BA_ "SigType" SG_ 2566697982 FusedOutput25Current 1;
BA_ "SPN" SG_ 2566697982 FusedOutput25Current 6104;
BA_ "SigType" SG_ 2566697982 FusedOutput24Current 1;
BA_ "SPN" SG_ 2566697982 FusedOutput24Current 6103;
BA_ "SigType" SG_ 2566697982 FusedOutput23Current 1;
BA_ "SPN" SG_ 2566697982 FusedOutput23Current 6102;
BA_ "SigType" SG_ 2566697982 FusedOutput22Current 1;
BA_ "SPN" SG_ 2566697982 FusedOutput22Current 6101;
BA_ "SigType" SG_ 2566697982 FusedOutput21Current 1;
BA_ "SPN" SG_ 2566697982 FusedOutput21Current 6100;
BA_ "SigType" SG_ 2566697982 FusedOutput20Current 1;
BA_ "SPN" SG_ 2566697982 FusedOutput20Current 6099;
BA_ "SigType" SG_ 2566697982 FusedOutput19Current 1;
BA_ "SPN" SG_ 2566697982 FusedOutput19Current 6098;
BA_ "SigType" SG_ 2566697982 FusedOutput18Current 1;
BA_ "SPN" SG_ 2566697982 FusedOutput18Current 6097;
BA_ "SigType" SG_ 2566697982 FusedOutput17Current 1;
BA_ "SPN" SG_ 2566697982 FusedOutput17Current 6096;
BA_ "SigType" SG_ 2566697982 FusedOutput16Current 1;
BA_ "SPN" SG_ 2566697982 FusedOutput16Current 6095;
BA_ "SigType" SG_ 2566697982 FusedOutput15Current 1;
BA_ "SPN" SG_ 2566697982 FusedOutput15Current 6094;
BA_ "SigType" SG_ 2566697982 FusedOutput14Current 1;
BA_ "SPN" SG_ 2566697982 FusedOutput14Current 6093;
BA_ "SigType" SG_ 2566697982 FusedOutput13Current 1;
BA_ "SPN" SG_ 2566697982 FusedOutput13Current 6092;
BA_ "SigType" SG_ 2566697982 FusedOutput12Current 1;
BA_ "SPN" SG_ 2566697982 FusedOutput12Current 6091;
BA_ "SigType" SG_ 2566697982 FusedOutput11Current 1;
BA_ "SPN" SG_ 2566697982 FusedOutput11Current 6090;
BA_ "SigType" SG_ 2566697982 FusedOutput10Current 1;
BA_ "SPN" SG_ 2566697982 FusedOutput10Current 6089;
BA_ "SigType" SG_ 2566697982 FusedOutput9Current 1;
BA_ "SPN" SG_ 2566697982 FusedOutput9Current 6088;
BA_ "SigType" SG_ 2566697982 FusedOutput8Current 1;
BA_ "SPN" SG_ 2566697982 FusedOutput8Current 6087;
BA_ "SigType" SG_ 2566697982 FusedOutput7Current 1;
BA_ "SPN" SG_ 2566697982 FusedOutput7Current 6086;
BA_ "SigType" SG_ 2566697982 FusedOutput6Current 1;
BA_ "SPN" SG_ 2566697982 FusedOutput6Current 6085;
BA_ "SigType" SG_ 2566697982 FusedOutput5Current 1;
BA_ "SPN" SG_ 2566697982 FusedOutput5Current 6084;
BA_ "SigType" SG_ 2566697982 FusedOutput4Current 1;
BA_ "SPN" SG_ 2566697982 FusedOutput4Current 6083;
BA_ "SigType" SG_ 2566697982 FusedOutput3Current 1;
BA_ "SPN" SG_ 2566697982 FusedOutput3Current 6082;
BA_ "SigType" SG_ 2566697982 FusedOutput2Current 1;
BA_ "SPN" SG_ 2566697982 FusedOutput2Current 6081;
BA_ "SigType" SG_ 2566697982 FusedOutput1Current 1;
BA_ "SPN" SG_ 2566697982 FusedOutput1Current 6080;
BA_ "SigType" SG_ 2566697726 SwitchedOutput32Current 1;
BA_ "SPN" SG_ 2566697726 SwitchedOutput32Current 6143;
BA_ "SigType" SG_ 2566697726 SwitchedOutput31Current 1;
BA_ "SPN" SG_ 2566697726 SwitchedOutput31Current 6142;
BA_ "SigType" SG_ 2566697726 SwitchedOutput30Current 1;
BA_ "SPN" SG_ 2566697726 SwitchedOutput30Current 6141;
BA_ "SigType" SG_ 2566697726 SwitchedOutput29Current 1;
BA_ "SPN" SG_ 2566697726 SwitchedOutput29Current 6140;
BA_ "SigType" SG_ 2566697726 SwitchedOutput28Current 1;
BA_ "SPN" SG_ 2566697726 SwitchedOutput28Current 6139;
BA_ "SigType" SG_ 2566697726 SwitchedOutput27Current 1;
BA_ "SPN" SG_ 2566697726 SwitchedOutput27Current 6138;
BA_ "SigType" SG_ 2566697726 SwitchedOutput26Current 1;
BA_ "SPN" SG_ 2566697726 SwitchedOutput26Current 6137;
BA_ "SigType" SG_ 2566697726 SwitchedOutput25Current 1;
BA_ "SPN" SG_ 2566697726 SwitchedOutput25Current 6136;
BA_ "SigType" SG_ 2566697726 SwitchedOutput24Current 1;
BA_ "SPN" SG_ 2566697726 SwitchedOutput24Current 6135;
BA_ "SigType" SG_ 2566697726 SwitchedOutput23Current 1;
BA_ "SPN" SG_ 2566697726 SwitchedOutput23Current 6134;
BA_ "SigType" SG_ 2566697726 SwitchedOutput22Current 1;
BA_ "SPN" SG_ 2566697726 SwitchedOutput22Current 6133;
BA_ "SigType" SG_ 2566697726 SwitchedOutput21Current 1;
BA_ "SPN" SG_ 2566697726 SwitchedOutput21Current 6132;
BA_ "SigType" SG_ 2566697726 SwitchedOutput20Current 1;
BA_ "SPN" SG_ 2566697726 SwitchedOutput20Current 6131;
BA_ "SigType" SG_ 2566697726 SwitchedOutput19Current 1;
BA_ "SPN" SG_ 2566697726 SwitchedOutput19Current 6130;
BA_ "SigType" SG_ 2566697726 SwitchedOutput18Current 1;
BA_ "SPN" SG_ 2566697726 SwitchedOutput18Current 6129;
BA_ "SigType" SG_ 2566697726 SwitchedOutput17Current 1;
BA_ "SPN" SG_ 2566697726 SwitchedOutput17Current 6128;
BA_ "SigType" SG_ 2566697726 SwitchedOutput16Current 1;
BA_ "SPN" SG_ 2566697726 SwitchedOutput16Current 6127;
BA_ "SigType" SG_ 2566697726 SwitchedOutput15Current 1;
BA_ "SPN" SG_ 2566697726 SwitchedOutput15Current 6126;
BA_ "SigType" SG_ 2566697726 SwitchedOutput14Current 1;
BA_ "SPN" SG_ 2566697726 SwitchedOutput14Current 6125;
BA_ "SigType" SG_ 2566697726 SwitchedOutput13Current 1;
BA_ "SPN" SG_ 2566697726 SwitchedOutput13Current 6124;
BA_ "SigType" SG_ 2566697726 SwitchedOutput12Current 1;
BA_ "SPN" SG_ 2566697726 SwitchedOutput12Current 6123;
BA_ "SigType" SG_ 2566697726 SwitchedOutput11Current 1;
BA_ "SPN" SG_ 2566697726 SwitchedOutput11Current 6122;
BA_ "SigType" SG_ 2566697726 SwitchedOutput10Current 1;
BA_ "SPN" SG_ 2566697726 SwitchedOutput10Current 6121;
BA_ "SigType" SG_ 2566697726 SwitchedOutput9Current 1;
BA_ "SPN" SG_ 2566697726 SwitchedOutput9Current 6120;
BA_ "SigType" SG_ 2566697726 SwitchedOutput8Current 1;
BA_ "SPN" SG_ 2566697726 SwitchedOutput8Current 6119;
BA_ "SigType" SG_ 2566697726 SwitchedOutput7Current 1;
BA_ "SPN" SG_ 2566697726 SwitchedOutput7Current 6118;
BA_ "SigType" SG_ 2566697726 SwitchedOutput6Current 1;
BA_ "SPN" SG_ 2566697726 SwitchedOutput6Current 6117;
BA_ "SigType" SG_ 2566697726 SwitchedOutput5Current 1;
BA_ "SPN" SG_ 2566697726 SwitchedOutput5Current 6116;
BA_ "SigType" SG_ 2566697726 SwitchedOutput4Current 1;
BA_ "SPN" SG_ 2566697726 SwitchedOutput4Current 6115;
BA_ "SigType" SG_ 2566697726 SwitchedOutput3Current 1;
BA_ "SPN" SG_ 2566697726 SwitchedOutput3Current 6114;
BA_ "SigType" SG_ 2566697726 SwitchedOutput2Current 1;
BA_ "SPN" SG_ 2566697726 SwitchedOutput2Current 6113;
BA_ "SigType" SG_ 2566697726 SwitchedOutput1Current 1;
BA_ "SPN" SG_ 2566697726 SwitchedOutput1Current 6112;
BA_ "SPN" SG_ 2566697470 EngIgntCtrlModule2State 6217;
BA_ "SPN" SG_ 2566697470 EngIgntCtrlModule1State 6216;
BA_ "SigType" SG_ 2566697470 EngIgntCtrlModule2Temp 1;
BA_ "SPN" SG_ 2566697470 EngIgntCtrlModule2Temp 6215;
BA_ "SigType" SG_ 2566697470 EngIgntCtrlModule1Temp 1;
BA_ "SPN" SG_ 2566697470 EngIgntCtrlModule1Temp 6214;
BA_ "SigType" SG_ 2633806078 EngIgntCtrlModule2TimeRemaining 1;
BA_ "SPN" SG_ 2633806078 EngIgntCtrlModule2TimeRemaining 6221;
BA_ "SigType" SG_ 2633806078 EngIgntCtrlModule1TimeRemaining 1;
BA_ "SPN" SG_ 2633806078 EngIgntCtrlModule1TimeRemaining 6220;
BA_ "SigType" SG_ 2633805822 EngSparkPlug4MinVoltage 1;
BA_ "SPN" SG_ 2633805822 EngSparkPlug4MinVoltage 6225;
BA_ "SigType" SG_ 2633805822 EngSparkPlug3MinVoltage 1;
BA_ "SPN" SG_ 2633805822 EngSparkPlug3MinVoltage 6224;
BA_ "SigType" SG_ 2633805822 EngSparkPlug2MinVoltage 1;
BA_ "SPN" SG_ 2633805822 EngSparkPlug2MinVoltage 6223;
BA_ "SigType" SG_ 2633805822 EngSparkPlug1MinVoltage 1;
BA_ "SPN" SG_ 2633805822 EngSparkPlug1MinVoltage 6222;
BA_ "SigType" SG_ 2633805566 EngSparkPlug8MinVoltage 1;
BA_ "SPN" SG_ 2633805566 EngSparkPlug8MinVoltage 6229;
BA_ "SigType" SG_ 2633805566 EngSparkPlug7MinVoltage 1;
BA_ "SPN" SG_ 2633805566 EngSparkPlug7MinVoltage 6228;
BA_ "SigType" SG_ 2633805566 EngSparkPlug6MinVoltage 1;
BA_ "SPN" SG_ 2633805566 EngSparkPlug6MinVoltage 6227;
BA_ "SigType" SG_ 2633805566 EngSparkPlug5MinVoltage 1;
BA_ "SPN" SG_ 2633805566 EngSparkPlug5MinVoltage 6226;
BA_ "SigType" SG_ 2633805310 EngSparkPlug12MinVoltage 1;
BA_ "SPN" SG_ 2633805310 EngSparkPlug12MinVoltage 6233;
BA_ "SigType" SG_ 2633805310 EngSparkPlug11MinVoltage 1;
BA_ "SPN" SG_ 2633805310 EngSparkPlug11MinVoltage 6232;
BA_ "SigType" SG_ 2633805310 EngSparkPlug10MinVoltage 1;
BA_ "SPN" SG_ 2633805310 EngSparkPlug10MinVoltage 6231;
BA_ "SigType" SG_ 2633805310 EngSparkPlug9MinVoltage 1;
BA_ "SPN" SG_ 2633805310 EngSparkPlug9MinVoltage 6230;
BA_ "SigType" SG_ 2633805054 EngSparkPlug16MinVoltage 1;
BA_ "SPN" SG_ 2633805054 EngSparkPlug16MinVoltage 6237;
BA_ "SigType" SG_ 2633805054 EngSparkPlug15MinVoltage 1;
BA_ "SPN" SG_ 2633805054 EngSparkPlug15MinVoltage 6236;
BA_ "SigType" SG_ 2633805054 EngSparkPlug14MinVoltage 1;
BA_ "SPN" SG_ 2633805054 EngSparkPlug14MinVoltage 6235;
BA_ "SigType" SG_ 2633805054 EngSparkPlug13MinVoltage 1;
BA_ "SPN" SG_ 2633805054 EngSparkPlug13MinVoltage 6234;
BA_ "SigType" SG_ 2633804798 EngSparkPlug20MinVoltage 1;
BA_ "SPN" SG_ 2633804798 EngSparkPlug20MinVoltage 6241;
BA_ "SigType" SG_ 2633804798 EngSparkPlug19MinVoltage 1;
BA_ "SPN" SG_ 2633804798 EngSparkPlug19MinVoltage 6240;
BA_ "SigType" SG_ 2633804798 EngSparkPlug18MinVoltage 1;
BA_ "SPN" SG_ 2633804798 EngSparkPlug18MinVoltage 6239;
BA_ "SigType" SG_ 2633804798 EngSparkPlug17MinVoltage 1;
BA_ "SPN" SG_ 2633804798 EngSparkPlug17MinVoltage 6238;
BA_ "SigType" SG_ 2633804542 EngSparkPlug24MinVoltage 1;
BA_ "SPN" SG_ 2633804542 EngSparkPlug24MinVoltage 6245;
BA_ "SigType" SG_ 2633804542 EngSparkPlug23MinVoltage 1;
BA_ "SPN" SG_ 2633804542 EngSparkPlug23MinVoltage 6244;
BA_ "SigType" SG_ 2633804542 EngSparkPlug22MinVoltage 1;
BA_ "SPN" SG_ 2633804542 EngSparkPlug22MinVoltage 6243;
BA_ "SigType" SG_ 2633804542 EngSparkPlug21MinVoltage 1;
BA_ "SPN" SG_ 2633804542 EngSparkPlug21MinVoltage 6242;
BA_ "SigType" SG_ 2633804286 EngSparkPlug4MaxVoltage 1;
BA_ "SPN" SG_ 2633804286 EngSparkPlug4MaxVoltage 6249;
BA_ "SigType" SG_ 2633804286 EngSparkPlug3MaxVoltage 1;
BA_ "SPN" SG_ 2633804286 EngSparkPlug3MaxVoltage 6248;
BA_ "SigType" SG_ 2633804286 EngSparkPlug2MaxVoltage 1;
BA_ "SPN" SG_ 2633804286 EngSparkPlug2MaxVoltage 6247;
BA_ "SigType" SG_ 2633804286 EngSparkPlug1MaxVoltage 1;
BA_ "SPN" SG_ 2633804286 EngSparkPlug1MaxVoltage 6246;
BA_ "SigType" SG_ 2633804030 EngSparkPlug8MaxVoltage 1;
BA_ "SPN" SG_ 2633804030 EngSparkPlug8MaxVoltage 6253;
BA_ "SigType" SG_ 2633804030 EngSparkPlug7MaxVoltage 1;
BA_ "SPN" SG_ 2633804030 EngSparkPlug7MaxVoltage 6252;
BA_ "SigType" SG_ 2633804030 EngSparkPlug6MaxVoltage 1;
BA_ "SPN" SG_ 2633804030 EngSparkPlug6MaxVoltage 6251;
BA_ "SigType" SG_ 2633804030 EngSparkPlug5MaxVoltage 1;
BA_ "SPN" SG_ 2633804030 EngSparkPlug5MaxVoltage 6250;
BA_ "SigType" SG_ 2633803774 EngSparkPlug12MaxVoltage 1;
BA_ "SPN" SG_ 2633803774 EngSparkPlug12MaxVoltage 6257;
BA_ "SigType" SG_ 2633803774 EngSparkPlug11MaxVoltage 1;
BA_ "SPN" SG_ 2633803774 EngSparkPlug11MaxVoltage 6256;
BA_ "SigType" SG_ 2633803774 EngSparkPlug10MaxVoltage 1;
BA_ "SPN" SG_ 2633803774 EngSparkPlug10MaxVoltage 6255;
BA_ "SigType" SG_ 2633803774 EngSparkPlug9MaxVoltage 1;
BA_ "SPN" SG_ 2633803774 EngSparkPlug9MaxVoltage 6254;
BA_ "SigType" SG_ 2633803518 EngSparkPlug16MaxVoltage 1;
BA_ "SPN" SG_ 2633803518 EngSparkPlug16MaxVoltage 6261;
BA_ "SigType" SG_ 2633803518 EngSparkPlug15MaxVoltage 1;
BA_ "SPN" SG_ 2633803518 EngSparkPlug15MaxVoltage 6260;
BA_ "SigType" SG_ 2633803518 EngSparkPlug14MaxVoltage 1;
BA_ "SPN" SG_ 2633803518 EngSparkPlug14MaxVoltage 6259;
BA_ "SigType" SG_ 2633803518 EngSparkPlug13MaxVoltage 1;
BA_ "SPN" SG_ 2633803518 EngSparkPlug13MaxVoltage 6258;
BA_ "SigType" SG_ 2633803262 EngSparkPlug20MaxVoltage 1;
BA_ "SPN" SG_ 2633803262 EngSparkPlug20MaxVoltage 6265;
BA_ "SigType" SG_ 2633803262 EngSparkPlug19MaxVoltage 1;
BA_ "SPN" SG_ 2633803262 EngSparkPlug19MaxVoltage 6264;
BA_ "SigType" SG_ 2633803262 EngSparkPlug18MaxVoltage 1;
BA_ "SPN" SG_ 2633803262 EngSparkPlug18MaxVoltage 6263;
BA_ "SigType" SG_ 2633803262 EngSparkPlug17MaxVoltage 1;
BA_ "SPN" SG_ 2633803262 EngSparkPlug17MaxVoltage 6262;
BA_ "SigType" SG_ 2633803006 EngSparkPlug24MaxVoltage 1;
BA_ "SPN" SG_ 2633803006 EngSparkPlug24MaxVoltage 6269;
BA_ "SigType" SG_ 2633803006 EngSparkPlug23MaxVoltage 1;
BA_ "SPN" SG_ 2633803006 EngSparkPlug23MaxVoltage 6268;
BA_ "SigType" SG_ 2633803006 EngSparkPlug22MaxVoltage 1;
BA_ "SPN" SG_ 2633803006 EngSparkPlug22MaxVoltage 6267;
BA_ "SigType" SG_ 2633803006 EngSparkPlug21MaxVoltage 1;
BA_ "SPN" SG_ 2633803006 EngSparkPlug21MaxVoltage 6266;
BA_ "SigType" SG_ 2633802750 EngSparkPlug8MisfireRate 1;
BA_ "SPN" SG_ 2633802750 EngSparkPlug8MisfireRate 6277;
BA_ "SigType" SG_ 2633802750 EngSparkPlug7MisfireRate 1;
BA_ "SPN" SG_ 2633802750 EngSparkPlug7MisfireRate 6276;
BA_ "SigType" SG_ 2633802750 EngSparkPlug6MisfireRate 1;
BA_ "SPN" SG_ 2633802750 EngSparkPlug6MisfireRate 6275;
BA_ "SigType" SG_ 2633802750 EngSparkPlug5MisfireRate 1;
BA_ "SPN" SG_ 2633802750 EngSparkPlug5MisfireRate 6274;
BA_ "SigType" SG_ 2633802750 EngSparkPlug4MisfireRate 1;
BA_ "SPN" SG_ 2633802750 EngSparkPlug4MisfireRate 6273;
BA_ "SigType" SG_ 2633802750 EngSparkPlug3MisfireRate 1;
BA_ "SPN" SG_ 2633802750 EngSparkPlug3MisfireRate 6272;
BA_ "SigType" SG_ 2633802750 EngSparkPlug2MisfireRate 1;
BA_ "SPN" SG_ 2633802750 EngSparkPlug2MisfireRate 6271;
BA_ "SigType" SG_ 2633802750 EngSparkPlug1MisfireRate 1;
BA_ "SPN" SG_ 2633802750 EngSparkPlug1MisfireRate 6270;
BA_ "SigType" SG_ 2633802494 EngSparkPlug16MisfireRate 1;
BA_ "SPN" SG_ 2633802494 EngSparkPlug16MisfireRate 6285;
BA_ "SigType" SG_ 2633802494 EngSparkPlug15MisfireRate 1;
BA_ "SPN" SG_ 2633802494 EngSparkPlug15MisfireRate 6284;
BA_ "SigType" SG_ 2633802494 EngSparkPlug14MisfireRate 1;
BA_ "SPN" SG_ 2633802494 EngSparkPlug14MisfireRate 6283;
BA_ "SigType" SG_ 2633802494 EngSparkPlug13MisfireRate 1;
BA_ "SPN" SG_ 2633802494 EngSparkPlug13MisfireRate 6282;
BA_ "SigType" SG_ 2633802494 EngSparkPlug12MisfireRate 1;
BA_ "SPN" SG_ 2633802494 EngSparkPlug12MisfireRate 6281;
BA_ "SigType" SG_ 2633802494 EngSparkPlug11MisfireRate 1;
BA_ "SPN" SG_ 2633802494 EngSparkPlug11MisfireRate 6280;
BA_ "SigType" SG_ 2633802494 EngSparkPlug10MisfireRate 1;
BA_ "SPN" SG_ 2633802494 EngSparkPlug10MisfireRate 6279;
BA_ "SigType" SG_ 2633802494 EngSparkPlug9MisfireRate 1;
BA_ "SPN" SG_ 2633802494 EngSparkPlug9MisfireRate 6278;
BA_ "SigType" SG_ 2633802238 EngSparkPlug24MisfireRate 1;
BA_ "SPN" SG_ 2633802238 EngSparkPlug24MisfireRate 6293;
BA_ "SigType" SG_ 2633802238 EngSparkPlug23MisfireRate 1;
BA_ "SPN" SG_ 2633802238 EngSparkPlug23MisfireRate 6292;
BA_ "SigType" SG_ 2633802238 EngSparkPlug22MisfireRate 1;
BA_ "SPN" SG_ 2633802238 EngSparkPlug22MisfireRate 6291;
BA_ "SigType" SG_ 2633802238 EngSparkPlug21MisfireRate 1;
BA_ "SPN" SG_ 2633802238 EngSparkPlug21MisfireRate 6290;
BA_ "SigType" SG_ 2633802238 EngSparkPlug20MisfireRate 1;
BA_ "SPN" SG_ 2633802238 EngSparkPlug20MisfireRate 6289;
BA_ "SigType" SG_ 2633802238 EngSparkPlug19MisfireRate 1;
BA_ "SPN" SG_ 2633802238 EngSparkPlug19MisfireRate 6288;
BA_ "SigType" SG_ 2633802238 EngSparkPlug18MisfireRate 1;
BA_ "SPN" SG_ 2633802238 EngSparkPlug18MisfireRate 6287;
BA_ "SigType" SG_ 2633802238 EngSparkPlug17MisfireRate 1;
BA_ "SPN" SG_ 2633802238 EngSparkPlug17MisfireRate 6286;
BA_ "SigType" SG_ 2633801982 EngTtlHoursOfDieselFuelOperation 1;
BA_ "SPN" SG_ 2633801982 EngTtlHoursOfDieselFuelOperation 6320;
BA_ "SigType" SG_ 2633801982 EngTotalHoursOfGasFuelOperation 1;
BA_ "SPN" SG_ 2633801982 EngTotalHoursOfGasFuelOperation 6319;
BA_ "SigType" SG_ 2566692862 DisplayRemainPowered 5;
BA_ "SPN" SG_ 2566692862 DisplayRemainPowered 6846;
BA_ "SigType" SG_ 2566692862 Fuel2Tank4Level 1;
BA_ "SPN" SG_ 2566692862 Fuel2Tank4Level 6645;
BA_ "SigType" SG_ 2566692862 Fuel2Tank3Level 1;
BA_ "SPN" SG_ 2566692862 Fuel2Tank3Level 6644;
BA_ "SigType" SG_ 2566692862 Fuel2Tank2Level 1;
BA_ "SPN" SG_ 2566692862 Fuel2Tank2Level 6643;
BA_ "SigType" SG_ 2566692862 Fuel2Tank1Level 1;
BA_ "SPN" SG_ 2566692862 Fuel2Tank1Level 6642;
BA_ "SigType" SG_ 2566692862 EngExRangeOilFilterDiffPress 1;
BA_ "SPN" SG_ 2566692862 EngExRangeOilFilterDiffPress 6321;
BA_ "SPN" SG_ 2499583742 EngTimingActuator2RequestedPos 6335;
BA_ "SPN" SG_ 2499583742 EngTimingActuator1RequestedPos 6334;
BA_ "SPN" SG_ 2499583742 EngTimingActuator2 1245;
BA_ "SPN" SG_ 2499583742 EngTimingActuator1 635;
BA_ "SPN" SG_ 2499583486 EngTimingActuator2PosCmd 6337;
BA_ "SPN" SG_ 2499583486 EngTimingActuator1PosCmd 6336;
BA_ "SigType" SG_ 2566692094 Joystick1Lamp10Status 5;
BA_ "SPN" SG_ 2566692094 Joystick1Lamp10Status 6347;
BA_ "SigType" SG_ 2566692094 Joystick1Lamp9Status 5;
BA_ "SPN" SG_ 2566692094 Joystick1Lamp9Status 6346;
BA_ "SigType" SG_ 2566692094 Joystick1Lamp8Status 5;
BA_ "SPN" SG_ 2566692094 Joystick1Lamp8Status 6345;
BA_ "SigType" SG_ 2566692094 Joystick1Lamp7Status 5;
BA_ "SPN" SG_ 2566692094 Joystick1Lamp7Status 6344;
BA_ "SigType" SG_ 2566692094 Joystick1Lamp6Status 5;
BA_ "SPN" SG_ 2566692094 Joystick1Lamp6Status 6343;
BA_ "SigType" SG_ 2566692094 Joystick1Lamp5Status 5;
BA_ "SPN" SG_ 2566692094 Joystick1Lamp5Status 6342;
BA_ "SigType" SG_ 2566692094 Joystick1Lamp4Status 5;
BA_ "SPN" SG_ 2566692094 Joystick1Lamp4Status 6341;
BA_ "SigType" SG_ 2566692094 Joystick1Lamp3Status 5;
BA_ "SPN" SG_ 2566692094 Joystick1Lamp3Status 6340;
BA_ "SigType" SG_ 2566692094 Joystick1Lamp2Status 5;
BA_ "SPN" SG_ 2566692094 Joystick1Lamp2Status 6339;
BA_ "SigType" SG_ 2566692094 Joystick1Lamp1Status 5;
BA_ "SPN" SG_ 2566692094 Joystick1Lamp1Status 6338;
BA_ "SigType" SG_ 2566691838 Joystick2Lamp10Status 5;
BA_ "SPN" SG_ 2566691838 Joystick2Lamp10Status 6357;
BA_ "SigType" SG_ 2566691838 Joystick2Lamp9Status 5;
BA_ "SPN" SG_ 2566691838 Joystick2Lamp9Status 6356;
BA_ "SigType" SG_ 2566691838 Joystick2Lamp8Status 5;
BA_ "SPN" SG_ 2566691838 Joystick2Lamp8Status 6355;
BA_ "SigType" SG_ 2566691838 Joystick2Lamp7Status 5;
BA_ "SPN" SG_ 2566691838 Joystick2Lamp7Status 6354;
BA_ "SigType" SG_ 2566691838 Joystick2Lamp6Status 5;
BA_ "SPN" SG_ 2566691838 Joystick2Lamp6Status 6353;
BA_ "SigType" SG_ 2566691838 Joystick2Lamp5Status 5;
BA_ "SPN" SG_ 2566691838 Joystick2Lamp5Status 6352;
BA_ "SigType" SG_ 2566691838 Joystick2Lamp4Status 5;
BA_ "SPN" SG_ 2566691838 Joystick2Lamp4Status 6351;
BA_ "SigType" SG_ 2566691838 Joystick2Lamp3Status 5;
BA_ "SPN" SG_ 2566691838 Joystick2Lamp3Status 6350;
BA_ "SigType" SG_ 2566691838 Joystick2Lamp2Status 5;
BA_ "SPN" SG_ 2566691838 Joystick2Lamp2Status 6349;
BA_ "SigType" SG_ 2566691838 Joystick2Lamp1Status 5;
BA_ "SPN" SG_ 2566691838 Joystick2Lamp1Status 6348;
BA_ "SigType" SG_ 2566691582 Joystick3Lamp10Status 5;
BA_ "SPN" SG_ 2566691582 Joystick3Lamp10Status 6367;
BA_ "SigType" SG_ 2566691582 Joystick3Lamp9Status 5;
BA_ "SPN" SG_ 2566691582 Joystick3Lamp9Status 6366;
BA_ "SigType" SG_ 2566691582 Joystick3Lamp8Status 5;
BA_ "SPN" SG_ 2566691582 Joystick3Lamp8Status 6365;
BA_ "SigType" SG_ 2566691582 Joystick3Lamp7Status 5;
BA_ "SPN" SG_ 2566691582 Joystick3Lamp7Status 6364;
BA_ "SigType" SG_ 2566691582 Joystick3Lamp6Status 5;
BA_ "SPN" SG_ 2566691582 Joystick3Lamp6Status 6363;
BA_ "SigType" SG_ 2566691582 Joystick3Lamp5Status 5;
BA_ "SPN" SG_ 2566691582 Joystick3Lamp5Status 6362;
BA_ "SigType" SG_ 2566691582 Joystick3Lamp4Status 5;
BA_ "SPN" SG_ 2566691582 Joystick3Lamp4Status 6361;
BA_ "SigType" SG_ 2566691582 Joystick3Lamp3Status 5;
BA_ "SPN" SG_ 2566691582 Joystick3Lamp3Status 6360;
BA_ "SigType" SG_ 2566691582 Joystick3Lamp2Status 5;
BA_ "SPN" SG_ 2566691582 Joystick3Lamp2Status 6359;
BA_ "SigType" SG_ 2566691582 Joystick3Lamp1Status 5;
BA_ "SPN" SG_ 2566691582 Joystick3Lamp1Status 6358;
BA_ "SigType" SG_ 2566691326 AssemblyUnitIdentification 8;
BA_ "SPN" SG_ 2566691326 AssemblyUnitIdentification 6369;
BA_ "SigType" SG_ 2566691326 NmbrOfAssmblyUntIdntfctionFields 1;
BA_ "SPN" SG_ 2566691326 NmbrOfAssmblyUntIdntfctionFields 6368;
BA_ "SigType" SG_ 2499582206 SftTpSpdLmtRmnngCntnsIntrvlDstnc 1;
BA_ "SPN" SG_ 2499582206 SftTpSpdLmtRmnngCntnsIntrvlDstnc 6914;
BA_ "SigType" SG_ 2499582206 SoftTopSpeedLimitResetDistance 1;
BA_ "SPN" SG_ 2499582206 SoftTopSpeedLimitResetDistance 6373;
BA_ "SigType" SG_ 2499582206 SftTpSpeedLimitRemainingDistance 1;
BA_ "SPN" SG_ 2499582206 SftTpSpeedLimitRemainingDistance 6372;
BA_ "SigType" SG_ 2499582206 SoftTopLifetimeLimitExceeded 5;
BA_ "SPN" SG_ 2499582206 SoftTopLifetimeLimitExceeded 6371;
BA_ "SigType" SG_ 2499582206 SoftTopSpeedLimitActive 5;
BA_ "SPN" SG_ 2499582206 SoftTopSpeedLimitActive 6370;
VAL_ 2566787838 AuxValve2FailSafeMode 3 "Not available" 2 "Error indication" 1 "Float" 0 "Block" ;
VAL_ 2566787838 AuxValve2State 15 "Don't Care" 3 "Floating" 2 "Retract" 1 "Extend" 0 "Blocked" ;
VAL_ 2566787582 AuxValve1FailSafeMode 3 "Not available" 2 "Error indication" 1 "Float" 0 "Block" ;
VAL_ 2566787582 AuxValve1State 15 "Don't Care" 3 "Floating" 2 "Retract" 1 "Extend" 0 "Blocked" ;
VAL_ 2566787326 AuxValve0FailSafeMode 3 "Not available" 2 "Error indication" 1 "Float" 0 "Block" ;
VAL_ 2566787326 AuxValve0State 15 "Don't Care" 3 "Floating" 2 "Retract" 1 "Extend" 0 "Blocked" ;
VAL_ 2566787070 DistanceUnitCmd 3 "No action" 2 "Reserved" 1 "Imperial" 0 "Metric" ;
VAL_ 2566787070 AreaUnitCmd 3 "No action" 2 "Reserved" 1 "Imperial" 0 "Metric" ;
VAL_ 2566787070 VolumeUnitCmd 3 "No action" 2 "US" 1 "Imperial" 0 "Metric" ;
VAL_ 2566787070 MassUnitCmd 3 "No action" 2 "Tons/pounds" 1 "Imperial" 0 "Metric" ;
VAL_ 2566787070 DecimalSymbolCmd 3 "No action" 2 "Reserved" 1 "Point is used" 0 "Comma is used" ;
VAL_ 2566787070 TimeCmd 3 "No action" 2 "Reserved" 1 "12 hour" 0 "24 hour" ;
VAL_ 2566786814 DataFormat_ErrorCondition 3 "Not Available or error" 2 "Data format is unsigned Long Integer" 1 "Data format is Floating" 0 "Data format is Long Integer" ;
VAL_ 2566786814 ProcessDataType 3 "Message is Actual value request" 2 "Message is Set Point request" 1 "Data is Actual values" 0 "Data is Set Point" ;
VAL_ 2566734846 MachineSelectedDirectionCmd 3 "Don't care" 2 "Reserved" 1 "Forward" 0 "Reverse" ;
VAL_ 2566734590 ISOBUSCmplncCrtfctLaboratoryType 7 "Not available" 2 "NA certified laboratory" 1 "EU certified laboratory" 0 "Non-certified laboratory/ self certification" ;
VAL_ 2566734590 ISOBUSCmplnceCertificateRevision 7 "Not available" 3 "Fourth Revision" 2 "Third Revision" 1 "Second Revision" 0 "First Revision" ;
VAL_ 2566718462 ImplementOperatingStateCmd 3 "Take no action" 2 "Set implement to park state" 1 "Set implement to transport state" 0 "Set implement to field working state" ;
VAL_ 2566718206 AllImplmntStpOprtngOprtnsSwtchSt 3 "Not available" 2 "Error indication" 1 "All implements stop operations switch ON" 0 "All implements stop operations switch OFF" ;
VAL_ 2499592190 TransShiftRail6ActuatorStatus 3 "not available" 2 "error" 1 "on" 0 "off" ;
VAL_ 2499592190 TransShiftRail5ActuatorStatus 3 "not available" 2 "error" 1 "on" 0 "off" ;
VAL_ 2499592190 TransShiftRail4ActuatorStatus 3 "not available" 2 "error" 1 "on" 0 "off" ;
VAL_ 2499592190 TransShiftRail3ActuatorStatus 3 "not available" 2 "error" 1 "on" 0 "off" ;
VAL_ 2499592190 TransShiftRail2ActuatorStatus 3 "not available" 2 "error" 1 "on" 0 "off" ;
VAL_ 2499592190 TransShiftRail1ActuatorStatus 3 "not available" 2 "error" 1 "on" 0 "off" ;
VAL_ 2499592190 TrnsClutch2CoolingActuatorStatus 3 "not available" 2 "error" 1 "on" 0 "off" ;
VAL_ 2499592190 TrnsClutch1CoolingActuatorStatus 3 "not available" 2 "error" 1 "on" 0 "off" ;
VAL_ 2566700030 DEFCtrlModule2PwrSupply2 3 "Unavailable" 2 "Error" 1 "On: The ECU is powering the DEF dosing unit power supply" 0 "Off" ;
VAL_ 2566700030 DEFCtrlModule2PwrSupply1 3 "Unavailable" 2 "Error" 1 "On: The ECU is powering the DEF dosing unit power supply" 0 "Off" ;
VAL_ 2566700030 DEFCtrlModule2RelayCtrl 3 "Unavailable" 2 "Error" 1 "On: The ECU is powering the DEF dosing unit relay" 0 "Off" ;
VAL_ 2566700030 DEFCtrlModuleCircuitBreaker 3 "not available" 2 "error" 1 "on" 0 "off" ;
VAL_ 2566700030 DEFCtrlModule1PwrSupply2 3 "Unavailable" 2 "Error" 1 "On: The ECU is powering the DEF dosing unit power supply" 0 "Off" ;
VAL_ 2566700030 DEFCtrlModule1PwrSupply1 3 "Unavailable" 2 "Error" 1 "On: The ECU is powering the DEF dosing unit power supply" 0 "Off" ;
VAL_ 2566700030 DEFCtrlModule1RelayCtrl 3 "Unavailable" 2 "Error" 1 "On: The ECU is powering the DEF dosing unit relay" 0 "Off" ;
VAL_ 2566699774 DEFCtrlModule2PwrSupply2 3 "Unavailable" 2 "Error" 1 "On: The ECU is powering the DEF dosing unit relay" 0 "Off" ;
VAL_ 2566699774 DEFCtrlModule2PwrSupply1 3 "Unavailable" 2 "Error" 1 "On: The ECU is powering the DEF dosing unit relay" 0 "Off" ;
VAL_ 2566699774 DEFCtrlModule2RelayCtrl 3 "Unavailable" 2 "Error" 1 "On: The ECU is powering the DEF dosing unit relay" 0 "Off" ;
VAL_ 2566699774 DEFCtrlModule1PwrSupply2 3 "Unavailable" 2 "Error" 1 "On: The ECU is powering the DEF dosing unit power supply" 0 "Off" ;
VAL_ 2566699774 DEFCtrlModule1PwrSupply1 3 "Unavailable" 2 "Error" 1 "On: The ECU is powering the DEF dosing unit power supply" 0 "Off" ;
VAL_ 2566699774 DEFCtrlModule1RelayCtrl 3 "Unavailable" 2 "Error" 1 "On: The ECU is powering the DEF dosing unit relay" 0 "Off" ;
VAL_ 2566698494 FusedOutput29 3 "Take no action" 2 "Reserved" 1 "Output powered" 0 "Output not powered" ;
VAL_ 2566698494 FusedOutput30 3 "Take no action" 2 "Reserved" 1 "Output powered" 0 "Output not powered" ;
VAL_ 2566698494 FusedOutput31 3 "Take no action" 2 "Reserved" 1 "Output powered" 0 "Output not powered" ;
VAL_ 2566698494 FusedOutput32 3 "Take no action" 2 "Reserved" 1 "Output powered" 0 "Output not powered" ;
VAL_ 2566698494 FusedOutput25 3 "Take no action" 2 "Reserved" 1 "Output powered" 0 "Output not powered" ;
VAL_ 2566698494 FusedOutput26 3 "Take no action" 2 "Reserved" 1 "Output powered" 0 "Output not powered" ;
VAL_ 2566698494 FusedOutput27 3 "Take no action" 2 "Reserved" 1 "Output powered" 0 "Output not powered" ;
VAL_ 2566698494 FusedOutput28 3 "Take no action" 2 "Reserved" 1 "Output powered" 0 "Output not powered" ;
VAL_ 2566698494 FusedOutput21 3 "Take no action" 2 "Reserved" 1 "Output powered" 0 "Output not powered" ;
VAL_ 2566698494 FusedOutput22 3 "Take no action" 2 "Reserved" 1 "Output powered" 0 "Output not powered" ;
VAL_ 2566698494 FusedOutput23 3 "Take no action" 2 "Reserved" 1 "Output powered" 0 "Output not powered" ;
VAL_ 2566698494 FusedOutput24 3 "Take no action" 2 "Reserved" 1 "Output powered" 0 "Output not powered" ;
VAL_ 2566698494 FusedOutput17 3 "Take no action" 2 "Reserved" 1 "Output powered" 0 "Output not powered" ;
VAL_ 2566698494 FusedOutput18 3 "Take no action" 2 "Reserved" 1 "Output powered" 0 "Output not powered" ;
VAL_ 2566698494 FusedOutput19 3 "Take no action" 2 "Reserved" 1 "Output powered" 0 "Output not powered" ;
VAL_ 2566698494 FusedOutput20 3 "Take no action" 2 "Reserved" 1 "Output powered" 0 "Output not powered" ;
VAL_ 2566698494 FusedOutput13 3 "Take no action" 2 "Reserved" 1 "Output powered" 0 "Output not powered" ;
VAL_ 2566698494 FusedOutput14 3 "Take no action" 2 "Reserved" 1 "Output powered" 0 "Output not powered" ;
VAL_ 2566698494 FusedOutput15 3 "Take no action" 2 "Reserved" 1 "Output powered" 0 "Output not powered" ;
VAL_ 2566698494 FusedOutput16 3 "Take no action" 2 "Reserved" 1 "Output powered" 0 "Output not powered" ;
VAL_ 2566698494 FusedOutput9 3 "Take no action" 2 "Reserved" 1 "Output powered" 0 "Output not powered" ;
VAL_ 2566698494 FusedOutput10 3 "Take no action" 2 "Reserved" 1 "Output powered" 0 "Output not powered" ;
VAL_ 2566698494 FusedOutput11 3 "Take no action" 2 "Reserved" 1 "Output powered" 0 "Output not powered" ;
VAL_ 2566698494 FusedOutput12 3 "Take no action" 2 "Reserved" 1 "Output powered" 0 "Output not powered" ;
VAL_ 2566698494 FusedOutput5 3 "Take no action" 2 "Reserved" 1 "Output powered" 0 "Output not powered" ;
VAL_ 2566698494 FusedOutput6 3 "Take no action" 2 "Reserved" 1 "Output powered" 0 "Output not powered" ;
VAL_ 2566698494 FusedOutput7 3 "Take no action" 2 "Reserved" 1 "Output powered" 0 "Output not powered" ;
VAL_ 2566698494 FusedOutput8 3 "Take no action" 2 "Reserved" 1 "Output powered" 0 "Output not powered" ;
VAL_ 2566698494 FusedOutput1 3 "Take no action" 2 "Reserved" 1 "Output powered" 0 "Output not powered" ;
VAL_ 2566698494 FusedOutput2 3 "Take no action" 2 "Reserved" 1 "Output powered" 0 "Output not powered" ;
VAL_ 2566698494 FusedOutput3 3 "Take no action" 2 "Reserved" 1 "Output powered" 0 "Output not powered" ;
VAL_ 2566698494 FusedOutput4 3 "Take no action" 2 "Reserved" 1 "Output powered" 0 "Output not powered" ;
VAL_ 2559115006 RadioBeaconDirection 3 "Don't Care" 2 "Reserved" 1 "Beacon Received Acknowledgement" 0 "Beacon Request" ;
VAL_ 2559770366 HydrocarbonDoserPurgingRequired 3 "Not available" 2 "Purging required, urgent" 1 "Purging required, less urgent" 0 "Purging not required" ;
VAL_ 2559770366 DiagnosticStatusOfHCDoser 7 "Not available" 6 "Error " 1 "Internal system test is in process" 0 "System test has executed and passed or System test has not yet executed" ;
VAL_ 2559770366 HCDoserInjectingStatus 3 "Not available" 2 "Error" 1 "Injecting active" 0 "Injecting not active" ;
VAL_ 2559770366 HCDoserStatus 7 "Not available" 6 "Error" 5 "SAE reserved" 4 "SAE reserved" 3 "HC doser enabled" 2 "SAE reserved" 1 "HC doser active" 0 "HC doser disabled" ;
VAL_ 2559704830 LubricationTimingCycleCmd 3 "Take no action     " 2 "Reserved " 1 "Enable" 0 "Pause" ;
VAL_ 2559704830 LubricationPumpEnableCmd 3 "Take no action" 2 "Reserved" 1 "Reset pump operation  " 0 "No action" ;
VAL_ 2559704830 LubricationOperationModeSetCmd 4 "Test Mode # 3" 3 "Test Mode # 2" 2 "Test Mode # 1" 1 "Manual Service Mode" 0 "Automatic Mode" 7 "Take no action" ;
VAL_ 2559704830 LubricationCycleSetCmd 7 "No action" 2 "Cycle mode # 3" 1 "Cycle mode # 2" 0 "Cycle mode # 1" ;
VAL_ 2559704830 LubricationCycleModeLockCmd 3 "No action" 2 "Reserved" 1 "Locked" 0 "Not Locked" ;
VAL_ 2559639294 SupplementalFanPowerHold 3 "Don't Care/Take no action" 2 "Reserved" 1 "Enable" 0 "Disable" ;
VAL_ 2559639294 SupplementalFanDirectionCmd 3 "Don't care/take no action" 2 "Reserved" 1 "Reverse" 0 "Forward" ;
VAL_ 2559639294 SupplementalFanEnableCmd 3 "Don't Care/Take no action" 2 "Reserved " 1 "Enable" 0 "Disable " ;
VAL_ 2559573758 ClntLvlEngPrtctnShtdwnOvrrideCmd 3 "Don't care/take no action" 2 "Reserved" 1 "Enable engine protection shutdown override due to low coolant level" 0 "Disable engine protection shutdown override due to low coolant level" ;
VAL_ 2349530878 CruiseCtrlPauseCmd 3 "Don't care/take no action" 2 "Reserved" 1 "Cruise Control is not allowed" 0 "Cruise Control is allowed" ;
VAL_ 2349530878 CruiseCtrlResumeCmd 3 "Don't Care/take no action" 2 "Reserved" 1 "Cruise Control Resume Requested" 0 "Cruise Control Resume not Requested" ;
VAL_ 2349530878 CruiseCtrlDisableCmd 3 "Don't care/take no action" 2 "Reserved" 1 "Cruise Control is not allowed" 0 "Cruise Control is allowed" ;
VAL_ 2566698238 SwitchedOutput29 3 "Take no action" 2 "Reserved" 1 "Output on" 0 "Output off" ;
VAL_ 2566698238 SwitchedOutput30 3 "Take no action" 2 "Reserved" 1 "Output on" 0 "Output off" ;
VAL_ 2566698238 SwitchedOutput31 3 "Take no action" 2 "Reserved" 1 "Output on" 0 "Output off" ;
VAL_ 2566698238 SwitchedOutput32 3 "Take no action" 2 "Reserved" 1 "Output on" 0 "Output off" ;
VAL_ 2566698238 SwitchedOutput25 3 "Take no action" 2 "Reserved" 1 "Output on" 0 "Output off" ;
VAL_ 2566698238 SwitchedOutput26 3 "Take no action" 2 "Reserved" 1 "Output on" 0 "Output off" ;
VAL_ 2566698238 SwitchedOutput27 3 "Take no action" 2 "Reserved" 1 "Output on" 0 "Output off" ;
VAL_ 2566698238 SwitchedOutput28 3 "Take no action" 2 "Reserved" 1 "Output on" 0 "Output off" ;
VAL_ 2566698238 SwitchedOutput21 3 "Take no action" 2 "Reserved" 1 "Output on" 0 "Output off" ;
VAL_ 2566698238 SwitchedOutput22 3 "Take no action" 2 "Reserved" 1 "Output on" 0 "Output off" ;
VAL_ 2566698238 SwitchedOutput23 3 "Take no action" 2 "Reserved" 1 "Output on" 0 "Output off" ;
VAL_ 2566698238 SwitchedOutput24 3 "Take no action" 2 "Reserved" 1 "Output on" 0 "Output off" ;
VAL_ 2566698238 SwitchedOutput17 3 "Take no action" 2 "Reserved" 1 "Output on" 0 "Output off" ;
VAL_ 2566698238 SwitchedOutput18 3 "Take no action" 2 "Reserved" 1 "Output on" 0 "Output off" ;
VAL_ 2566698238 SwitchedOutput19 3 "Take no action" 2 "Reserved" 1 "Output on" 0 "Output off" ;
VAL_ 2566698238 SwitchedOutput20 3 "Take no action" 2 "Reserved" 1 "Output on" 0 "Output off" ;
VAL_ 2566698238 SwitchedOutput13 3 "Take no action" 2 "Reserved" 1 "Output on" 0 "Output off" ;
VAL_ 2566698238 SwitchedOutput14 3 "Take no action" 2 "Reserved" 1 "Output on" 0 "Output off" ;
VAL_ 2566698238 SwitchedOutput15 0 "Output off" 3 "Take no action" 2 "Reserved" 1 "Output on" ;
VAL_ 2566698238 SwitchedOutput16 3 "Take no action" 2 "Reserved" 1 "Output on" 0 "Output off" ;
VAL_ 2566698238 SwitchedOutput9 3 "Take no action" 2 "Reserved" 1 "Output on" 0 "Output off" ;
VAL_ 2566698238 SwitchedOutput10 3 "Take no action" 2 "Reserved" 1 "Output on" 0 "Output off" ;
VAL_ 2566698238 SwitchedOutput11 3 "Take no action" 2 "Reserved" 1 "Output on" 0 "Output off" ;
VAL_ 2566698238 SwitchedOutput12 3 "Take no action" 2 "Reserved" 1 "Output on" 0 "Output off" ;
VAL_ 2566698238 SwitchedOutput5 3 "Take no action" 2 "Reserved" 1 "Output on" 0 "Output off" ;
VAL_ 2566698238 SwitchedOutput6 3 "Take no action" 2 "Reserved" 1 "Output on" 0 "Output off" ;
VAL_ 2566698238 SwitchedOutput7 3 "Take no action" 2 "Reserved" 1 "Output on" 0 "Output off" ;
VAL_ 2566698238 SwitchedOutput8 3 "Take no action" 2 "Reserved" 1 "Output on" 0 "Output off" ;
VAL_ 2566698238 SwitchedOutput1 3 "Take no action" 2 "Reserved" 1 "Output on" 0 "Output off" ;
VAL_ 2566698238 SwitchedOutput2 3 "Take no action" 2 "Reserved" 1 "Output on" 0 "Output off" ;
VAL_ 2566698238 SwitchedOutput3 3 "Take no action" 2 "Reserved" 1 "Output on" 0 "Output off" ;
VAL_ 2566698238 SwitchedOutput4 3 "Take no action" 2 "Reserved" 1 "Output on" 0 "Output off" ;
VAL_ 2566697470 EngIgntCtrlModule2State 7 "Not available" 6 "Error" 5 "Reserved" 4 "Firing Ignition in Normal Mode" 3 "Firing Ignition in Test Mode" 2 "Stalled" 1 "Shutdown" 0 "Disabled" ;
VAL_ 2566697470 EngIgntCtrlModule1State 7 "Not available" 6 "Error" 5 "Reserved" 4 "Firing Ignition in Normal Mode" 3 "Firing Ignition in Test Mode" 2 "Stalled" 1 "Shutdown" 0 "Disabled" ;
VAL_ 2566692862 DisplayRemainPowered 3 "Don't care" 2 "Reserved" 1 "Remain Powered" 0 "OK to Shutoff" ;
VAL_ 2499583742 EngTimingActuator2RequestedPos 7 "Not Available" 4 "Diesel Part Load / Gas Mode Position" 3 "Gas Mode Position" 2 "Diesel Part Load Position" 1 "Diesel Mode Position" 0 "Position Not Requested" ;
VAL_ 2499583742 EngTimingActuator1RequestedPos 7 "Not Available" 4 "Diesel Part Load / Gas Mode Position" 3 "Gas Mode Position" 2 "Diesel Part Load Position" 1 "Diesel Mode Position" 0 "Position Not Requested" ;
VAL_ 2499583742 EngTimingActuator2 7 "Not Available" 4 "Diesel Part Load / Gas Mode Position" 3 "Gas Mode Position" 2 "Diesel Part Load Position" 1 "Diesel Mode Position" 0 "Unknown Position" ;
VAL_ 2499583742 EngTimingActuator1 7 "Not Available" 4 "Diesel Part Load / Gas Mode Position" 3 "Gas Mode Position" 2 "Diesel Part Load Position" 1 "Diesel Mode Position" 0 "Unknown Position" ;
VAL_ 2499583486 EngTimingActuator2PosCmd 7 "Not Available" 4 "Diesel Part Load / Gas Mode Position" 3 "Gas Mode Position" 2 "Diesel Part Load Position" 1 "Diesel Mode Position" 0 "Reserved" ;
VAL_ 2499583486 EngTimingActuator1PosCmd 7 "Not Available" 4 "Diesel Part Load / Gas Mode Position" 3 "Gas Mode Position" 2 "Diesel Part Load Position" 1 "Diesel Mode Position" 0 "Reserved" ;
VAL_ 2566692094 Joystick1Lamp10Status 3 "Not available" 2 "Flashing" 1 "On" 0 "Off" ;
VAL_ 2566692094 Joystick1Lamp9Status 3 "Not available" 2 "Flashing" 1 "On" 0 "Off" ;
VAL_ 2566692094 Joystick1Lamp8Status 3 "Not available" 2 "Flashing" 1 "On" 0 "Off" ;
VAL_ 2566692094 Joystick1Lamp7Status 3 "Not available" 2 "Flashing" 1 "On" 0 "Off" ;
VAL_ 2566692094 Joystick1Lamp6Status 3 "Not available" 2 "Flashing" 1 "On" 0 "Off" ;
VAL_ 2566692094 Joystick1Lamp5Status 3 "Not available" 2 "Flashing" 1 "On" 0 "Off" ;
VAL_ 2566692094 Joystick1Lamp4Status 3 "Not available" 2 "Flashing" 1 "On" 0 "Off" ;
VAL_ 2566692094 Joystick1Lamp3Status 3 "Not available" 2 "Flashing" 1 "On" 0 "Off" ;
VAL_ 2566692094 Joystick1Lamp2Status 3 "Not available" 2 "Flashing" 1 "On" 0 "Off" ;
VAL_ 2566692094 Joystick1Lamp1Status 3 "Not available" 2 "Flashing" 1 "On" 0 "Off" ;
VAL_ 2566691838 Joystick2Lamp10Status 3 "Not available" 2 "Flashing" 1 "On" 0 "Off" ;
VAL_ 2566691838 Joystick2Lamp9Status 3 "Not available" 2 "Flashing" 1 "On" 0 "Off" ;
VAL_ 2566691838 Joystick2Lamp8Status 3 "Not available" 2 "Flashing" 1 "On" 0 "Off" ;
VAL_ 2566691838 Joystick2Lamp7Status 3 "Not available" 2 "Flashing" 1 "On" 0 "Off" ;
VAL_ 2566691838 Joystick2Lamp6Status 3 "Not available" 2 "Flashing" 1 "On" 0 "Off" ;
VAL_ 2566691838 Joystick2Lamp5Status 1 "On" 0 "Off" 3 "Not available" 2 "Flashing" ;
VAL_ 2566691838 Joystick2Lamp4Status 3 "Not available" 2 "Flashing" 1 "On" 0 "Off" ;
VAL_ 2566691838 Joystick2Lamp3Status 3 "Not available" 2 "Flashing" 1 "On" 0 "Off" ;
VAL_ 2566691838 Joystick2Lamp2Status 3 "Not available" 2 "Flashing" 1 "On" 0 "Off" ;
VAL_ 2566691838 Joystick2Lamp1Status 3 "Not available" 2 "Flashing" 1 "On" 0 "Off" ;
VAL_ 2566691582 Joystick3Lamp10Status 3 "Not available" 2 "Flashing" 1 "On" 0 "Off" ;
VAL_ 2566691582 Joystick3Lamp9Status 3 "Not available" 2 "Flashing" 1 "On" 0 "Off" ;
VAL_ 2566691582 Joystick3Lamp8Status 3 "Not available" 2 "Flashing" 1 "On" 0 "Off" ;
VAL_ 2566691582 Joystick3Lamp7Status 3 "Not available" 2 "Flashing" 1 "On" 0 "Off" ;
VAL_ 2566691582 Joystick3Lamp6Status 3 "Not available" 2 "Flashing" 1 "On" 0 "Off" ;
VAL_ 2566691582 Joystick3Lamp5Status 3 "Not available" 2 "Flashing" 1 "On" 0 "Off" ;
VAL_ 2566691582 Joystick3Lamp4Status 3 "Not available" 2 "Flashing" 1 "On" 0 "Off" ;
VAL_ 2566691582 Joystick3Lamp3Status 3 "Not available" 2 "Flashing" 1 "On" 0 "Off" ;
VAL_ 2566691582 Joystick3Lamp2Status 3 "Not available" 2 "Flashing" 1 "On" 0 "Off" ;
VAL_ 2566691582 Joystick3Lamp1Status 3 "Not available" 2 "Flashing" 1 "On" 0 "Off" ;
VAL_ 2499582206 SoftTopLifetimeLimitExceeded 3 "Not Available" 2 "Reserved" 1 "Soft top ratio limit has been exceeded" 0 "Soft top ratio limit has not been exceeded" ;
VAL_ 2499582206 SoftTopSpeedLimitActive 3 "Not Available" 2 "Reserved" 1 "Soft Top Speed Limit is Active" 0 "Soft Top Speed Limit is Inactive" ;
